// *************************************************************************** *
// *                                                                           *
// *                      Mentor Graphics Corporation                          *
// *                          All rights reserved                              *
// *                                                                           *
// *************************************************************************** *
// *                                                                           *
// * Description:         CANDB File                                           *
// * Generated at:        2020-04-14 13:10:23                                  *
// * System:              SDB20010                                             *
// * Variant:             EX11_AVP                                             *
// * Network:             ChassisCAN1                                          *
// *                                                                           *
// *************************************************************************** *
// *                                                                           *
// *             THIS CONFIGURATION MIGHT CONTAIN SOME ERRORS                  *
// *              IF THE INPUT MODEL WAS NOT PROPERLY FORMED!                  *
// *                    Do Not Use this File directly!                         *
// *                                                                           *
// *************************************************************************** *
VERSION "ChassisCAN1"

NS_ :

BS_:

BU_:  ASDM ECM ETC MVEM PAS PSCM1 SAS TCM VDDM

BO_ 293 TcmChas1Fr05: 8 TCM
 SG_ TrsmCluOpen1 : 24|1@0+ (1,0) [0|1] "" ECM
 SG_ TrsmCluOpen1_UB : 25|1@0+ (1,0) [0|1] "" ECM
 SG_ TrsmCluOpen2 : 26|1@0+ (1,0) [0|1] "" ECM
 SG_ TrsmCluOpen2_UB : 27|1@0+ (1,0) [0|1] "" ECM
 SG_ TrsmEcuTLvl : 29|2@0+ (1,0) [0|3] "" ECM
 SG_ TrsmEcuTLvl_UB : 7|1@0+ (1,0) [0|1] "" ECM
 SG_ TrsmGearSafe_UB : 6|1@0+ (1,0) [0|1] "" ECM
 SG_ TrsmGearSafeAct1 : 15|4@0+ (1,0) [0|15] "" ECM
 SG_ TrsmGearSafeAct2 : 11|4@0+ (1,0) [0|15] "" ECM
 SG_ TrsmGearSafeChks : 23|8@0+ (1.0,0.0) [0.0|255.0] "Unitless" ECM
 SG_ TrsmGearSafeCntr : 3|4@0+ (1.0,0.0) [0.0|15.0] "Unitless" ECM
 SG_ TrsmGearSafeSts1 : 4|1@0+ (1,0) [0|1] "" ECM
 SG_ TrsmGearSafeSts2 : 5|1@0+ (1,0) [0|1] "" ECM
 SG_ TrsmSailSts_UB : 47|1@0+ (1,0) [0|1] "" ECM
 SG_ TrsmSailStsTrsmEngSyncSpd : 55|16@0+ (1.0,0.0) [0.0|65534.0] "rpm" ECM
 SG_ TrsmSailStsTrsmSailAllwd : 46|1@0+ (1,0) [0|1] "" ECM
 SG_ TrsmSailStsTrsmShiftMapForIsg : 42|3@0+ (1,0) [0|7] "" ECM
 SG_ TrsmSailStsTrsmSts : 45|3@0+ (1,0) [0|7] "" ECM

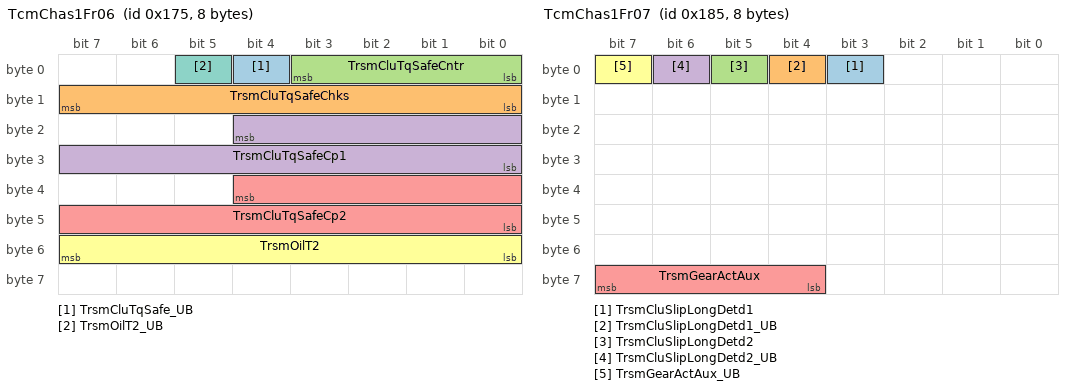
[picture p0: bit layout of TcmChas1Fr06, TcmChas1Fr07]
BO_ 373 TcmChas1Fr06: 8 TCM
 SG_ TrsmCluTqSafe_UB : 4|1@0+ (1,0) [0|1] "" ECM
 SG_ TrsmCluTqSafeChks : 15|8@0+ (1.0,0.0) [0.0|255.0] "Unitless" ECM
 SG_ TrsmCluTqSafeCntr : 3|4@0+ (1.0,0.0) [0.0|15.0] "Unitless" ECM
 SG_ TrsmCluTqSafeCp1 : 20|13@0+ (0.1,-5.0) [-5.0|814.1] "NewtonMeter" ECM
 SG_ TrsmCluTqSafeCp2 : 36|13@0+ (0.1,-5.0) [-5.0|814.1] "NewtonMeter" ECM
 SG_ TrsmOilT2 : 55|8@0+ (1.0,-60.0) [-60.0|195.0] "degC" ECM,VDDM
 SG_ TrsmOilT2_UB : 5|1@0+ (1,0) [0|1] "" ECM,VDDM

BO_ 389 TcmChas1Fr07: 8 TCM
 SG_ TrsmCluSlipLongDetd1 : 3|1@0+ (1,0) [0|1] "" ECM
 SG_ TrsmCluSlipLongDetd1_UB : 4|1@0+ (1,0) [0|1] "" ECM
 SG_ TrsmCluSlipLongDetd2 : 5|1@0+ (1,0) [0|1] "" ECM
 SG_ TrsmCluSlipLongDetd2_UB : 6|1@0+ (1,0) [0|1] "" ECM
 SG_ TrsmGearActAux : 63|4@0+ (1,0) [0|15] "" ECM
 SG_ TrsmGearActAux_UB : 7|1@0+ (1,0) [0|1] "" ECM

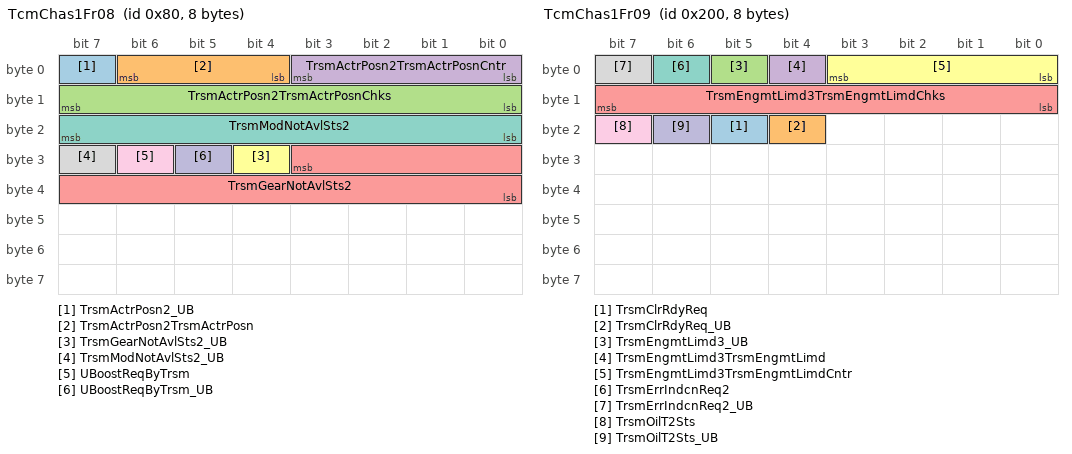
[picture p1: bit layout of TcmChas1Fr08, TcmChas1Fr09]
BO_ 128 TcmChas1Fr08: 8 TCM
 SG_ TrsmActrPosn2_UB : 7|1@0+ (1,0) [0|1] "" ECM
 SG_ TrsmActrPosn2TrsmActrPosn : 6|3@0+ (1,0) [0|7] "" ECM
 SG_ TrsmActrPosn2TrsmActrPosnChks : 15|8@0+ (1.0,0.0) [0.0|255.0] "Unitless" ECM
 SG_ TrsmActrPosn2TrsmActrPosnCntr : 3|4@0+ (1.0,0.0) [0.0|15.0] "Unitless" ECM
 SG_ TrsmGearNotAvlSts2 : 27|12@0+ (1.0,0.0) [0.0|4095.0] "Unitless" ECM
 SG_ TrsmGearNotAvlSts2_UB : 28|1@0+ (1,0) [0|1] "" ECM
 SG_ TrsmModNotAvlSts2 : 23|8@0+ (1.0,0.0) [0.0|255.0] "Unitless" ECM
 SG_ TrsmModNotAvlSts2_UB : 31|1@0+ (1,0) [0|1] "" ECM
 SG_ UBoostReqByTrsm : 30|1@0+ (1,0) [0|1] "" ECM
 SG_ UBoostReqByTrsm_UB : 29|1@0+ (1,0) [0|1] "" ECM

BO_ 512 TcmChas1Fr09: 8 TCM
 SG_ TrsmClrRdyReq : 21|1@0+ (1,0) [0|1] "" ECM
 SG_ TrsmClrRdyReq_UB : 20|1@0+ (1,0) [0|1] "" ECM
 SG_ TrsmEngmtLimd3_UB : 5|1@0+ (1,0) [0|1] "" ECM
 SG_ TrsmEngmtLimd3TrsmEngmtLimd : 4|1@0+ (1,0) [0|1] "" ECM
 SG_ TrsmEngmtLimd3TrsmEngmtLimdChks : 15|8@0+ (1.0,0.0) [0.0|255.0] "Unitless" ECM
 SG_ TrsmEngmtLimd3TrsmEngmtLimdCntr : 3|4@0+ (1.0,0.0) [0.0|15.0] "Unitless" ECM
 SG_ TrsmErrIndcnReq2 : 6|1@0+ (1,0) [0|1] "" ECM
 SG_ TrsmErrIndcnReq2_UB : 7|1@0+ (1,0) [0|1] "" ECM
 SG_ TrsmOilT2Sts : 23|1@0+ (1,0) [0|1] "" ECM
 SG_ TrsmOilT2Sts_UB : 22|1@0+ (1,0) [0|1] "" ECM

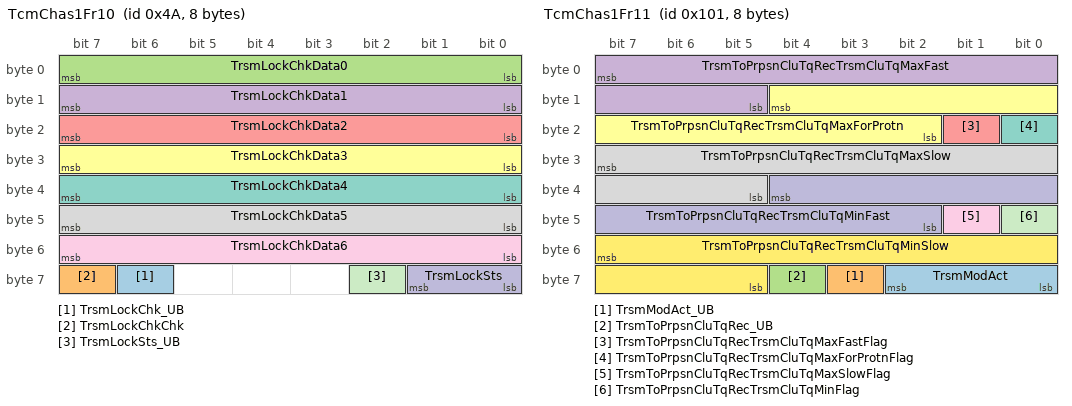
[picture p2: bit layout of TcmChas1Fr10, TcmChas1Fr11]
BO_ 74 TcmChas1Fr10: 8 TCM
 SG_ TrsmLockChk_UB : 62|1@0+ (1,0) [0|1] "" VDDM
 SG_ TrsmLockChkChk : 63|1@0+ (1,0) [0|1] "" VDDM
 SG_ TrsmLockChkData0 : 7|8@0+ (1.0,0.0) [0.0|255.0] "Unitless" VDDM
 SG_ TrsmLockChkData1 : 15|8@0+ (1.0,0.0) [0.0|255.0] "Unitless" VDDM
 SG_ TrsmLockChkData2 : 23|8@0+ (1.0,0.0) [0.0|255.0] "Unitless" VDDM
 SG_ TrsmLockChkData3 : 31|8@0+ (1.0,0.0) [0.0|255.0] "Unitless" VDDM
 SG_ TrsmLockChkData4 : 39|8@0+ (1.0,0.0) [0.0|255.0] "Unitless" VDDM
 SG_ TrsmLockChkData5 : 47|8@0+ (1.0,0.0) [0.0|255.0] "Unitless" VDDM
 SG_ TrsmLockChkData6 : 55|8@0+ (1.0,0.0) [0.0|255.0] "Unitless" VDDM
 SG_ TrsmLockSts : 57|2@0+ (1,0) [0|3] "" VDDM
 SG_ TrsmLockSts_UB : 58|1@0+ (1,0) [0|1] "" VDDM

BO_ 257 TcmChas1Fr11: 8 TCM
 SG_ TrsmModAct : 58|3@0+ (1,0) [0|7] "" ECM
 SG_ TrsmModAct_UB : 59|1@0+ (1,0) [0|1] "" ECM
 SG_ TrsmToPrpsnCluTqRec_UB : 60|1@0+ (1,0) [0|1] "" ECM
 SG_ TrsmToPrpsnCluTqRecTrsmCluTqMaxFast : 7|11@0+ (1.0,-1024.0) [-1024.0|1023.0] "NewtonMeter" ECM
 SG_ TrsmToPrpsnCluTqRecTrsmCluTqMaxFastFlag : 17|1@0+ (1,0) [0|1] "" ECM
 SG_ TrsmToPrpsnCluTqRecTrsmCluTqMaxForProtn : 12|11@0+ (1.0,-1024.0) [-1024.0|1023.0] "NewtonMeter" ECM
 SG_ TrsmToPrpsnCluTqRecTrsmCluTqMaxForProtnFlag : 16|1@0+ (1,0) [0|1] "" ECM
 SG_ TrsmToPrpsnCluTqRecTrsmCluTqMaxSlow : 31|11@0+ (1.0,-1024.0) [-1024.0|1023.0] "NewtonMeter" ECM
 SG_ TrsmToPrpsnCluTqRecTrsmCluTqMaxSlowFlag : 41|1@0+ (1,0) [0|1] "" ECM
 SG_ TrsmToPrpsnCluTqRecTrsmCluTqMinFast : 36|11@0+ (1.0,-1024.0) [-1024.0|1023.0] "NewtonMeter" ECM
 SG_ TrsmToPrpsnCluTqRecTrsmCluTqMinFlag : 40|1@0+ (1,0) [0|1] "" ECM
 SG_ TrsmToPrpsnCluTqRecTrsmCluTqMinSlow : 55|11@0+ (1.0,-1024.0) [-1024.0|1023.0] "NewtonMeter" ECM

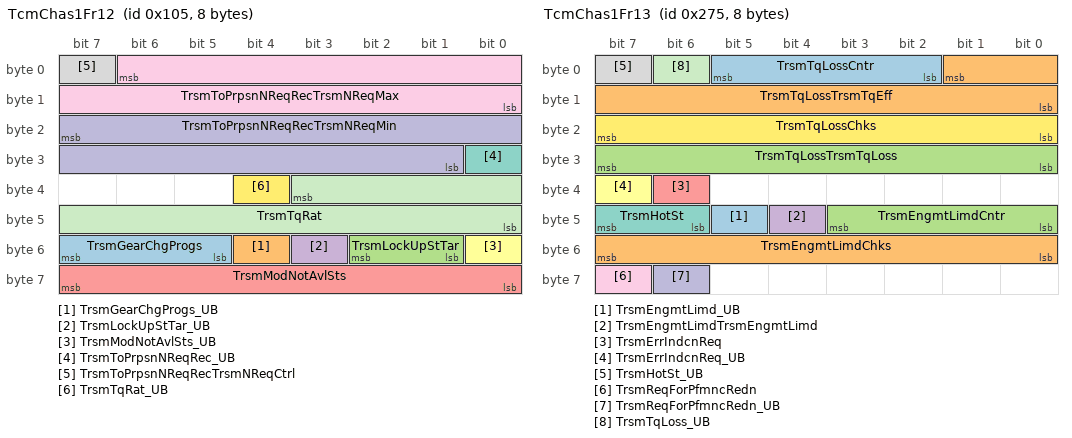
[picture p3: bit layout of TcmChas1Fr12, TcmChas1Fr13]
BO_ 261 TcmChas1Fr12: 8 TCM
 SG_ TrsmGearChgProgs : 55|3@0+ (1,0) [0|7] "" ECM
 SG_ TrsmGearChgProgs_UB : 52|1@0+ (1,0) [0|1] "" ECM
 SG_ TrsmLockUpStTar : 50|2@0+ (1,0) [0|3] "" ECM
 SG_ TrsmLockUpStTar_UB : 51|1@0+ (1,0) [0|1] "" ECM
 SG_ TrsmModNotAvlSts : 63|8@0+ (1.0,0.0) [0.0|255.0] "Unitless" ECM
 SG_ TrsmModNotAvlSts_UB : 48|1@0+ (1,0) [0|1] "" ECM
 SG_ TrsmToPrpsnNReqRec_UB : 24|1@0+ (1,0) [0|1] "" ECM
 SG_ TrsmToPrpsnNReqRecTrsmNReqCtrl : 7|1@0+ (1,0) [0|1] "" ECM
 SG_ TrsmToPrpsnNReqRecTrsmNReqMax : 6|15@0+ (0.5,0.0) [0.0|16383.5] "rpm" ECM
 SG_ TrsmToPrpsnNReqRecTrsmNReqMin : 23|15@0+ (0.5,0.0) [0.0|16383.5] "rpm" ECM
 SG_ TrsmTqRat : 35|12@0+ (0.01,0.0) [0.0|40.95] "Unitless" ECM,VDDM
 SG_ TrsmTqRat_UB : 36|1@0+ (1,0) [0|1] "" ECM,VDDM

BO_ 629 TcmChas1Fr13: 8 TCM
 SG_ TrsmEngmtLimd_UB : 45|1@0+ (1,0) [0|1] "" ECM
 SG_ TrsmEngmtLimdChks : 55|8@0+ (1.0,0.0) [0.0|255.0] "Unitless" ECM
 SG_ TrsmEngmtLimdCntr : 43|4@0+ (1.0,0.0) [0.0|15.0] "Unitless" ECM
 SG_ TrsmEngmtLimdTrsmEngmtLimd : 44|1@0+ (1,0) [0|1] "" ECM
 SG_ TrsmErrIndcnReq : 38|1@0+ (1,0) [0|1] "" ECM
 SG_ TrsmErrIndcnReq_UB : 39|1@0+ (1,0) [0|1] "" ECM
 SG_ TrsmHotSt : 47|2@0+ (1,0) [0|3] "" ECM
 SG_ TrsmHotSt_UB : 7|1@0+ (1,0) [0|1] "" ECM
 SG_ TrsmReqForPfmncRedn : 63|1@0+ (1,0) [0|1] "" ECM
 SG_ TrsmReqForPfmncRedn_UB : 62|1@0+ (1,0) [0|1] "" ECM
 SG_ TrsmTqLoss_UB : 6|1@0+ (1,0) [0|1] "" ECM,VDDM
 SG_ TrsmTqLossChks : 23|8@0+ (1.0,0.0) [0.0|255.0] "Unitless" ECM,VDDM
 SG_ TrsmTqLossCntr : 5|4@0+ (1.0,0.0) [0.0|15.0] "Unitless" ECM,VDDM
 SG_ TrsmTqLossTrsmTqEff : 1|10@0+ (0.1,0.0) [0.0|100.0] "%" ECM,VDDM
 SG_ TrsmTqLossTrsmTqLoss : 31|8@0+ (0.5,0.0) [0.0|127.0] "Unitless" ECM,VDDM

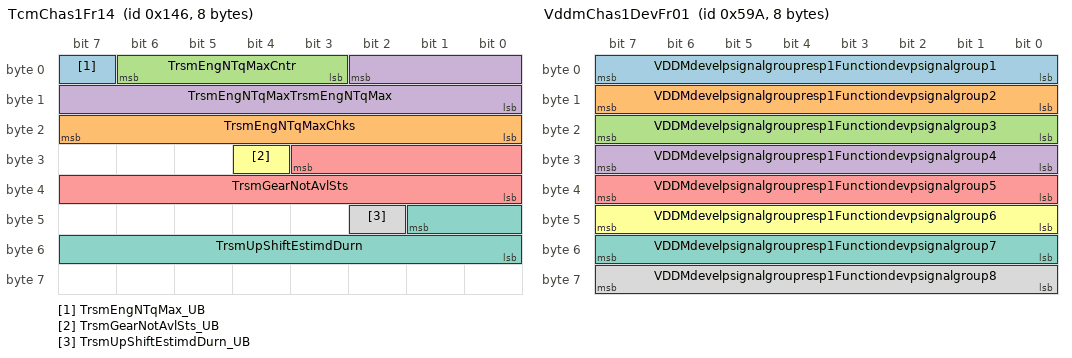
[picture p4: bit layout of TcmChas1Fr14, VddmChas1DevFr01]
BO_ 326 TcmChas1Fr14: 8 TCM
 SG_ TrsmEngNTqMax_UB : 7|1@0+ (1,0) [0|1] "" ECM
 SG_ TrsmEngNTqMaxChks : 23|8@0+ (1.0,0.0) [0.0|255.0] "Unitless" ECM
 SG_ TrsmEngNTqMaxCntr : 6|4@0+ (1.0,0.0) [0.0|15.0] "Unitless" ECM
 SG_ TrsmEngNTqMaxTrsmEngNTqMax : 2|11@0+ (1.0,-1024.0) [-1024.0|1023.0] "NewtonMeter" ECM
 SG_ TrsmGearNotAvlSts : 27|12@0+ (1.0,0.0) [0.0|4095.0] "Unitless" ECM
 SG_ TrsmGearNotAvlSts_UB : 28|1@0+ (1,0) [0|1] "" ECM
 SG_ TrsmUpShiftEstimdDurn : 41|10@0+ (10.0,0.0) [0.0|10230.0] "Milliseconds" ECM
 SG_ TrsmUpShiftEstimdDurn_UB : 42|1@0+ (1,0) [0|1] "" ECM

BO_ 263 TcmChas1Fr15: 8 TCM
 SG_ TrsmFltIndcn : 52|5@0+ (1,0) [0|31] "" ECM,VDDM
 SG_ TrsmFltIndcn_UB : 53|1@0+ (1,0) [0|1] "" ECM,VDDM

BO_ 763 TCMChas1Fr18: 8 TCM
 SG_ VFCVectorTCMAWBlockID : 1|2@0+ (1.0,0.0) [0.0|3.0] "Unitless" VDDM
 SG_ VFCVectorTCMAWVFCid0 : 2|1@0+ (1,0) [0|1] "" VDDM
 SG_ VFCVectorTCMAWVFCid1 : 3|1@0+ (1,0) [0|1] "" VDDM
 SG_ VFCVectorTCMAWVFCid10 : 12|1@0+ (1,0) [0|1] "" VDDM
 SG_ VFCVectorTCMAWVFCid11 : 13|1@0+ (1,0) [0|1] "" VDDM
 SG_ VFCVectorTCMAWVFCid12 : 14|1@0+ (1,0) [0|1] "" VDDM
 SG_ VFCVectorTCMAWVFCid13 : 15|1@0+ (1,0) [0|1] "" VDDM
 SG_ VFCVectorTCMAWVFCid14 : 16|1@0+ (1,0) [0|1] "" VDDM
 SG_ VFCVectorTCMAWVFCid15 : 17|1@0+ (1,0) [0|1] "" VDDM
 SG_ VFCVectorTCMAWVFCid16 : 18|1@0+ (1,0) [0|1] "" VDDM
 SG_ VFCVectorTCMAWVFCid17 : 19|1@0+ (1,0) [0|1] "" VDDM
 SG_ VFCVectorTCMAWVFCid18 : 20|1@0+ (1,0) [0|1] "" VDDM
 SG_ VFCVectorTCMAWVFCid19 : 21|1@0+ (1,0) [0|1] "" VDDM
 SG_ VFCVectorTCMAWVFCid2 : 4|1@0+ (1,0) [0|1] "" VDDM
 SG_ VFCVectorTCMAWVFCid20 : 22|1@0+ (1,0) [0|1] "" VDDM
 SG_ VFCVectorTCMAWVFCid21 : 23|1@0+ (1,0) [0|1] "" VDDM
 SG_ VFCVectorTCMAWVFCid22 : 24|1@0+ (1,0) [0|1] "" VDDM
 SG_ VFCVectorTCMAWVFCid23 : 25|1@0+ (1,0) [0|1] "" VDDM
 SG_ VFCVectorTCMAWVFCid24 : 26|1@0+ (1,0) [0|1] "" VDDM
 SG_ VFCVectorTCMAWVFCid25 : 27|1@0+ (1,0) [0|1] "" VDDM
 SG_ VFCVectorTCMAWVFCid26 : 28|1@0+ (1,0) [0|1] "" VDDM
 SG_ VFCVectorTCMAWVFCid27 : 29|1@0+ (1,0) [0|1] "" VDDM
 SG_ VFCVectorTCMAWVFCid28 : 30|1@0+ (1,0) [0|1] "" VDDM
 SG_ VFCVectorTCMAWVFCid29 : 31|1@0+ (1,0) [0|1] "" VDDM
 SG_ VFCVectorTCMAWVFCid3 : 5|1@0+ (1,0) [0|1] "" VDDM
 SG_ VFCVectorTCMAWVFCid30 : 32|1@0+ (1,0) [0|1] "" VDDM
 SG_ VFCVectorTCMAWVFCid31 : 33|1@0+ (1,0) [0|1] "" VDDM
 SG_ VFCVectorTCMAWVFCid32 : 34|1@0+ (1,0) [0|1] "" VDDM
 SG_ VFCVectorTCMAWVFCid33 : 35|1@0+ (1,0) [0|1] "" VDDM
 SG_ VFCVectorTCMAWVFCid34 : 36|1@0+ (1,0) [0|1] "" VDDM
 SG_ VFCVectorTCMAWVFCid35 : 37|1@0+ (1,0) [0|1] "" VDDM
 SG_ VFCVectorTCMAWVFCid36 : 38|1@0+ (1,0) [0|1] "" VDDM
 SG_ VFCVectorTCMAWVFCid37 : 39|1@0+ (1,0) [0|1] "" VDDM
 SG_ VFCVectorTCMAWVFCid38 : 40|1@0+ (1,0) [0|1] "" VDDM
 SG_ VFCVectorTCMAWVFCid39 : 41|1@0+ (1,0) [0|1] "" VDDM
 SG_ VFCVectorTCMAWVFCid4 : 6|1@0+ (1,0) [0|1] "" VDDM
 SG_ VFCVectorTCMAWVFCid40 : 42|1@0+ (1,0) [0|1] "" VDDM
 SG_ VFCVectorTCMAWVFCid41 : 43|1@0+ (1,0) [0|1] "" VDDM
 SG_ VFCVectorTCMAWVFCid42 : 44|1@0+ (1,0) [0|1] "" VDDM
 SG_ VFCVectorTCMAWVFCid43 : 45|1@0+ (1,0) [0|1] "" VDDM
 SG_ VFCVectorTCMAWVFCid44 : 46|1@0+ (1,0) [0|1] "" VDDM
 SG_ VFCVectorTCMAWVFCid45 : 47|1@0+ (1,0) [0|1] "" VDDM
 SG_ VFCVectorTCMAWVFCid46 : 48|1@0+ (1,0) [0|1] "" VDDM
 SG_ VFCVectorTCMAWVFCid47 : 49|1@0+ (1,0) [0|1] "" VDDM
 SG_ VFCVectorTCMAWVFCid48 : 50|1@0+ (1,0) [0|1] "" VDDM
 SG_ VFCVectorTCMAWVFCid49 : 51|1@0+ (1,0) [0|1] "" VDDM
 SG_ VFCVectorTCMAWVFCid5 : 7|1@0+ (1,0) [0|1] "" VDDM
 SG_ VFCVectorTCMAWVFCid50 : 52|1@0+ (1,0) [0|1] "" VDDM
 SG_ VFCVectorTCMAWVFCid51 : 53|1@0+ (1,0) [0|1] "" VDDM
 SG_ VFCVectorTCMAWVFCid52 : 54|1@0+ (1,0) [0|1] "" VDDM
 SG_ VFCVectorTCMAWVFCid53 : 55|1@0+ (1,0) [0|1] "" VDDM
 SG_ VFCVectorTCMAWVFCid54 : 56|1@0+ (1,0) [0|1] "" VDDM
 SG_ VFCVectorTCMAWVFCid55 : 57|1@0+ (1,0) [0|1] "" VDDM
 SG_ VFCVectorTCMAWVFCid56 : 58|1@0+ (1,0) [0|1] "" VDDM
 SG_ VFCVectorTCMAWVFCid57 : 59|1@0+ (1,0) [0|1] "" VDDM
 SG_ VFCVectorTCMAWVFCid58 : 60|1@0+ (1,0) [0|1] "" VDDM
 SG_ VFCVectorTCMAWVFCid59 : 61|1@0+ (1,0) [0|1] "" VDDM
 SG_ VFCVectorTCMAWVFCid6 : 8|1@0+ (1,0) [0|1] "" VDDM
 SG_ VFCVectorTCMAWVFCid60 : 62|1@0+ (1,0) [0|1] "" VDDM
 SG_ VFCVectorTCMAWVFCid61 : 63|1@0+ (1,0) [0|1] "" VDDM
 SG_ VFCVectorTCMAWVFCid7 : 9|1@0+ (1,0) [0|1] "" VDDM
 SG_ VFCVectorTCMAWVFCid8 : 10|1@0+ (1,0) [0|1] "" VDDM
 SG_ VFCVectorTCMAWVFCid9 : 11|1@0+ (1,0) [0|1] "" VDDM

BO_ 1328 TcmChas1NMFr: 8 TCM
 SG_ PNC16_TCM : 16|1@0+ (1,0) [0|0] "" SAS
 SG_ PNC17_TCM : 17|1@0+ (1,0) [0|0] "" SAS
 SG_ PNC18_TCM : 18|1@0+ (1,0) [0|0] "" SAS
 SG_ PNC19_TCM : 19|1@0+ (1,0) [0|0] "" SAS
 SG_ PNC20_TCM : 20|1@0+ (1,0) [0|0] "" SAS
 SG_ PNC21_TCM : 21|1@0+ (1,0) [0|0] "" SAS
 SG_ PNC22_TCM : 22|1@0+ (1,0) [0|0] "" SAS
 SG_ PNC23_TCM : 23|1@0+ (1,0) [0|0] "" SAS
 SG_ PNC24_TCM : 24|1@0+ (1,0) [0|0] "" SAS
 SG_ PNC25_TCM : 25|1@0+ (1,0) [0|0] "" SAS
 SG_ PNC26_TCM : 26|1@0+ (1,0) [0|0] "" SAS
 SG_ PNC27_TCM : 27|1@0+ (1,0) [0|0] "" SAS
 SG_ PNC28_TCM : 28|1@0+ (1,0) [0|0] "" SAS
 SG_ PNC29_TCM : 29|1@0+ (1,0) [0|0] "" SAS
 SG_ PNC30_TCM : 30|1@0+ (1,0) [0|0] "" SAS
 SG_ PNC31_TCM : 31|1@0+ (1,0) [0|0] "" SAS
 SG_ PNC32_TCM : 32|1@0+ (1,0) [0|0] "" SAS
 SG_ PNC33_TCM : 33|1@0+ (1,0) [0|0] "" SAS
 SG_ PNC34_TCM : 34|1@0+ (1,0) [0|0] "" SAS
 SG_ PNC35_TCM : 35|1@0+ (1,0) [0|0] "" SAS
 SG_ PNC36_TCM : 36|1@0+ (1,0) [0|0] "" SAS
 SG_ PNC37_TCM : 37|1@0+ (1,0) [0|0] "" SAS
 SG_ PNC38_TCM : 38|1@0+ (1,0) [0|0] "" SAS
 SG_ PNC39_TCM : 39|1@0+ (1,0) [0|0] "" SAS
 SG_ NM_PNI_TCM : 14|1@0+ (1,0) [0|0] "" SAS
 SG_ NM_AW_TCM : 12|1@0+ (1,0) [0|0] "" SAS
 SG_ NM_CS_TCM : 11|1@0+ (1,0) [0|0] "" SAS
 SG_ NM_RMR_TCM : 8|1@0+ (1,0) [0|0] "" SAS
 SG_ NM_NodeID_TCM : 7|8@0+ (1,0) [0|0] "" SAS

BO_ 1352 TCMChas1VFCVectorFr: 8 TCM
 SG_ VFCVectorTCMBlockID : 1|2@0+ (1.0,0.0) [0.0|3.0] "Unitless" ETC
 SG_ VFCVectorTCMVFCid0 : 2|1@0+ (1,0) [0|1] "" ETC
 SG_ VFCVectorTCMVFCid1 : 3|1@0+ (1,0) [0|1] "" ETC
 SG_ VFCVectorTCMVFCid10 : 12|1@0+ (1,0) [0|1] "" ETC
 SG_ VFCVectorTCMVFCid11 : 13|1@0+ (1,0) [0|1] "" ETC
 SG_ VFCVectorTCMVFCid12 : 14|1@0+ (1,0) [0|1] "" ETC
 SG_ VFCVectorTCMVFCid13 : 15|1@0+ (1,0) [0|1] "" ETC
 SG_ VFCVectorTCMVFCid14 : 16|1@0+ (1,0) [0|1] "" ETC
 SG_ VFCVectorTCMVFCid15 : 17|1@0+ (1,0) [0|1] "" ETC
 SG_ VFCVectorTCMVFCid16 : 18|1@0+ (1,0) [0|1] "" ETC
 SG_ VFCVectorTCMVFCid17 : 19|1@0+ (1,0) [0|1] "" ETC
 SG_ VFCVectorTCMVFCid18 : 20|1@0+ (1,0) [0|1] "" ETC
 SG_ VFCVectorTCMVFCid19 : 21|1@0+ (1,0) [0|1] "" ETC
 SG_ VFCVectorTCMVFCid2 : 4|1@0+ (1,0) [0|1] "" ETC
 SG_ VFCVectorTCMVFCid20 : 22|1@0+ (1,0) [0|1] "" ETC
 SG_ VFCVectorTCMVFCid21 : 23|1@0+ (1,0) [0|1] "" ETC
 SG_ VFCVectorTCMVFCid22 : 24|1@0+ (1,0) [0|1] "" ETC
 SG_ VFCVectorTCMVFCid23 : 25|1@0+ (1,0) [0|1] "" ETC
 SG_ VFCVectorTCMVFCid24 : 26|1@0+ (1,0) [0|1] "" ETC
 SG_ VFCVectorTCMVFCid25 : 27|1@0+ (1,0) [0|1] "" ETC
 SG_ VFCVectorTCMVFCid26 : 28|1@0+ (1,0) [0|1] "" ETC
 SG_ VFCVectorTCMVFCid27 : 29|1@0+ (1,0) [0|1] "" ETC
 SG_ VFCVectorTCMVFCid28 : 30|1@0+ (1,0) [0|1] "" ETC
 SG_ VFCVectorTCMVFCid29 : 31|1@0+ (1,0) [0|1] "" ETC
 SG_ VFCVectorTCMVFCid3 : 5|1@0+ (1,0) [0|1] "" ETC
 SG_ VFCVectorTCMVFCid30 : 32|1@0+ (1,0) [0|1] "" ETC
 SG_ VFCVectorTCMVFCid31 : 33|1@0+ (1,0) [0|1] "" ETC
 SG_ VFCVectorTCMVFCid32 : 34|1@0+ (1,0) [0|1] "" ETC
 SG_ VFCVectorTCMVFCid33 : 35|1@0+ (1,0) [0|1] "" ETC
 SG_ VFCVectorTCMVFCid34 : 36|1@0+ (1,0) [0|1] "" ETC
 SG_ VFCVectorTCMVFCid35 : 37|1@0+ (1,0) [0|1] "" ETC
 SG_ VFCVectorTCMVFCid36 : 38|1@0+ (1,0) [0|1] "" ETC
 SG_ VFCVectorTCMVFCid37 : 39|1@0+ (1,0) [0|1] "" ETC
 SG_ VFCVectorTCMVFCid38 : 40|1@0+ (1,0) [0|1] "" ETC
 SG_ VFCVectorTCMVFCid39 : 41|1@0+ (1,0) [0|1] "" ETC
 SG_ VFCVectorTCMVFCid4 : 6|1@0+ (1,0) [0|1] "" ETC
 SG_ VFCVectorTCMVFCid40 : 42|1@0+ (1,0) [0|1] "" ETC
 SG_ VFCVectorTCMVFCid41 : 43|1@0+ (1,0) [0|1] "" ETC
 SG_ VFCVectorTCMVFCid42 : 44|1@0+ (1,0) [0|1] "" ETC
 SG_ VFCVectorTCMVFCid43 : 45|1@0+ (1,0) [0|1] "" ETC
 SG_ VFCVectorTCMVFCid44 : 46|1@0+ (1,0) [0|1] "" ETC
 SG_ VFCVectorTCMVFCid45 : 47|1@0+ (1,0) [0|1] "" ETC
 SG_ VFCVectorTCMVFCid46 : 48|1@0+ (1,0) [0|1] "" ETC
 SG_ VFCVectorTCMVFCid47 : 49|1@0+ (1,0) [0|1] "" ETC
 SG_ VFCVectorTCMVFCid48 : 50|1@0+ (1,0) [0|1] "" ETC
 SG_ VFCVectorTCMVFCid49 : 51|1@0+ (1,0) [0|1] "" ETC
 SG_ VFCVectorTCMVFCid5 : 7|1@0+ (1,0) [0|1] "" ETC
 SG_ VFCVectorTCMVFCid50 : 52|1@0+ (1,0) [0|1] "" ETC
 SG_ VFCVectorTCMVFCid51 : 53|1@0+ (1,0) [0|1] "" ETC
 SG_ VFCVectorTCMVFCid52 : 54|1@0+ (1,0) [0|1] "" ETC
 SG_ VFCVectorTCMVFCid53 : 55|1@0+ (1,0) [0|1] "" ETC
 SG_ VFCVectorTCMVFCid54 : 56|1@0+ (1,0) [0|1] "" ETC
 SG_ VFCVectorTCMVFCid55 : 57|1@0+ (1,0) [0|1] "" ETC
 SG_ VFCVectorTCMVFCid56 : 58|1@0+ (1,0) [0|1] "" ETC
 SG_ VFCVectorTCMVFCid57 : 59|1@0+ (1,0) [0|1] "" ETC
 SG_ VFCVectorTCMVFCid58 : 60|1@0+ (1,0) [0|1] "" ETC
 SG_ VFCVectorTCMVFCid59 : 61|1@0+ (1,0) [0|1] "" ETC
 SG_ VFCVectorTCMVFCid6 : 8|1@0+ (1,0) [0|1] "" ETC
 SG_ VFCVectorTCMVFCid60 : 62|1@0+ (1,0) [0|1] "" ETC
 SG_ VFCVectorTCMVFCid61 : 63|1@0+ (1,0) [0|1] "" ETC
 SG_ VFCVectorTCMVFCid7 : 9|1@0+ (1,0) [0|1] "" ETC
 SG_ VFCVectorTCMVFCid8 : 10|1@0+ (1,0) [0|1] "" ETC
 SG_ VFCVectorTCMVFCid9 : 11|1@0+ (1,0) [0|1] "" ETC

BO_ 1408 TcmToEtcXcpFr01: 8 TCM

BO_ 1413 TcmToEtcXcpFr02: 8 TCM

BO_ 1422 VddmBcmtoETCXCPFr01: 8 VDDM

BO_ 1434 VddmChas1DevFr01: 8 VDDM
 SG_ VDDMdevelpsignalgroupresp1Functiondevpsignalgroup1 : 7|8@0+ (1.0,0.0) [0.0|255.0] "Unitless" ETC
 SG_ VDDMdevelpsignalgroupresp1Functiondevpsignalgroup2 : 15|8@0+ (1.0,0.0) [0.0|255.0] "Unitless" ETC
 SG_ VDDMdevelpsignalgroupresp1Functiondevpsignalgroup3 : 23|8@0+ (1.0,0.0) [0.0|255.0] "Unitless" ETC
 SG_ VDDMdevelpsignalgroupresp1Functiondevpsignalgroup4 : 31|8@0+ (1.0,0.0) [0.0|255.0] "Unitless" ETC
 SG_ VDDMdevelpsignalgroupresp1Functiondevpsignalgroup5 : 39|8@0+ (1.0,0.0) [0.0|255.0] "Unitless" ETC
 SG_ VDDMdevelpsignalgroupresp1Functiondevpsignalgroup6 : 47|8@0+ (1.0,0.0) [0.0|255.0] "Unitless" ETC
 SG_ VDDMdevelpsignalgroupresp1Functiondevpsignalgroup7 : 55|8@0+ (1.0,0.0) [0.0|255.0] "Unitless" ETC
 SG_ VDDMdevelpsignalgroupresp1Functiondevpsignalgroup8 : 63|8@0+ (1.0,0.0) [0.0|255.0] "Unitless" ETC

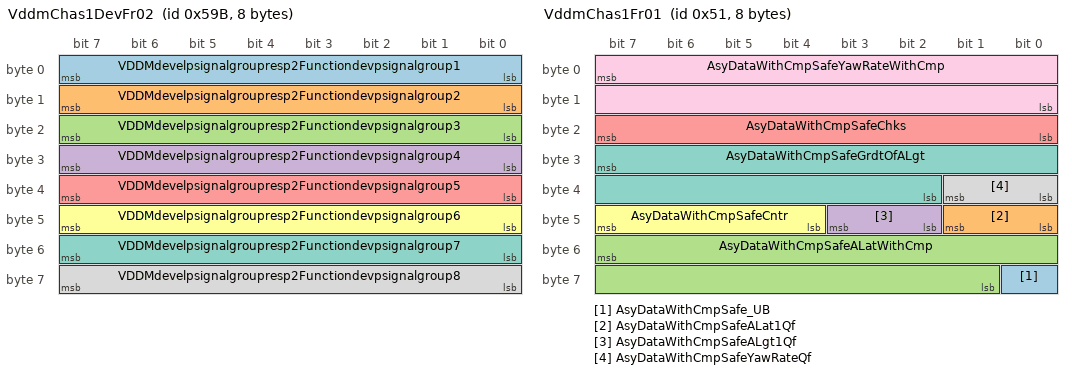
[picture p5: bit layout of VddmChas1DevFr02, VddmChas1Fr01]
BO_ 1435 VddmChas1DevFr02: 8 VDDM
 SG_ VDDMdevelpsignalgroupresp2Functiondevpsignalgroup1 : 7|8@0+ (1.0,0.0) [0.0|255.0] "Unitless" ETC
 SG_ VDDMdevelpsignalgroupresp2Functiondevpsignalgroup2 : 15|8@0+ (1.0,0.0) [0.0|255.0] "Unitless" ETC
 SG_ VDDMdevelpsignalgroupresp2Functiondevpsignalgroup3 : 23|8@0+ (1.0,0.0) [0.0|255.0] "Unitless" ETC
 SG_ VDDMdevelpsignalgroupresp2Functiondevpsignalgroup4 : 31|8@0+ (1.0,0.0) [0.0|255.0] "Unitless" ETC
 SG_ VDDMdevelpsignalgroupresp2Functiondevpsignalgroup5 : 39|8@0+ (1.0,0.0) [0.0|255.0] "Unitless" ETC
 SG_ VDDMdevelpsignalgroupresp2Functiondevpsignalgroup6 : 47|8@0+ (1.0,0.0) [0.0|255.0] "Unitless" ETC
 SG_ VDDMdevelpsignalgroupresp2Functiondevpsignalgroup7 : 55|8@0+ (1.0,0.0) [0.0|255.0] "Unitless" ETC
 SG_ VDDMdevelpsignalgroupresp2Functiondevpsignalgroup8 : 63|8@0+ (1.0,0.0) [0.0|255.0] "Unitless" ETC

BO_ 81 VddmChas1Fr01: 8 VDDM
 SG_ AsyDataWithCmpSafe_UB : 56|1@0+ (1,0) [0|1] "" PSCM1
 SG_ AsyDataWithCmpSafeALat1Qf : 41|2@0+ (1,0) [0|3] "" PSCM1
 SG_ AsyDataWithCmpSafeALatWithCmp : 55|15@0- (0.0085,0.0) [-138.99200000000002|139.00050000000002] "m/s^2" PSCM1
 SG_ AsyDataWithCmpSafeALgt1Qf : 43|2@0+ (1,0) [0|3] "" PSCM1
 SG_ AsyDataWithCmpSafeChks : 23|8@0+ (1.0,0.0) [0.0|255.0] "Unitless" PSCM1
 SG_ AsyDataWithCmpSafeCntr : 47|4@0+ (1.0,0.0) [0.0|15.0] "Unitless" PSCM1
 SG_ AsyDataWithCmpSafeGrdtOfALgt : 31|14@0- (0.00390625,0.0) [-30.0|30.0] "m/s^3" PSCM1
 SG_ AsyDataWithCmpSafeYawRateQf : 33|2@0+ (1,0) [0|3] "" PSCM1
 SG_ AsyDataWithCmpSafeYawRateWithCmp : 7|16@0- (0.000244140625,0.0) [-6.0|6.0] "rad/s" PSCM1

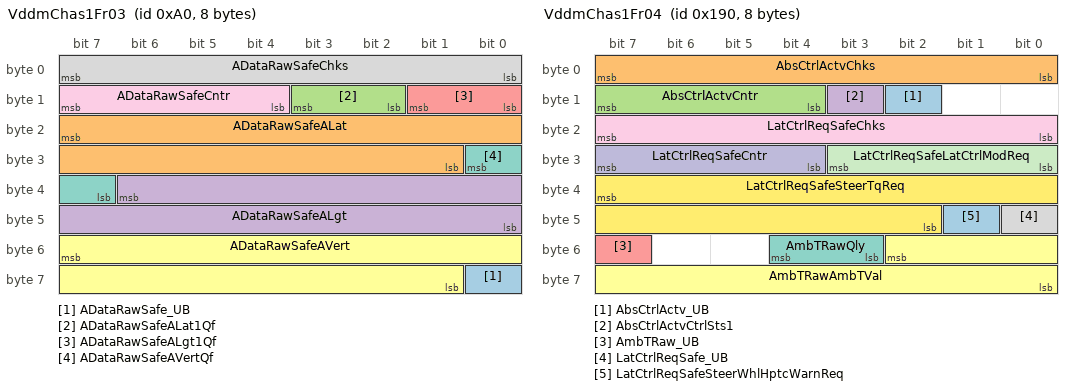
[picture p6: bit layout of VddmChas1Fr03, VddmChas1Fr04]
BO_ 160 VddmChas1Fr03: 8 VDDM
 SG_ ADataRawSafe_UB : 56|1@0+ (1,0) [0|1] "" PSCM1
 SG_ ADataRawSafeALat : 23|15@0- (0.0085,0.0) [-138.99200000000002|139.00050000000002] "m/s^2" PSCM1
 SG_ ADataRawSafeALat1Qf : 11|2@0+ (1,0) [0|3] "" PSCM1
 SG_ ADataRawSafeALgt : 38|15@0- (0.0085,0.0) [-138.99200000000002|139.00050000000002] "m/s^2" PSCM1
 SG_ ADataRawSafeALgt1Qf : 9|2@0+ (1,0) [0|3] "" PSCM1
 SG_ ADataRawSafeAVert : 55|15@0- (0.0085,0.0) [-138.99200000000002|139.00050000000002] "m/s^2" PSCM1
 SG_ ADataRawSafeAVertQf : 24|2@0+ (1,0) [0|3] "" PSCM1
 SG_ ADataRawSafeChks : 7|8@0+ (1.0,0.0) [0.0|255.0] "Unitless" PSCM1
 SG_ ADataRawSafeCntr : 15|4@0+ (1.0,0.0) [0.0|15.0] "Unitless" PSCM1

BO_ 400 VddmChas1Fr04: 8 VDDM
 SG_ AbsCtrlActv_UB : 10|1@0+ (1,0) [0|1] "" ECM,PSCM1
 SG_ AbsCtrlActvChks : 7|8@0+ (1.0,0.0) [0.0|255.0] "Unitless" ECM,PSCM1
 SG_ AbsCtrlActvCntr : 15|4@0+ (1.0,0.0) [0.0|15.0] "Unitless" ECM,PSCM1
 SG_ AbsCtrlActvCtrlSts1 : 11|1@0+ (1,0) [0|1] "" ECM,PSCM1
 SG_ AmbTRaw_UB : 55|1@0+ (1,0) [0|1] "" MVEM,PSCM1
 SG_ AmbTRawAmbTVal : 50|11@0+ (0.1,-70.0) [-70.0|134.70000000000002] "degC" MVEM,PSCM1
 SG_ AmbTRawQly : 52|2@0+ (1,0) [0|3] "" MVEM,PSCM1
 SG_ LatCtrlReqSafe_UB : 40|1@0+ (1,0) [0|1] "" PSCM1
 SG_ LatCtrlReqSafeChks : 23|8@0+ (1.0,0.0) [0.0|255.0] "Unitless" PSCM1
 SG_ LatCtrlReqSafeCntr : 31|4@0+ (1.0,0.0) [0.0|15.0] "Unitless" PSCM1
 SG_ LatCtrlReqSafeLatCtrlModReq : 27|4@0+ (1,0) [0|15] "" PSCM1
 SG_ LatCtrlReqSafeSteerTqReq : 39|14@0- (0.00390625,0.0) [-30.0|30.0] "NewtonMeter" PSCM1
 SG_ LatCtrlReqSafeSteerWhlHptcWarnReq : 41|1@0+ (1,0) [0|1] "" PSCM1

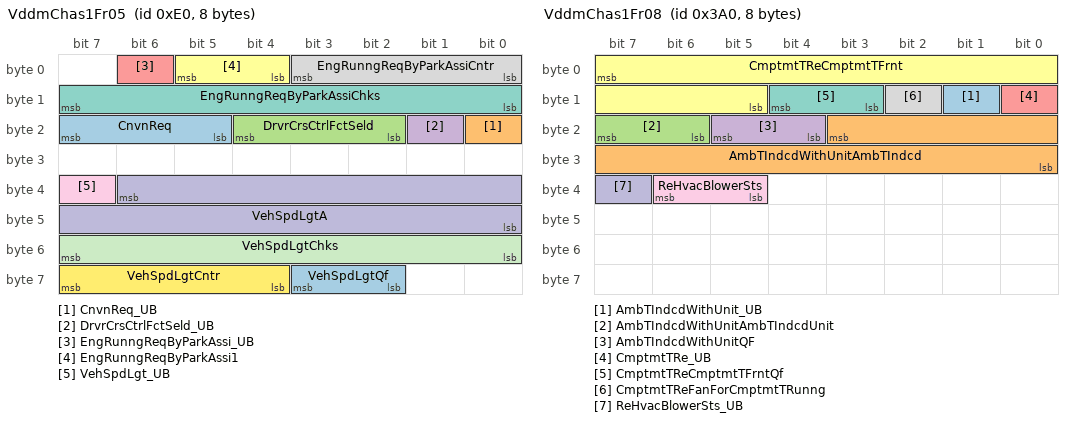
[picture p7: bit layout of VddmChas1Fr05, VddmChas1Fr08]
BO_ 224 VddmChas1Fr05: 8 VDDM
 SG_ CnvnReq : 23|3@0+ (1,0) [0|7] "" ECM
 SG_ CnvnReq_UB : 16|1@0+ (1,0) [0|1] "" ECM
 SG_ DrvrCrsCtrlFctSeld : 20|3@0+ (1,0) [0|7] "" ECM
 SG_ DrvrCrsCtrlFctSeld_UB : 17|1@0+ (1,0) [0|1] "" ECM
 SG_ EngRunngReqByParkAssi_UB : 6|1@0+ (1,0) [0|1] "" ECM
 SG_ EngRunngReqByParkAssi1 : 5|2@0+ (1,0) [0|3] "" ECM
 SG_ EngRunngReqByParkAssiChks : 15|8@0+ (1.0,0.0) [0.0|255.0] "Unitless" ECM
 SG_ EngRunngReqByParkAssiCntr : 3|4@0+ (1.0,0.0) [0.0|15.0] "Unitless" ECM
 SG_ VehSpdLgt_UB : 39|1@0+ (1,0) [0|1] "" MVEM,PSCM1,SAS
 SG_ VehSpdLgtA : 38|15@0+ (0.00391,0.0) [0.0|125.0027] "m/s" MVEM,PSCM1,SAS
 SG_ VehSpdLgtChks : 55|8@0+ (1.0,0.0) [0.0|255.0] "Unitless" MVEM,PSCM1,SAS
 SG_ VehSpdLgtCntr : 63|4@0+ (1.0,0.0) [0.0|15.0] "Unitless" MVEM,PSCM1,SAS
 SG_ VehSpdLgtQf : 59|2@0+ (1,0) [0|3] "" MVEM,PSCM1,SAS

BO_ 928 VddmChas1Fr08: 8 VDDM
 SG_ AmbTIndcdWithUnit_UB : 9|1@0+ (1,0) [0|1] "" SAS
 SG_ AmbTIndcdWithUnitAmbTIndcd : 19|12@0+ (0.1,-100.0) [-100.0|309.5] "Unitless" SAS
 SG_ AmbTIndcdWithUnitAmbTIndcdUnit : 23|2@0+ (1,0) [0|3] "" SAS
 SG_ AmbTIndcdWithUnitQF : 21|2@0+ (1,0) [0|3] "" SAS
 SG_ CmptmtTRe_UB : 8|1@0+ (1,0) [0|1] "" Vector_XXX
 SG_ CmptmtTReCmptmtTFrnt : 7|11@0+ (0.1,-60.0) [-60.0|125.0] "degC" Vector_XXX
 SG_ CmptmtTReCmptmtTFrntQf : 12|2@0+ (1,0) [0|3] "" Vector_XXX
 SG_ CmptmtTReFanForCmptmtTRunng : 10|1@0+ (1,0) [0|1] "" Vector_XXX
 SG_ ReHvacBlowerSts : 38|2@0+ (1,0) [0|3] "" Vector_XXX
 SG_ ReHvacBlowerSts_UB : 39|1@0+ (1,0) [0|1] "" Vector_XXX

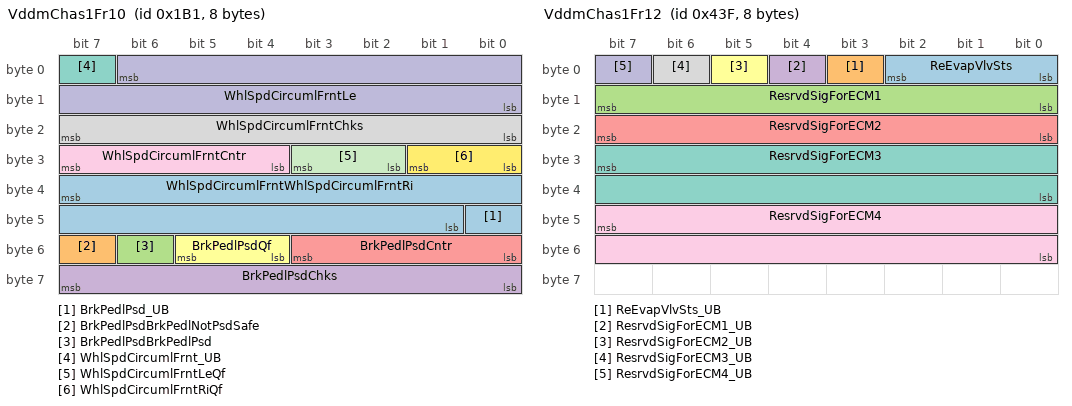
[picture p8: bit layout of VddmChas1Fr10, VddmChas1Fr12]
BO_ 433 VddmChas1Fr10: 8 VDDM
 SG_ BrkPedlPsd_UB : 40|1@0+ (1,0) [0|1] "" PSCM1
 SG_ BrkPedlPsdBrkPedlNotPsdSafe : 55|1@0+ (1,0) [0|1] "" PSCM1
 SG_ BrkPedlPsdBrkPedlPsd : 54|1@0+ (1,0) [0|1] "" PSCM1
 SG_ BrkPedlPsdChks : 63|8@0+ (1.0,0.0) [0.0|255.0] "Unitless" PSCM1
 SG_ BrkPedlPsdCntr : 51|4@0+ (1.0,0.0) [0.0|15.0] "Unitless" PSCM1
 SG_ BrkPedlPsdQf : 53|2@0+ (1,0) [0|3] "" PSCM1
 SG_ WhlSpdCircumlFrnt_UB : 7|1@0+ (1,0) [0|1] "" ECM,PSCM1
 SG_ WhlSpdCircumlFrntChks : 23|8@0+ (1.0,0.0) [0.0|255.0] "Unitless" ECM,PSCM1
 SG_ WhlSpdCircumlFrntCntr : 31|4@0+ (1.0,0.0) [0.0|15.0] "Unitless" ECM,PSCM1
 SG_ WhlSpdCircumlFrntLe : 6|15@0+ (0.00391,0.0) [0.0|125.0027] "m/s" ECM,PSCM1
 SG_ WhlSpdCircumlFrntLeQf : 27|2@0+ (1,0) [0|3] "" ECM,PSCM1
 SG_ WhlSpdCircumlFrntRiQf : 25|2@0+ (1,0) [0|3] "" ECM,PSCM1
 SG_ WhlSpdCircumlFrntWhlSpdCircumlFrntRi : 39|15@0+ (0.00391,0.0) [0.0|125.0027] "m/s" ECM,PSCM1

BO_ 1087 VddmChas1Fr12: 8 VDDM
 SG_ ReEvapVlvSts : 2|3@0+ (1,0) [0|7] "" ECM
 SG_ ReEvapVlvSts_UB : 3|1@0+ (1,0) [0|1] "" ECM
 SG_ ResrvdSigForECM1 : 15|8@0+ (1.0,0.0) [0.0|255.0] "Unitless" ECM
 SG_ ResrvdSigForECM1_UB : 4|1@0+ (1,0) [0|1] "" ECM
 SG_ ResrvdSigForECM2 : 23|8@0+ (1.0,0.0) [0.0|255.0] "Unitless" ECM
 SG_ ResrvdSigForECM2_UB : 5|1@0+ (1,0) [0|1] "" ECM
 SG_ ResrvdSigForECM3 : 31|16@0+ (1.0,0.0) [0.0|65535.0] "Unitless" ECM
 SG_ ResrvdSigForECM3_UB : 6|1@0+ (1,0) [0|1] "" ECM
 SG_ ResrvdSigForECM4 : 47|16@0+ (1.0,0.0) [0.0|65535.0] "Unitless" ECM
 SG_ ResrvdSigForECM4_UB : 7|1@0+ (1,0) [0|1] "" ECM

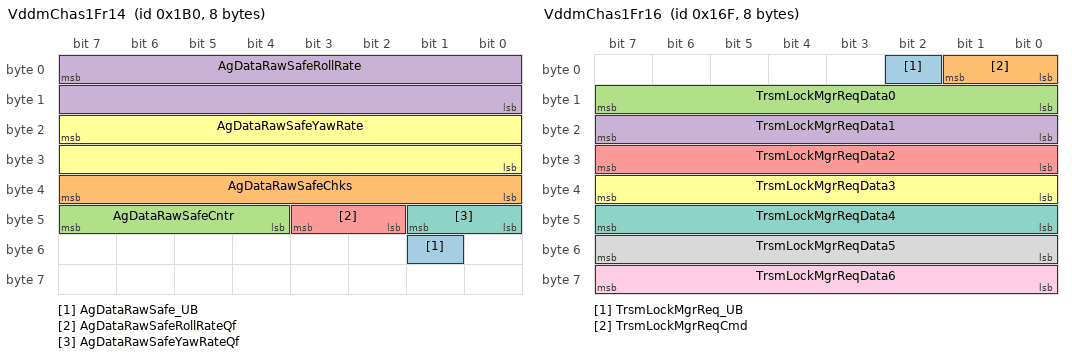
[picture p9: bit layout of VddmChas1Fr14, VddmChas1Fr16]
BO_ 432 VddmChas1Fr14: 8 VDDM
 SG_ AgDataRawSafe_UB : 49|1@0+ (1,0) [0|1] "" PSCM1
 SG_ AgDataRawSafeChks : 39|8@0+ (1.0,0.0) [0.0|255.0] "Unitless" PSCM1
 SG_ AgDataRawSafeCntr : 47|4@0+ (1.0,0.0) [0.0|15.0] "Unitless" PSCM1
 SG_ AgDataRawSafeRollRate : 7|16@0- (0.000244140625,0.0) [-6.0|6.0] "rad/s" PSCM1
 SG_ AgDataRawSafeRollRateQf : 43|2@0+ (1,0) [0|3] "" PSCM1
 SG_ AgDataRawSafeYawRate : 23|16@0- (0.000244140625,0.0) [-6.0|6.0] "rad/s" PSCM1
 SG_ AgDataRawSafeYawRateQf : 41|2@0+ (1,0) [0|3] "" PSCM1

BO_ 367 VddmChas1Fr16: 8 VDDM
 SG_ TrsmLockMgrReq_UB : 2|1@0+ (1,0) [0|1] "" TCM
 SG_ TrsmLockMgrReqCmd : 1|2@0+ (1,0) [0|3] "" TCM
 SG_ TrsmLockMgrReqData0 : 15|8@0+ (1.0,0.0) [0.0|255.0] "Unitless" TCM
 SG_ TrsmLockMgrReqData1 : 23|8@0+ (1.0,0.0) [0.0|255.0] "Unitless" TCM
 SG_ TrsmLockMgrReqData2 : 31|8@0+ (1.0,0.0) [0.0|255.0] "Unitless" TCM
 SG_ TrsmLockMgrReqData3 : 39|8@0+ (1.0,0.0) [0.0|255.0] "Unitless" TCM
 SG_ TrsmLockMgrReqData4 : 47|8@0+ (1.0,0.0) [0.0|255.0] "Unitless" TCM
 SG_ TrsmLockMgrReqData5 : 55|8@0+ (1.0,0.0) [0.0|255.0] "Unitless" TCM
 SG_ TrsmLockMgrReqData6 : 63|8@0+ (1.0,0.0) [0.0|255.0] "Unitless" TCM

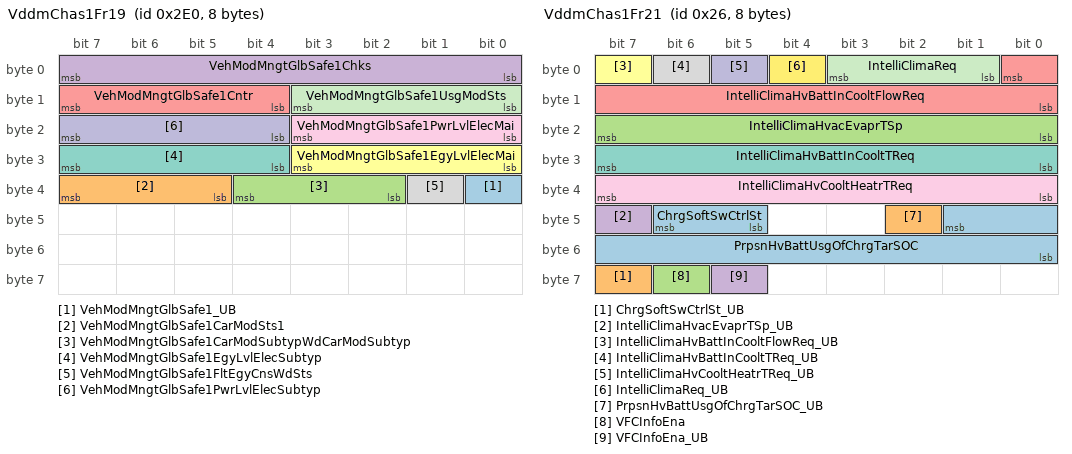
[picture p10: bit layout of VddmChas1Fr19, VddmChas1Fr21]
BO_ 736 VddmChas1Fr19: 8 VDDM
 SG_ VehModMngtGlbSafe1_UB : 32|1@0+ (1,0) [0|1] "" MVEM,PSCM1,SAS
 SG_ VehModMngtGlbSafe1CarModSts1 : 39|3@0+ (1,0) [0|7] "" MVEM,PSCM1,SAS
 SG_ VehModMngtGlbSafe1CarModSubtypWdCarModSubtyp : 36|3@0+ (1.0,0.0) [0.0|7.0] "Unitless" MVEM,PSCM1,SAS
 SG_ VehModMngtGlbSafe1Chks : 7|8@0+ (1.0,0.0) [0.0|255.0] "Unitless" MVEM,PSCM1,SAS
 SG_ VehModMngtGlbSafe1Cntr : 15|4@0+ (1.0,0.0) [0.0|15.0] "Unitless" MVEM,PSCM1,SAS
 SG_ VehModMngtGlbSafe1EgyLvlElecMai : 27|4@0+ (1.0,0.0) [0.0|15.0] "Unitless" MVEM,PSCM1,SAS
 SG_ VehModMngtGlbSafe1EgyLvlElecSubtyp : 31|4@0+ (1.0,0.0) [0.0|15.0] "Unitless" MVEM,PSCM1,SAS
 SG_ VehModMngtGlbSafe1FltEgyCnsWdSts : 33|1@0+ (1,0) [0|1] "" MVEM,PSCM1,SAS
 SG_ VehModMngtGlbSafe1PwrLvlElecMai : 19|4@0+ (1.0,0.0) [0.0|15.0] "Unitless" MVEM,PSCM1,SAS
 SG_ VehModMngtGlbSafe1PwrLvlElecSubtyp : 23|4@0+ (1.0,0.0) [0.0|15.0] "Unitless" MVEM,PSCM1,SAS
 SG_ VehModMngtGlbSafe1UsgModSts : 11|4@0+ (1,0) [0|15] "" MVEM,PSCM1,SAS

BO_ 38 VddmChas1Fr21: 8 VDDM
 SG_ ChrgSoftSwCtrlSt : 46|2@0+ (1,0) [0|3] "" ECM
 SG_ ChrgSoftSwCtrlSt_UB : 63|1@0+ (1,0) [0|1] "" ECM
 SG_ IntelliClimaHvacEvaprTSp : 23|8@0+ (0.1,-5.0) [-5.0|20.0] "Unitless" ECM
 SG_ IntelliClimaHvacEvaprTSp_UB : 47|1@0+ (1,0) [0|1] "" ECM
 SG_ IntelliClimaHvBattInCooltFlowReq : 0|9@0+ (0.1,0.0) [0.0|51.1] "L / min" ECM
 SG_ IntelliClimaHvBattInCooltFlowReq_UB : 7|1@0+ (1,0) [0|1] "" ECM
 SG_ IntelliClimaHvBattInCooltTReq : 31|8@0+ (1.0,-50.0) [-50.0|200.0] "degC" ECM
 SG_ IntelliClimaHvBattInCooltTReq_UB : 6|1@0+ (1,0) [0|1] "" ECM
 SG_ IntelliClimaHvCooltHeatrTReq : 39|8@0+ (1.0,-40.0) [-40.0|215.0] "degC" ECM
 SG_ IntelliClimaHvCooltHeatrTReq_UB : 5|1@0+ (1,0) [0|1] "" ECM
 SG_ IntelliClimaReq : 3|3@0+ (1,0) [0|7] "" ECM
 SG_ IntelliClimaReq_UB : 4|1@0+ (1,0) [0|1] "" ECM
 SG_ PrpsnHvBattUsgOfChrgTarSOC : 41|10@0+ (0.1,0.0) [0.0|100.0] "%" ECM
 SG_ PrpsnHvBattUsgOfChrgTarSOC_UB : 42|1@0+ (1,0) [0|1] "" ECM
 SG_ VFCInfoEna : 62|1@0+ (1,0) [0|1] "" ECM,TCM
 SG_ VFCInfoEna_UB : 61|1@0+ (1,0) [0|1] "" ECM,TCM

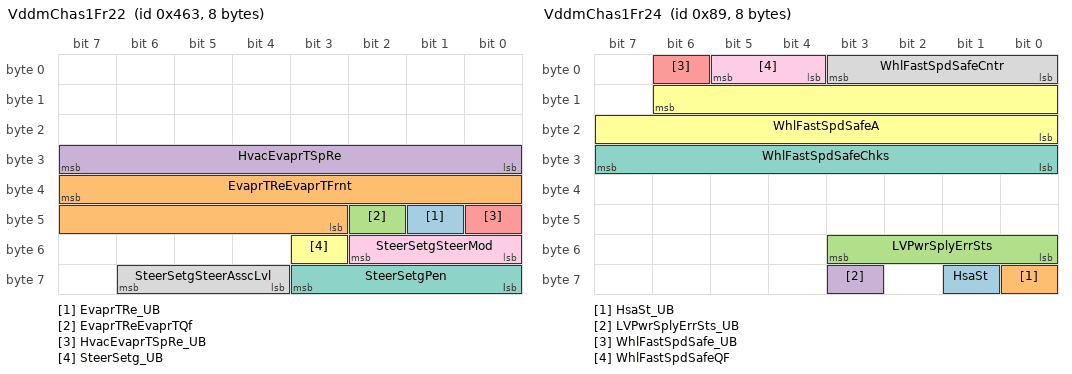
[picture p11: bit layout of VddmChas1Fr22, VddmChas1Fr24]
BO_ 1123 VddmChas1Fr22: 8 VDDM
 SG_ EvaprTRe_UB : 41|1@0+ (1,0) [0|1] "" Vector_XXX
 SG_ EvaprTReEvaprTFrnt : 39|13@0- (0.1,0.0) [-256.0|255.9] "degC" Vector_XXX
 SG_ EvaprTReEvaprTQf : 42|1@0+ (1,0) [0|1] "" Vector_XXX
 SG_ HvacEvaprTSpRe : 31|8@0+ (0.1,-5.0) [-5.0|20.0] "Unitless" Vector_XXX
 SG_ HvacEvaprTSpRe_UB : 40|1@0+ (1,0) [0|1] "" Vector_XXX
 SG_ SteerSetg_UB : 51|1@0+ (1,0) [0|1] "" PSCM1
 SG_ SteerSetgPen : 59|4@0+ (1,0) [0|15] "" PSCM1
 SG_ SteerSetgSteerAsscLvl : 62|3@0+ (1,0) [0|7] "" PSCM1
 SG_ SteerSetgSteerMod : 50|3@0+ (1,0) [0|7] "" PSCM1

BO_ 784 VddmChas1Fr23: 8 VDDM
 SG_ CmptmtTFrnt_UB : 23|1@0+ (1,0) [0|1] "" SAS
 SG_ CmptmtTFrntCmptmtTFrnt : 21|11@0+ (0.1,-60.0) [-60.0|125.0] "degC" SAS
 SG_ CmptmtTFrntFanForCmptmtTRunng : 24|1@0+ (1,0) [0|1] "" SAS
 SG_ CmptmtTFrntQf : 26|2@0+ (1,0) [0|3] "" SAS

BO_ 137 VddmChas1Fr24: 8 VDDM
 SG_ HsaSt : 57|1@0+ (1,0) [0|1] "" TCM
 SG_ HsaSt_UB : 56|1@0+ (1,0) [0|1] "" TCM
 SG_ LVPwrSplyErrSts : 51|4@0+ (1,0) [0|15] "" ECM
 SG_ LVPwrSplyErrSts_UB : 59|1@0+ (1,0) [0|1] "" ECM
 SG_ WhlFastSpdSafe_UB : 6|1@0+ (1,0) [0|1] "" PAS,PSCM1
 SG_ WhlFastSpdSafeA : 14|15@0+ (0.00391,0.0) [0.0|125.0027] "m/s" PAS,PSCM1
 SG_ WhlFastSpdSafeChks : 31|8@0+ (1.0,0.0) [0.0|255.0] "Unitless" PAS,PSCM1
 SG_ WhlFastSpdSafeCntr : 3|4@0+ (1.0,0.0) [0.0|15.0] "Unitless" PAS,PSCM1
 SG_ WhlFastSpdSafeQF : 5|2@0+ (1,0) [0|3] "" PAS,PSCM1

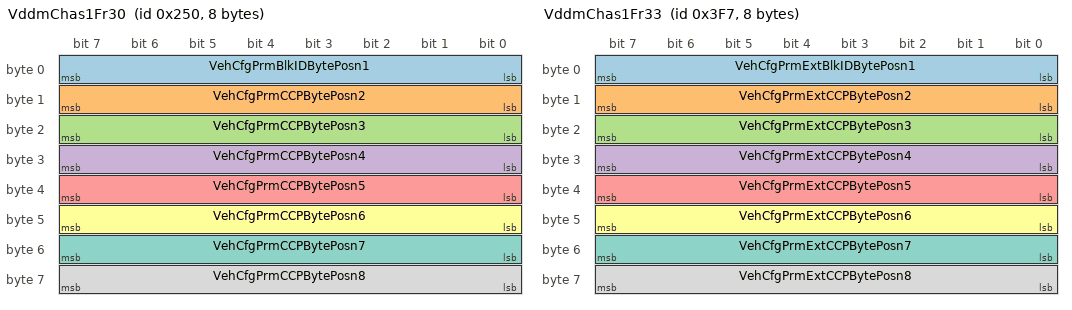
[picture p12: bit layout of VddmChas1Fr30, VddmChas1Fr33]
BO_ 592 VddmChas1Fr30: 8 VDDM
 SG_ VehCfgPrmBlkIDBytePosn1 : 7|8@0+ (1.0,0.0) [0.0|255.0] "Unitless" PSCM1,SAS
 SG_ VehCfgPrmCCPBytePosn2 : 15|8@0+ (1.0,0.0) [0.0|255.0] "Unitless" PSCM1,SAS
 SG_ VehCfgPrmCCPBytePosn3 : 23|8@0+ (1.0,0.0) [0.0|255.0] "Unitless" PSCM1,SAS
 SG_ VehCfgPrmCCPBytePosn4 : 31|8@0+ (1.0,0.0) [0.0|255.0] "Unitless" PSCM1,SAS
 SG_ VehCfgPrmCCPBytePosn5 : 39|8@0+ (1.0,0.0) [0.0|255.0] "Unitless" PSCM1,SAS
 SG_ VehCfgPrmCCPBytePosn6 : 47|8@0+ (1.0,0.0) [0.0|255.0] "Unitless" PSCM1,SAS
 SG_ VehCfgPrmCCPBytePosn7 : 55|8@0+ (1.0,0.0) [0.0|255.0] "Unitless" PSCM1,SAS
 SG_ VehCfgPrmCCPBytePosn8 : 63|8@0+ (1.0,0.0) [0.0|255.0] "Unitless" PSCM1,SAS

BO_ 1015 VddmChas1Fr33: 8 VDDM
 SG_ VehCfgPrmExtBlkIDBytePosn1 : 7|8@0+ (1.0,0.0) [0.0|255.0] "Unitless" ECM,PSCM1
 SG_ VehCfgPrmExtCCPBytePosn2 : 15|8@0+ (1.0,0.0) [0.0|255.0] "Unitless" ECM,PSCM1
 SG_ VehCfgPrmExtCCPBytePosn3 : 23|8@0+ (1.0,0.0) [0.0|255.0] "Unitless" ECM,PSCM1
 SG_ VehCfgPrmExtCCPBytePosn4 : 31|8@0+ (1.0,0.0) [0.0|255.0] "Unitless" ECM,PSCM1
 SG_ VehCfgPrmExtCCPBytePosn5 : 39|8@0+ (1.0,0.0) [0.0|255.0] "Unitless" ECM,PSCM1
 SG_ VehCfgPrmExtCCPBytePosn6 : 47|8@0+ (1.0,0.0) [0.0|255.0] "Unitless" ECM,PSCM1
 SG_ VehCfgPrmExtCCPBytePosn7 : 55|8@0+ (1.0,0.0) [0.0|255.0] "Unitless" ECM,PSCM1
 SG_ VehCfgPrmExtCCPBytePosn8 : 63|8@0+ (1.0,0.0) [0.0|255.0] "Unitless" ECM,PSCM1

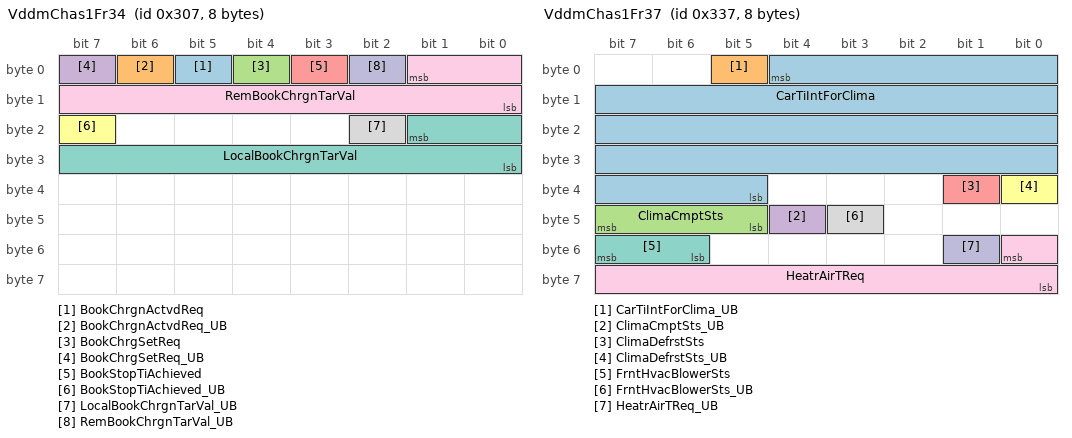
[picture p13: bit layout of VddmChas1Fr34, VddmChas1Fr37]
BO_ 775 VddmChas1Fr34: 8 VDDM
 SG_ BookChrgnActvdReq : 5|1@0+ (1,0) [0|1] "" ECM
 SG_ BookChrgnActvdReq_UB : 6|1@0+ (1,0) [0|1] "" ECM
 SG_ BookChrgSetReq : 4|1@0+ (1,0) [0|1] "" ECM
 SG_ BookChrgSetReq_UB : 7|1@0+ (1,0) [0|1] "" ECM
 SG_ BookStopTiAchieved : 3|1@0+ (1,0) [0|1] "" ECM
 SG_ BookStopTiAchieved_UB : 23|1@0+ (1,0) [0|1] "" ECM
 SG_ LocalBookChrgnTarVal : 17|10@0+ (0.1,0.0) [0.0|100.0] "%" ECM
 SG_ LocalBookChrgnTarVal_UB : 18|1@0+ (1,0) [0|1] "" ECM
 SG_ RemBookChrgnTarVal : 1|10@0+ (0.1,0.0) [0.0|100.0] "%" ECM
 SG_ RemBookChrgnTarVal_UB : 2|1@0+ (1,0) [0|1] "" ECM

BO_ 823 VddmChas1Fr37: 8 VDDM
 SG_ CarTiIntForClima : 4|32@0+ (0.1,0.0) [0.0|429496729.5] "s" ECM
 SG_ CarTiIntForClima_UB : 5|1@0+ (1,0) [0|1] "" ECM
 SG_ ClimaCmptSts : 47|3@0+ (1,0) [0|7] "" ECM
 SG_ ClimaCmptSts_UB : 44|1@0+ (1,0) [0|1] "" ECM
 SG_ ClimaDefrstSts : 33|1@0+ (1,0) [0|1] "" ECM
 SG_ ClimaDefrstSts_UB : 32|1@0+ (1,0) [0|1] "" ECM
 SG_ FrntHvacBlowerSts : 55|2@0+ (1,0) [0|3] "" Vector_XXX
 SG_ FrntHvacBlowerSts_UB : 43|1@0+ (1,0) [0|1] "" Vector_XXX
 SG_ HeatrAirTReq : 48|9@0+ (0.5,-60.0) [-60.0|195.5] "Unitless" ECM
 SG_ HeatrAirTReq_UB : 49|1@0+ (1,0) [0|1] "" ECM

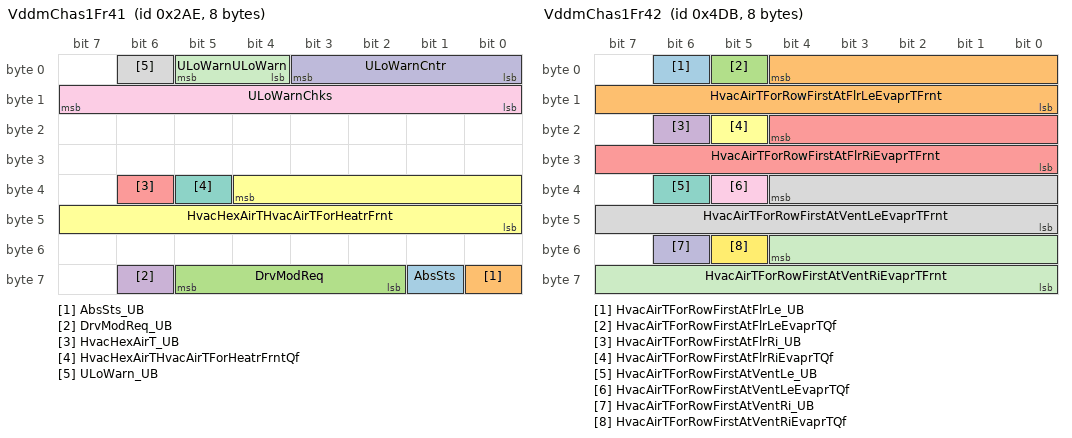
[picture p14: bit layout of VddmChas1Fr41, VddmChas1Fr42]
BO_ 686 VddmChas1Fr41: 8 VDDM
 SG_ AbsSts : 57|1@0+ (1,0) [0|1] "" Vector_XXX
 SG_ AbsSts_UB : 56|1@0+ (1,0) [0|1] "" Vector_XXX
 SG_ DrvModReq : 61|4@0+ (1,0) [0|15] "" PSCM1
 SG_ DrvModReq_UB : 62|1@0+ (1,0) [0|1] "" PSCM1
 SG_ HvacHexAirT_UB : 38|1@0+ (1,0) [0|1] "" ECM
 SG_ HvacHexAirTHvacAirTForHeatrFrnt : 36|13@0- (0.1,0.0) [-256.0|255.9] "degC" ECM
 SG_ HvacHexAirTHvacAirTForHeatrFrntQf : 37|1@0+ (1,0) [0|1] "" ECM
 SG_ ULoWarn_UB : 6|1@0+ (1,0) [0|1] "" PSCM1
 SG_ ULoWarnChks : 15|8@0+ (1.0,0.0) [0.0|255.0] "Unitless" PSCM1
 SG_ ULoWarnCntr : 3|4@0+ (1.0,0.0) [0.0|15.0] "Unitless" PSCM1
 SG_ ULoWarnULoWarn : 5|2@0+ (1,0) [0|3] "" PSCM1

BO_ 1243 VddmChas1Fr42: 8 VDDM
 SG_ HvacAirTForRowFirstAtFlrLe_UB : 6|1@0+ (1,0) [0|1] "" Vector_XXX
 SG_ HvacAirTForRowFirstAtFlrLeEvaprTFrnt : 4|13@0- (0.1,0.0) [-256.0|255.9] "degC" Vector_XXX
 SG_ HvacAirTForRowFirstAtFlrLeEvaprTQf : 5|1@0+ (1,0) [0|1] "" Vector_XXX
 SG_ HvacAirTForRowFirstAtFlrRi_UB : 22|1@0+ (1,0) [0|1] "" Vector_XXX
 SG_ HvacAirTForRowFirstAtFlrRiEvaprTFrnt : 20|13@0- (0.1,0.0) [-256.0|255.9] "degC" Vector_XXX
 SG_ HvacAirTForRowFirstAtFlrRiEvaprTQf : 21|1@0+ (1,0) [0|1] "" Vector_XXX
 SG_ HvacAirTForRowFirstAtVentLe_UB : 38|1@0+ (1,0) [0|1] "" Vector_XXX
 SG_ HvacAirTForRowFirstAtVentLeEvaprTFrnt : 36|13@0- (0.1,0.0) [-256.0|255.9] "degC" Vector_XXX
 SG_ HvacAirTForRowFirstAtVentLeEvaprTQf : 37|1@0+ (1,0) [0|1] "" Vector_XXX
 SG_ HvacAirTForRowFirstAtVentRi_UB : 54|1@0+ (1,0) [0|1] "" Vector_XXX
 SG_ HvacAirTForRowFirstAtVentRiEvaprTFrnt : 52|13@0- (0.1,0.0) [-256.0|255.9] "degC" Vector_XXX
 SG_ HvacAirTForRowFirstAtVentRiEvaprTQf : 53|1@0+ (1,0) [0|1] "" Vector_XXX

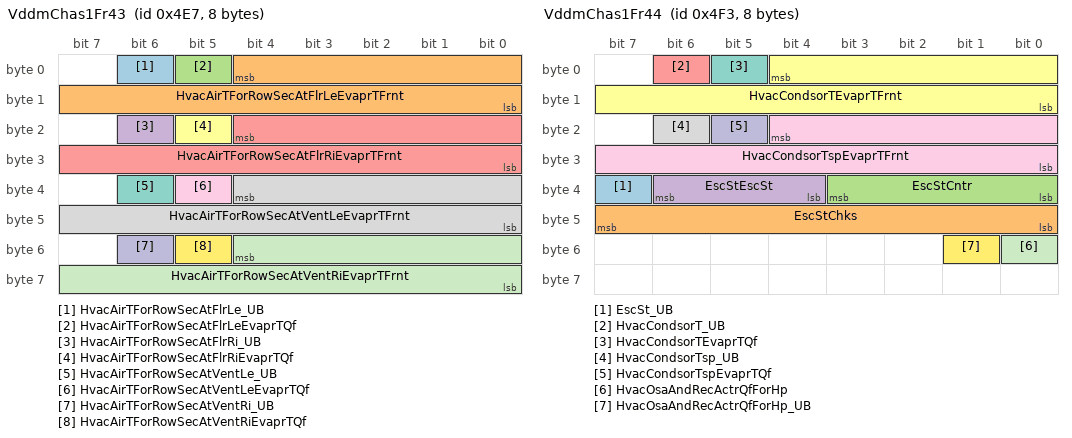
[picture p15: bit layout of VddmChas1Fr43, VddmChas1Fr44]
BO_ 1255 VddmChas1Fr43: 8 VDDM
 SG_ HvacAirTForRowSecAtFlrLe_UB : 6|1@0+ (1,0) [0|1] "" Vector_XXX
 SG_ HvacAirTForRowSecAtFlrLeEvaprTFrnt : 4|13@0- (0.1,0.0) [-256.0|255.9] "degC" Vector_XXX
 SG_ HvacAirTForRowSecAtFlrLeEvaprTQf : 5|1@0+ (1,0) [0|1] "" Vector_XXX
 SG_ HvacAirTForRowSecAtFlrRi_UB : 22|1@0+ (1,0) [0|1] "" Vector_XXX
 SG_ HvacAirTForRowSecAtFlrRiEvaprTFrnt : 20|13@0- (0.1,0.0) [-256.0|255.9] "degC" Vector_XXX
 SG_ HvacAirTForRowSecAtFlrRiEvaprTQf : 21|1@0+ (1,0) [0|1] "" Vector_XXX
 SG_ HvacAirTForRowSecAtVentLe_UB : 38|1@0+ (1,0) [0|1] "" Vector_XXX
 SG_ HvacAirTForRowSecAtVentLeEvaprTFrnt : 36|13@0- (0.1,0.0) [-256.0|255.9] "degC" Vector_XXX
 SG_ HvacAirTForRowSecAtVentLeEvaprTQf : 37|1@0+ (1,0) [0|1] "" Vector_XXX
 SG_ HvacAirTForRowSecAtVentRi_UB : 54|1@0+ (1,0) [0|1] "" Vector_XXX
 SG_ HvacAirTForRowSecAtVentRiEvaprTFrnt : 52|13@0- (0.1,0.0) [-256.0|255.9] "degC" Vector_XXX
 SG_ HvacAirTForRowSecAtVentRiEvaprTQf : 53|1@0+ (1,0) [0|1] "" Vector_XXX

BO_ 1267 VddmChas1Fr44: 8 VDDM
 SG_ EscSt_UB : 39|1@0+ (1,0) [0|1] "" PSCM1
 SG_ EscStChks : 47|8@0+ (1.0,0.0) [0.0|255.0] "Unitless" PSCM1
 SG_ EscStCntr : 35|4@0+ (1.0,0.0) [0.0|15.0] "Unitless" PSCM1
 SG_ EscStEscSt : 38|3@0+ (1,0) [0|7] "" PSCM1
 SG_ HvacCondsorT_UB : 6|1@0+ (1,0) [0|1] "" Vector_XXX
 SG_ HvacCondsorTEvaprTFrnt : 4|13@0- (0.1,0.0) [-256.0|255.9] "degC" Vector_XXX
 SG_ HvacCondsorTEvaprTQf : 5|1@0+ (1,0) [0|1] "" Vector_XXX
 SG_ HvacCondsorTsp_UB : 22|1@0+ (1,0) [0|1] "" Vector_XXX
 SG_ HvacCondsorTspEvaprTFrnt : 20|13@0- (0.1,0.0) [-256.0|255.9] "degC" Vector_XXX
 SG_ HvacCondsorTspEvaprTQf : 21|1@0+ (1,0) [0|1] "" Vector_XXX
 SG_ HvacOsaAndRecActrQfForHp : 48|1@0+ (1,0) [0|1] "" Vector_XXX
 SG_ HvacOsaAndRecActrQfForHp_UB : 49|1@0+ (1,0) [0|1] "" Vector_XXX

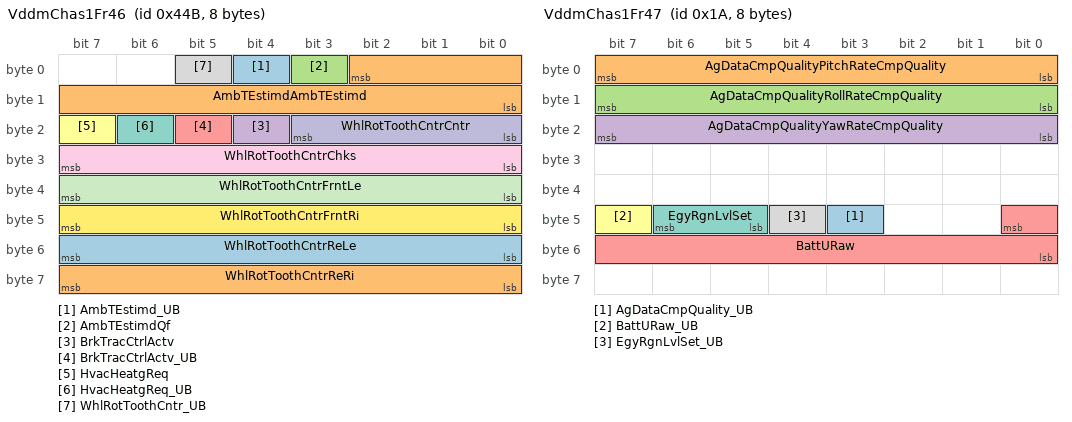
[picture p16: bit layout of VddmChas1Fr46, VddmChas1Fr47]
BO_ 1099 VddmChas1Fr46: 8 VDDM
 SG_ AmbTEstimd_UB : 4|1@0+ (1,0) [0|1] "" Vector_XXX
 SG_ AmbTEstimdAmbTEstimd : 2|11@0+ (0.1,-70.0) [-70.0|134.70000000000002] "degC" Vector_XXX
 SG_ AmbTEstimdQf : 3|1@0+ (1,0) [0|1] "" Vector_XXX
 SG_ BrkTracCtrlActv : 20|1@0+ (1,0) [0|1] "" PSCM1
 SG_ BrkTracCtrlActv_UB : 21|1@0+ (1,0) [0|1] "" PSCM1
 SG_ HvacHeatgReq : 23|1@0+ (1,0) [0|1] "" ECM
 SG_ HvacHeatgReq_UB : 22|1@0+ (1,0) [0|1] "" ECM
 SG_ WhlRotToothCntr_UB : 5|1@0+ (1,0) [0|1] "" PSCM1
 SG_ WhlRotToothCntrChks : 31|8@0+ (1.0,0.0) [0.0|255.0] "Unitless" PSCM1
 SG_ WhlRotToothCntrCntr : 19|4@0+ (1.0,0.0) [0.0|15.0] "Unitless" PSCM1
 SG_ WhlRotToothCntrFrntLe : 39|8@0+ (1.0,0.0) [0.0|255.0] "Unitless" PSCM1
 SG_ WhlRotToothCntrFrntRi : 47|8@0+ (1.0,0.0) [0.0|255.0] "Unitless" PSCM1
 SG_ WhlRotToothCntrReLe : 55|8@0+ (1.0,0.0) [0.0|255.0] "Unitless" PSCM1
 SG_ WhlRotToothCntrReRi : 63|8@0+ (1.0,0.0) [0.0|255.0] "Unitless" PSCM1

BO_ 26 VddmChas1Fr47: 8 VDDM
 SG_ AgDataCmpQuality_UB : 43|1@0+ (1,0) [0|1] "" PSCM1
 SG_ AgDataCmpQualityPitchRateCmpQuality : 7|8@0+ (1.0,0.0) [0.0|255.0] "Unitless" PSCM1
 SG_ AgDataCmpQualityRollRateCmpQuality : 15|8@0+ (1.0,0.0) [0.0|255.0] "Unitless" PSCM1
 SG_ AgDataCmpQualityYawRateCmpQuality : 23|8@0+ (1.0,0.0) [0.0|255.0] "Unitless" PSCM1
 SG_ BattURaw : 40|9@0+ (0.025,5.0) [5.0|17.775] "Volt" ECM
 SG_ BattURaw_UB : 47|1@0+ (1,0) [0|1] "" ECM
 SG_ EgyRgnLvlSet : 46|2@0+ (1,0) [0|3] "" ECM
 SG_ EgyRgnLvlSet_UB : 44|1@0+ (1,0) [0|1] "" ECM

BO_ 1159 VddmChas1Fr48: 8 VDDM
 SG_ VehMtnSt_UB : 7|1@0+ (1,0) [0|1] "" PSCM1
 SG_ VehMtnStChks : 15|8@0+ (1.0,0.0) [0.0|255.0] "Unitless" PSCM1
 SG_ VehMtnStCntr : 6|4@0+ (1.0,0.0) [0.0|15.0] "Unitless" PSCM1
 SG_ VehMtnStVehMtnSt : 2|3@0+ (1,0) [0|7] "" PSCM1

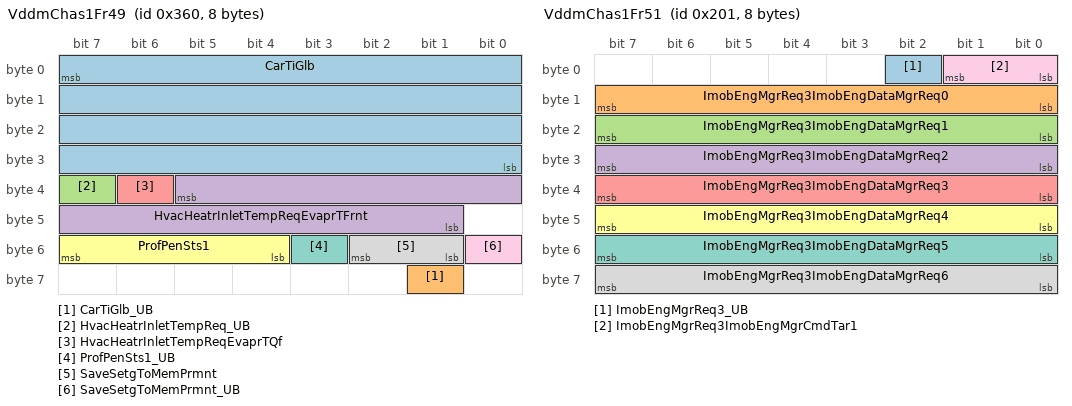
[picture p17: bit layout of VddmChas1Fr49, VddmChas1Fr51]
BO_ 864 VddmChas1Fr49: 8 VDDM
 SG_ CarTiGlb : 7|32@0+ (0.1,0.0) [0.0|429496729.5] "s" MVEM,PSCM1,SAS
 SG_ CarTiGlb_UB : 57|1@0+ (1,0) [0|1] "" MVEM,PSCM1,SAS
 SG_ HvacHeatrInletTempReq_UB : 39|1@0+ (1,0) [0|1] "" ECM
 SG_ HvacHeatrInletTempReqEvaprTFrnt : 37|13@0- (0.1,0.0) [-256.0|255.9] "degC" ECM
 SG_ HvacHeatrInletTempReqEvaprTQf : 38|1@0+ (1,0) [0|1] "" ECM
 SG_ ProfPenSts1 : 55|4@0+ (1,0) [0|15] "" PSCM1
 SG_ ProfPenSts1_UB : 51|1@0+ (1,0) [0|1] "" PSCM1
 SG_ SaveSetgToMemPrmnt : 50|2@0+ (1,0) [0|3] "" PSCM1
 SG_ SaveSetgToMemPrmnt_UB : 48|1@0+ (1,0) [0|1] "" PSCM1

BO_ 896 VddmChas1Fr50: 8 VDDM
 SG_ VehBattU_UB : 54|1@0+ (1,0) [0|1] "" MVEM,PSCM1,SAS
 SG_ VehBattUSysU : 63|8@0+ (0.1,0.0) [0.0|25.0] "Volt" MVEM,PSCM1,SAS
 SG_ VehBattUSysUQf : 49|2@0+ (1,0) [0|3] "" MVEM,PSCM1,SAS

BO_ 513 VddmChas1Fr51: 8 VDDM
 SG_ ImobEngMgrReq3_UB : 2|1@0+ (1,0) [0|1] "" MVEM
 SG_ ImobEngMgrReq3ImobEngDataMgrReq0 : 15|8@0+ (1.0,0.0) [0.0|255.0] "Unitless" MVEM
 SG_ ImobEngMgrReq3ImobEngDataMgrReq1 : 23|8@0+ (1.0,0.0) [0.0|255.0] "Unitless" MVEM
 SG_ ImobEngMgrReq3ImobEngDataMgrReq2 : 31|8@0+ (1.0,0.0) [0.0|255.0] "Unitless" MVEM
 SG_ ImobEngMgrReq3ImobEngDataMgrReq3 : 39|8@0+ (1.0,0.0) [0.0|255.0] "Unitless" MVEM
 SG_ ImobEngMgrReq3ImobEngDataMgrReq4 : 47|8@0+ (1.0,0.0) [0.0|255.0] "Unitless" MVEM
 SG_ ImobEngMgrReq3ImobEngDataMgrReq5 : 55|8@0+ (1.0,0.0) [0.0|255.0] "Unitless" MVEM
 SG_ ImobEngMgrReq3ImobEngDataMgrReq6 : 63|8@0+ (1.0,0.0) [0.0|255.0] "Unitless" MVEM
 SG_ ImobEngMgrReq3ImobEngMgrCmdTar1 : 1|2@0+ (1,0) [0|3] "" MVEM

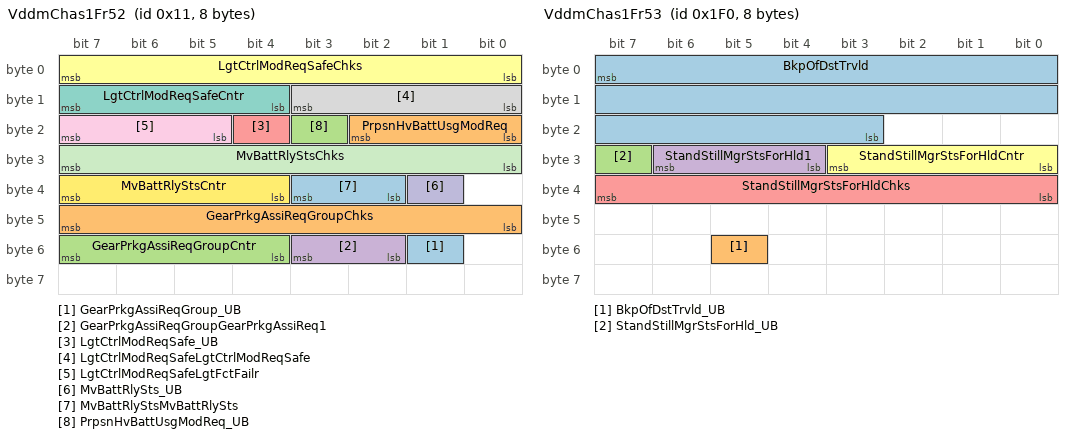
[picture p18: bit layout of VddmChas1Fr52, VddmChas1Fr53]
BO_ 17 VddmChas1Fr52: 8 VDDM
 SG_ GearPrkgAssiReqGroup_UB : 49|1@0+ (1,0) [0|1] "" ECM
 SG_ GearPrkgAssiReqGroupChks : 47|8@0+ (1.0,0.0) [0.0|255.0] "Unitless" ECM
 SG_ GearPrkgAssiReqGroupCntr : 55|4@0+ (1.0,0.0) [0.0|15.0] "Unitless" ECM
 SG_ GearPrkgAssiReqGroupGearPrkgAssiReq1 : 51|2@0+ (1,0) [0|3] "" ECM
 SG_ LgtCtrlModReqSafe_UB : 20|1@0+ (1,0) [0|1] "" ECM
 SG_ LgtCtrlModReqSafeChks : 7|8@0+ (1.0,0.0) [0.0|255.0] "Unitless" ECM
 SG_ LgtCtrlModReqSafeCntr : 15|4@0+ (1.0,0.0) [0.0|15.0] "Unitless" ECM
 SG_ LgtCtrlModReqSafeLgtCtrlModReqSafe : 11|4@0+ (1,0) [0|15] "" ECM
 SG_ LgtCtrlModReqSafeLgtFctFailr : 23|3@0+ (1,0) [0|7] "" ECM
 SG_ MvBattRlySts_UB : 33|1@0+ (1,0) [0|1] "" MVEM
 SG_ MvBattRlyStsChks : 31|8@0+ (1.0,0.0) [0.0|255.0] "Unitless" MVEM
 SG_ MvBattRlyStsCntr : 39|4@0+ (1.0,0.0) [0.0|15.0] "Unitless" MVEM
 SG_ MvBattRlyStsMvBattRlySts : 35|2@0+ (1,0) [0|3] "" MVEM
 SG_ PrpsnHvBattUsgModReq : 18|3@0+ (1,0) [0|7] "" ECM
 SG_ PrpsnHvBattUsgModReq_UB : 19|1@0+ (1,0) [0|1] "" ECM

BO_ 496 VddmChas1Fr53: 8 VDDM
 SG_ BkpOfDstTrvld : 7|21@0+ (1.0,0.0) [0.0|2000000.0] "km" MVEM,PSCM1,SAS
 SG_ BkpOfDstTrvld_UB : 53|1@0+ (1,0) [0|1] "" MVEM,PSCM1,SAS
 SG_ StandStillMgrStsForHld_UB : 31|1@0+ (1,0) [0|1] "" ECM
 SG_ StandStillMgrStsForHld1 : 30|3@0+ (1,0) [0|7] "" ECM
 SG_ StandStillMgrStsForHldChks : 39|8@0+ (1.0,0.0) [0.0|255.0] "Unitless" ECM
 SG_ StandStillMgrStsForHldCntr : 27|4@0+ (1.0,0.0) [0.0|15.0] "Unitless" ECM

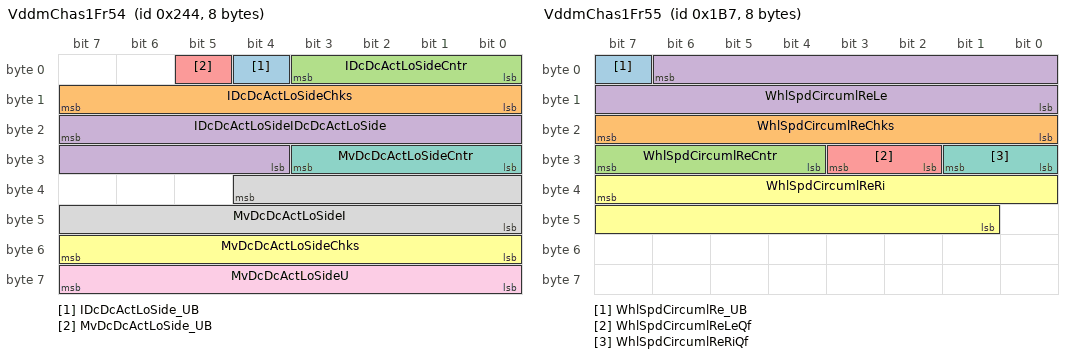
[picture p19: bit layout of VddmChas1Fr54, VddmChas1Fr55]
BO_ 580 VddmChas1Fr54: 8 VDDM
 SG_ IDcDcActLoSide_UB : 4|1@0+ (1,0) [0|1] "" PSCM1
 SG_ IDcDcActLoSideChks : 15|8@0+ (1.0,0.0) [0.0|255.0] "Unitless" PSCM1
 SG_ IDcDcActLoSideCntr : 3|4@0+ (1.0,0.0) [0.0|15.0] "Unitless" PSCM1
 SG_ IDcDcActLoSideIDcDcActLoSide : 23|12@0+ (0.1,0.0) [0.0|409.5] "A" PSCM1
 SG_ MvDcDcActLoSide_UB : 5|1@0+ (1,0) [0|1] "" PSCM1
 SG_ MvDcDcActLoSideChks : 55|8@0+ (1.0,0.0) [0.0|255.0] "Unitless" PSCM1
 SG_ MvDcDcActLoSideCntr : 27|4@0+ (1.0,0.0) [0.0|15.0] "Unitless" PSCM1
 SG_ MvDcDcActLoSideI : 36|13@0+ (0.1,-409.6) [-409.6|409.5] "A" PSCM1
 SG_ MvDcDcActLoSideU : 63|8@0+ (0.1,0.0) [0.0|25.400000000000002] "Volt" PSCM1

BO_ 439 VddmChas1Fr55: 8 VDDM
 SG_ WhlSpdCircumlRe_UB : 7|1@0+ (1,0) [0|1] "" ECM,PSCM1
 SG_ WhlSpdCircumlReChks : 23|8@0+ (1.0,0.0) [0.0|255.0] "Unitless" ECM,PSCM1
 SG_ WhlSpdCircumlReCntr : 31|4@0+ (1.0,0.0) [0.0|15.0] "Unitless" ECM,PSCM1
 SG_ WhlSpdCircumlReLe : 6|15@0+ (0.00391,0.0) [0.0|125.0027] "m/s" ECM,PSCM1
 SG_ WhlSpdCircumlReLeQf : 27|2@0+ (1,0) [0|3] "" ECM,PSCM1
 SG_ WhlSpdCircumlReRi : 39|15@0+ (0.00391,0.0) [0.0|125.0027] "m/s" ECM,PSCM1
 SG_ WhlSpdCircumlReRiQf : 25|2@0+ (1,0) [0|3] "" ECM,PSCM1

BO_ 52 VddmChas1Fr56: 8 VDDM
 SG_ CrashStsSafe_UB : 5|1@0+ (1,0) [0|1] "" MVEM
 SG_ CrashStsSafeChks : 15|8@0+ (1.0,0.0) [0.0|255.0] "Unitless" MVEM
 SG_ CrashStsSafeCntr : 3|4@0+ (1.0,0.0) [0.0|15.0] "Unitless" MVEM
 SG_ CrashStsSafeSts : 4|1@0+ (1,0) [0|1] "" MVEM

BO_ 1313 VddmChas1NMFr: 8 VDDM
 SG_ PNC16_VDDM : 16|1@0+ (1,0) [0|0] "" TCM
 SG_ PNC17_VDDM : 17|1@0+ (1,0) [0|0] "" TCM
 SG_ PNC18_VDDM : 18|1@0+ (1,0) [0|0] "" TCM
 SG_ PNC19_VDDM : 19|1@0+ (1,0) [0|0] "" TCM
 SG_ PNC20_VDDM : 20|1@0+ (1,0) [0|0] "" TCM
 SG_ PNC21_VDDM : 21|1@0+ (1,0) [0|0] "" TCM
 SG_ PNC22_VDDM : 22|1@0+ (1,0) [0|0] "" TCM
 SG_ PNC23_VDDM : 23|1@0+ (1,0) [0|0] "" TCM
 SG_ PNC24_VDDM : 24|1@0+ (1,0) [0|0] "" TCM
 SG_ PNC25_VDDM : 25|1@0+ (1,0) [0|0] "" TCM
 SG_ PNC26_VDDM : 26|1@0+ (1,0) [0|0] "" TCM
 SG_ PNC27_VDDM : 27|1@0+ (1,0) [0|0] "" TCM
 SG_ PNC28_VDDM : 28|1@0+ (1,0) [0|0] "" TCM
 SG_ PNC29_VDDM : 29|1@0+ (1,0) [0|0] "" TCM
 SG_ PNC30_VDDM : 30|1@0+ (1,0) [0|0] "" TCM
 SG_ PNC31_VDDM : 31|1@0+ (1,0) [0|0] "" TCM
 SG_ PNC32_VDDM : 32|1@0+ (1,0) [0|0] "" TCM
 SG_ PNC33_VDDM : 33|1@0+ (1,0) [0|0] "" TCM
 SG_ PNC34_VDDM : 34|1@0+ (1,0) [0|0] "" TCM
 SG_ PNC35_VDDM : 35|1@0+ (1,0) [0|0] "" TCM
 SG_ PNC36_VDDM : 36|1@0+ (1,0) [0|0] "" TCM
 SG_ PNC37_VDDM : 37|1@0+ (1,0) [0|0] "" TCM
 SG_ PNC38_VDDM : 38|1@0+ (1,0) [0|0] "" TCM
 SG_ PNC39_VDDM : 39|1@0+ (1,0) [0|0] "" TCM
 SG_ NM_PNI_VDDM : 14|1@0+ (1,0) [0|0] "" TCM
 SG_ NM_AW_VDDM : 12|1@0+ (1,0) [0|0] "" TCM
 SG_ NM_CS_VDDM : 11|1@0+ (1,0) [0|0] "" TCM
 SG_ NM_RMR_VDDM : 8|1@0+ (1,0) [0|0] "" TCM
 SG_ NM_NodeID_VDDM : 7|8@0+ (1,0) [0|0] "" TCM

BO_ 2047 VddmToAllFuncChas1DiagReqFrame: 8 VDDM
 SG_ VddmToAllFuncChas1DiagReqNpdu : 7|64@0+ (1,0) [0|0] "" PSCM1, SAS

BO_ 1908 VddmToPscm100FITbChas1DiagReqFrame: 8 VDDM
 SG_ VddmToPscm100FITbChas1DiagReqNpdu : 7|64@0+ (1,0) [0|0] "" Vector_XXX

BO_ 1904 VddmToPscmChas1DiagReqFrame: 8 VDDM
 SG_ VddmToPscmChas1DiagReqNpdu : 7|64@0+ (1,0) [0|0] "" PSCM1

BO_ 1905 VddmToRasmChas1DiagReqFrame: 8 VDDM
 SG_ VddmToRasmChas1DiagReqNpdu : 7|64@0+ (1,0) [0|0] "" Vector_XXX

BO_ 1909 VddmToRbcmChas1DiagReqFrame: 8 VDDM
 SG_ VddmToRbcmChas1DiagReqNpdu : 7|64@0+ (1,0) [0|0] "" Vector_XXX

BO_ 1906 VddmToSasChas1DiagReqFrame: 8 VDDM
 SG_ VddmToSasChas1DiagReqNpdu : 7|64@0+ (1,0) [0|0] "" SAS

CM_ SG_ 293 TrsmCluOpen1 "Confirmation flag clutch is fully open 1";
CM_ SG_ 293 TrsmCluOpen2 "Confirmation flag clutch is fully open 2";
CM_ SG_ 293 TrsmEcuTLvl "Control unit temperature level.";
CM_ SG_ 293 TrsmGearSafeAct1 "Actual gear safe Actual gear safe 1";
CM_ SG_ 293 TrsmGearSafeAct2 "Actual gear safe Actual gear safe 2";
CM_ SG_ 293 TrsmGearSafeChks "4 bit counter used in checksum calculation. N=E (modulo 16)";
CM_ SG_ 293 TrsmGearSafeCntr "8 bit checksum";
CM_ SG_ 293 TrsmGearSafeSts1 "Actual gear safe Actual gear safe ok 1";
CM_ SG_ 293 TrsmGearSafeSts2 "Actual gear safe Actual gear safe ok 2";
CM_ SG_ 293 TrsmSailStsTrsmEngSyncSpd "Transmission engine synchronization speed";
CM_ SG_ 293 TrsmSailStsTrsmSailAllwd "Transmission sail allowance";
CM_ SG_ 293 TrsmSailStsTrsmShiftMapForIsg "Transmission shift-map for ISG";
CM_ SG_ 293 TrsmSailStsTrsmSts "Transmission status.";
CM_ SG_ 373 TrsmCluTqSafeChks "E2E checksum";
CM_ SG_ 373 TrsmCluTqSafeCntr "Data counter";
CM_ SG_ 373 TrsmCluTqSafeCp1 "Actual torque capacity safe Actual torque capacity safe 1";
CM_ SG_ 373 TrsmCluTqSafeCp2 "Actual torque capacity safe Actual torque capacity safe 2";
CM_ SG_ 373 TrsmOilT2 "Transmission oil temperature";
CM_ SG_ 389 TrsmCluSlipLongDetd1 "Unwanted long slip detected 1";
CM_ SG_ 389 TrsmCluSlipLongDetd2 "Unwanted long slip detected 2";
CM_ SG_ 389 TrsmGearActAux "Transmission Gear Actual. Actual gear engaged sent by transmission supplier. ";
CM_ SG_ 128 TrsmActrPosn2TrsmActrPosn "Describes the transmission position (P, R, N, D). Can also take intermediate positions (PR, RN, ND). If error are detected on position sensors undefined is set. Transmission measured gear lever position";
CM_ SG_ 128 TrsmActrPosn2TrsmActrPosnChks "E2E checksum";
CM_ SG_ 128 TrsmActrPosn2TrsmActrPosnCntr "Data counter";
CM_ SG_ 128 TrsmGearNotAvlSts2 "TCM use signal Trsm Gear Not Available Status to inform ECM which gears is unavailable for gear shifting.Signal is used during failsafe operation Availability mode.Default 0-no gears unavailable.Bit 0-First gear EB not available.Bit 1-First gear not available.Bit X-Xth gear not available";
CM_ SG_ 128 TrsmModNotAvlSts2 "TCM uses signal Transmissions Mode Not Available Status to inform ECM which modes are unavailable (Neutral, Reverse, Drive, LockUp stuck-Off or LockUp stuck-On). Default value - 0 (no modes unavailable). Bit 0 - 7";
CM_ SG_ 128 UBoostReqByTrsm "Voltage boost request from transmission. 0 - no request, 1 - voltage boost request.";
CM_ SG_ 512 TrsmClrRdyReq "TrsmClrRdyReq";
CM_ SG_ 512 TrsmEngmtLimd3TrsmEngmtLimd "Reports if the gearbox is in a state with limited ability to transfer torque., e.g. engine standing still with open lockup.";
CM_ SG_ 512 TrsmEngmtLimd3TrsmEngmtLimdChks "Reports if the gearbox is in a state with limited ability to transfer torque., e.g. engine standing still with open lockup.";
CM_ SG_ 512 TrsmEngmtLimd3TrsmEngmtLimdCntr "Reports if the gearbox is in a state with limited ability to transfer torque., e.g. engine standing still with open lockup.";
CM_ SG_ 512 TrsmErrIndcnReq2 "TCM uses signal Transmission Error Indication Request to send a MIL-request to ECM. ECM will then act upon this request and iluminate the MIL. For VEP software, TCM transmits signal after two consecutive failed driving cycles (for a MIL-relevant code).  Default value - 0 (Off)";
CM_ SG_ 512 TrsmOilT2Sts "Transmission oil temperature status";
CM_ SG_ 74 TrsmLockChkChk " Challenge available flag";
CM_ SG_ 74 TrsmLockChkData0 " Challenge data";
CM_ SG_ 74 TrsmLockChkData1 " Challenge data";
CM_ SG_ 74 TrsmLockChkData2 " Challenge data";
CM_ SG_ 74 TrsmLockChkData3 " Challenge data";
CM_ SG_ 74 TrsmLockChkData4 " Challenge data";
CM_ SG_ 74 TrsmLockChkData5 " Challenge data";
CM_ SG_ 74 TrsmLockChkData6 " Challenge data";
CM_ SG_ 74 TrsmLockSts " TCM CEM message immo status. Can be, undefined, immobilised, motive mobilised or non motive mobilised.";
CM_ SG_ 257 TrsmModAct "Transmission mode actual. Current transmission mode signal sent from transmission supplier. Used for Stop Start, IC. 0-Warm Up.1-NIC not allowed. 2-NIC allowed. 3 TBD. 4-Neutral-1st gear mechanically engaged. 5-Neutral-Economy-Full neutral. 6/7-Transition from Engaged to Neutral or vice versa";
CM_ SG_ 257 TrsmToPrpsnCluTqRecTrsmCluTqMaxFast "Maximum crankshaft torque limitation from transmission (fast)";
CM_ SG_ 257 TrsmToPrpsnCluTqRecTrsmCluTqMaxFastFlag "Max Fast Torque Request Status.0=NotTqMaxFastRuqest,1=TqMaxFastRequest";
CM_ SG_ 257 TrsmToPrpsnCluTqRecTrsmCluTqMaxForProtn "Maximum crankshaft torque limitation from transmission (transmission protection)";
CM_ SG_ 257 TrsmToPrpsnCluTqRecTrsmCluTqMaxForProtnFlag "Max For gear box Protection Torque Request Status. 0=NotTqMaxForProtnRuqest,1=TqMaxForProtnRequest";
CM_ SG_ 257 TrsmToPrpsnCluTqRecTrsmCluTqMaxSlow "Maximum crankshaft torque limitation from transmission (slow)";
CM_ SG_ 257 TrsmToPrpsnCluTqRecTrsmCluTqMaxSlowFlag "Max Slow Torque Request Status. 0=NotTqMaxSlowRuqest,1=TqMaxSlowRequest";
CM_ SG_ 257 TrsmToPrpsnCluTqRecTrsmCluTqMinFast "Minimum crankshaft torque limitation from transmission (fast)";
CM_ SG_ 257 TrsmToPrpsnCluTqRecTrsmCluTqMinFlag "Min Torque Request Status. 0=NotTqMinRuqest,1=TqMinRequest";
CM_ SG_ 257 TrsmToPrpsnCluTqRecTrsmCluTqMinSlow "Minimum crankshaft torque limitation from transmission (slow)";
CM_ SG_ 261 TrsmGearChgProgs "Transmission gear change in progress. Transmission supplier sent signal containing informatoin regarding which phase the gear shift is in. 0 - not changing gear, 1 - start phase, 2 - tourqe phase, 3 - inertia phase, 4 - end phase.";
CM_ SG_ 261 TrsmLockUpStTar "Transmission Lock Up Target. Target state for gearbox sent by transmission supplier.  0 - open 1 - slip, 2 - microslip,  3 - fixed.";
CM_ SG_ 261 TrsmModNotAvlSts "TCM uses signal Transmissions Mode Not Available Status to inform ECM which modes are unavailable (Neutral, Reverse, Drive, LockUp stuck-Off or LockUp stuck-On). Default value - 0 (no modes unavailable). Bit 0-7";
CM_ SG_ 261 TrsmToPrpsnNReqRecTrsmNReqCtrl "Transmission To Propulsion eNgine speed Request Record. Unit: Rpm";
CM_ SG_ 261 TrsmToPrpsnNReqRecTrsmNReqMax "Transmission To Propulsion eNgine speed Request Record. Unit: Rpm";
CM_ SG_ 261 TrsmToPrpsnNReqRecTrsmNReqMin "Transmission To Propulsion eNgine speed Request Record. Unit: Rpm";
CM_ SG_ 261 TrsmTqRat "Transmission Torque Ratio. Actual ratio between the input and the output torque of the transmission and torque converter This includes torque converter effects, clutch slip effects, and all gearing effects including final drive.";
CM_ SG_ 629 TrsmEngmtLimdChks "Reports if the gearbox is in a state with limited ability to transfer torque., e.g. engine standing still with open lockup.";
CM_ SG_ 629 TrsmEngmtLimdCntr "Reports if the gearbox is in a state with limited ability to transfer torque., e.g. engine standing still with open lockup.";
CM_ SG_ 629 TrsmEngmtLimdTrsmEngmtLimd "Reports if the gearbox is in a state with limited ability to transfer torque., e.g. engine standing still with open lockup.";
CM_ SG_ 629 TrsmErrIndcnReq "TCM uses signal Transmission Error Indication Request to send a MIL-request to ECM. ECM will then act upon this request and iluminate the MIL. For VEP software, TCM transmits signal after two consecutive failed driving cycles (for a MIL-relevant code). Default value - 0 (Off)";
CM_ SG_ 629 TrsmHotSt "Transmission hot state. Indicate transmission is in hot state. 0 - Not in hot state, 1 - Hot state level 1, 2 - Hot state level 2.";
CM_ SG_ 629 TrsmReqForPfmncRedn "TCM uses signal Transmission Request For Performance Reduction to send requests to ECM to activate the functionality Intended System Degradation (ISD). ISD will stage by stage reduce the maximum allowed torque for the engine over a number of driving cycles. Default signal - 0 (false).";
CM_ SG_ 629 TrsmTqLossChks "Actual torque losses in the transmission";
CM_ SG_ 629 TrsmTqLossCntr "Actual torque losses in the transmission";
CM_ SG_ 629 TrsmTqLossTrsmTqEff "Actual torque losses in the transmission";
CM_ SG_ 629 TrsmTqLossTrsmTqLoss "Actual torque losses in the transmission";
CM_ SG_ 326 TrsmEngNTqMaxChks "TCM uses signal Transmission Engine N Torque Maximum Safe to inform ECM of the maximum allowed torque to reach the desired engine RPM. Signal is secured with a checksum calculation. Checksum";
CM_ SG_ 326 TrsmEngNTqMaxCntr "TCM uses signal Transmission Engine N Torque Maximum Safe to inform ECM of the maximum allowed torque to reach the desired engine RPM. Signal is secured with a checksum calculation. Counter";
CM_ SG_ 326 TrsmEngNTqMaxTrsmEngNTqMax "TCM uses signal Transmission Engine N Torque Maximum Safe to inform ECM of the maximum allowed torque to reach the desired engine RPM. Signal is secured with a checksum calculation. Maximum allowed torque to reach EngN req";
CM_ SG_ 326 TrsmGearNotAvlSts "TCM use signal Trsm Gear Not Available Status to inform ECM which gears is unavailable for gear shifting.Signal is used during failsafe operation Availability mode.Default 0-no gears unavailable.Bit 0-First gear EB not available.Bit 1-First gear not available.Bit X-Xth gear not available";
CM_ SG_ 326 TrsmUpShiftEstimdDurn "Time from shift request until beginning of ratio phase in transmission.";
CM_ SG_ 263 TrsmFltIndcn "TCM uses signal Transmission Fault Indication to request text message ilumination to driver. Signal is transmitted to both ECM and DIM.Signal consits of 32 slots. One slot is one unique text message. Default value is 0 (No request)";
CM_ SG_ 763 VFCVectorTCMAWBlockID "BlockID";
CM_ SG_ 763 VFCVectorTCMAWVFCid0 "VFCBitPosn0";
CM_ SG_ 763 VFCVectorTCMAWVFCid1 "VFCBitPosn1";
CM_ SG_ 763 VFCVectorTCMAWVFCid10 "VFCBitPosn10";
CM_ SG_ 763 VFCVectorTCMAWVFCid11 "VFCBitPosn11";
CM_ SG_ 763 VFCVectorTCMAWVFCid12 "VFCBitPosn12";
CM_ SG_ 763 VFCVectorTCMAWVFCid13 "VFCBitPosn13";
CM_ SG_ 763 VFCVectorTCMAWVFCid14 "VFCBitPosn14";
CM_ SG_ 763 VFCVectorTCMAWVFCid15 "VFCBitPosn15";
CM_ SG_ 763 VFCVectorTCMAWVFCid16 "VFCBitPosn16";
CM_ SG_ 763 VFCVectorTCMAWVFCid17 "VFCBitPosn17";
CM_ SG_ 763 VFCVectorTCMAWVFCid18 "VFCBitPosn18";
CM_ SG_ 763 VFCVectorTCMAWVFCid19 "VFCBitPosn19";
CM_ SG_ 763 VFCVectorTCMAWVFCid2 "VFCBitPosn2";
CM_ SG_ 763 VFCVectorTCMAWVFCid20 "VFCBitPosn20";
CM_ SG_ 763 VFCVectorTCMAWVFCid21 "VFCBitPosn21";
CM_ SG_ 763 VFCVectorTCMAWVFCid22 "VFCBitPosn22";
CM_ SG_ 763 VFCVectorTCMAWVFCid23 "VFCBitPosn23";
CM_ SG_ 763 VFCVectorTCMAWVFCid24 "VFCBitPosn24";
CM_ SG_ 763 VFCVectorTCMAWVFCid25 "VFCBitPosn25";
CM_ SG_ 763 VFCVectorTCMAWVFCid26 "VFCBitPosn26";
CM_ SG_ 763 VFCVectorTCMAWVFCid27 "VFCBitPosn27";
CM_ SG_ 763 VFCVectorTCMAWVFCid28 "VFCBitPosn28";
CM_ SG_ 763 VFCVectorTCMAWVFCid29 "VFCBitPosn29";
CM_ SG_ 763 VFCVectorTCMAWVFCid3 "VFCBitPosn3";
CM_ SG_ 763 VFCVectorTCMAWVFCid30 "VFCBitPosn30";
CM_ SG_ 763 VFCVectorTCMAWVFCid31 "VFCBitPosn31";
CM_ SG_ 763 VFCVectorTCMAWVFCid32 "VFCBitPosn32";
CM_ SG_ 763 VFCVectorTCMAWVFCid33 "VFCBitPosn33";
CM_ SG_ 763 VFCVectorTCMAWVFCid34 "VFCBitPosn34";
CM_ SG_ 763 VFCVectorTCMAWVFCid35 "VFCBitPosn35";
CM_ SG_ 763 VFCVectorTCMAWVFCid36 "VFCBitPosn36";
CM_ SG_ 763 VFCVectorTCMAWVFCid37 "VFCBitPosn37";
CM_ SG_ 763 VFCVectorTCMAWVFCid38 "VFCBitPosn38";
CM_ SG_ 763 VFCVectorTCMAWVFCid39 "VFCBitPosn39";
CM_ SG_ 763 VFCVectorTCMAWVFCid4 "VFCBitPosn4";
CM_ SG_ 763 VFCVectorTCMAWVFCid40 "VFCBitPosn40";
CM_ SG_ 763 VFCVectorTCMAWVFCid41 "VFCBitPosn41";
CM_ SG_ 763 VFCVectorTCMAWVFCid42 "VFCBitPosn42";
CM_ SG_ 763 VFCVectorTCMAWVFCid43 "VFCBitPosn43";
CM_ SG_ 763 VFCVectorTCMAWVFCid44 "VFCBitPosn44";
CM_ SG_ 763 VFCVectorTCMAWVFCid45 "VFCBitPosn45";
CM_ SG_ 763 VFCVectorTCMAWVFCid46 "VFCBitPosn46";
CM_ SG_ 763 VFCVectorTCMAWVFCid47 "VFCBitPosn47";
CM_ SG_ 763 VFCVectorTCMAWVFCid48 "VFCBitPosn48";
CM_ SG_ 763 VFCVectorTCMAWVFCid49 "VFCBitPosn49";
CM_ SG_ 763 VFCVectorTCMAWVFCid5 "VFCBitPosn5";
CM_ SG_ 763 VFCVectorTCMAWVFCid50 "VFCBitPosn50";
CM_ SG_ 763 VFCVectorTCMAWVFCid51 "VFCBitPosn51";
CM_ SG_ 763 VFCVectorTCMAWVFCid52 "VFCBitPosn52";
CM_ SG_ 763 VFCVectorTCMAWVFCid53 "VFCBitPosn53";
CM_ SG_ 763 VFCVectorTCMAWVFCid54 "VFCBitPosn54";
CM_ SG_ 763 VFCVectorTCMAWVFCid55 "VFCBitPosn55";
CM_ SG_ 763 VFCVectorTCMAWVFCid56 "VFCBitPosn56";
CM_ SG_ 763 VFCVectorTCMAWVFCid57 "VFCBitPosn57";
CM_ SG_ 763 VFCVectorTCMAWVFCid58 "VFCBitPosn58";
CM_ SG_ 763 VFCVectorTCMAWVFCid59 "VFCBitPosn59";
CM_ SG_ 763 VFCVectorTCMAWVFCid6 "VFCBitPosn6";
CM_ SG_ 763 VFCVectorTCMAWVFCid60 "VFCBitPosn60";
CM_ SG_ 763 VFCVectorTCMAWVFCid61 "VFCBitPosn61";
CM_ SG_ 763 VFCVectorTCMAWVFCid7 "VFCBitPosn7";
CM_ SG_ 763 VFCVectorTCMAWVFCid8 "VFCBitPosn8";
CM_ SG_ 763 VFCVectorTCMAWVFCid9 "VFCBitPosn9";
CM_ SG_ 1352 VFCVectorTCMBlockID "Block Identifier";
CM_ SG_ 1352 VFCVectorTCMVFCid0 "VFC0";
CM_ SG_ 1352 VFCVectorTCMVFCid1 "VFC1";
CM_ SG_ 1352 VFCVectorTCMVFCid10 "VFC10";
CM_ SG_ 1352 VFCVectorTCMVFCid11 "VFC11";
CM_ SG_ 1352 VFCVectorTCMVFCid12 "VFC12";
CM_ SG_ 1352 VFCVectorTCMVFCid13 "VFC13";
CM_ SG_ 1352 VFCVectorTCMVFCid14 "VFC14";
CM_ SG_ 1352 VFCVectorTCMVFCid15 "VFC15";
CM_ SG_ 1352 VFCVectorTCMVFCid16 "VFC16";
CM_ SG_ 1352 VFCVectorTCMVFCid17 "VFC17";
CM_ SG_ 1352 VFCVectorTCMVFCid18 "VFC18";
CM_ SG_ 1352 VFCVectorTCMVFCid19 "VFC19";
CM_ SG_ 1352 VFCVectorTCMVFCid2 "VFC2";
CM_ SG_ 1352 VFCVectorTCMVFCid20 "VFC20";
CM_ SG_ 1352 VFCVectorTCMVFCid21 "VFC21";
CM_ SG_ 1352 VFCVectorTCMVFCid22 "VFC22";
CM_ SG_ 1352 VFCVectorTCMVFCid23 "VFC23";
CM_ SG_ 1352 VFCVectorTCMVFCid24 "VFC24";
CM_ SG_ 1352 VFCVectorTCMVFCid25 "VFC25";
CM_ SG_ 1352 VFCVectorTCMVFCid26 "VFC26";
CM_ SG_ 1352 VFCVectorTCMVFCid27 "VFC27";
CM_ SG_ 1352 VFCVectorTCMVFCid28 "VFC28";
CM_ SG_ 1352 VFCVectorTCMVFCid29 "VFC29";
CM_ SG_ 1352 VFCVectorTCMVFCid3 "VFC3";
CM_ SG_ 1352 VFCVectorTCMVFCid30 "VFC30";
CM_ SG_ 1352 VFCVectorTCMVFCid31 "VFC31";
CM_ SG_ 1352 VFCVectorTCMVFCid32 "VFC32";
CM_ SG_ 1352 VFCVectorTCMVFCid33 "VFC33";
CM_ SG_ 1352 VFCVectorTCMVFCid34 "VFC34";
CM_ SG_ 1352 VFCVectorTCMVFCid35 "VFC35";
CM_ SG_ 1352 VFCVectorTCMVFCid36 "VFC36";
CM_ SG_ 1352 VFCVectorTCMVFCid37 "VFC37";
CM_ SG_ 1352 VFCVectorTCMVFCid38 "VFC38";
CM_ SG_ 1352 VFCVectorTCMVFCid39 "VFC39";
CM_ SG_ 1352 VFCVectorTCMVFCid4 "VFC4";
CM_ SG_ 1352 VFCVectorTCMVFCid40 "VFC40";
CM_ SG_ 1352 VFCVectorTCMVFCid41 "VFC41";
CM_ SG_ 1352 VFCVectorTCMVFCid42 "VFC42";
CM_ SG_ 1352 VFCVectorTCMVFCid43 "VFC43";
CM_ SG_ 1352 VFCVectorTCMVFCid44 "VFC44";
CM_ SG_ 1352 VFCVectorTCMVFCid45 "VFC45";
CM_ SG_ 1352 VFCVectorTCMVFCid46 "VFC46";
CM_ SG_ 1352 VFCVectorTCMVFCid47 "VFC47";
CM_ SG_ 1352 VFCVectorTCMVFCid48 "VFC48";
CM_ SG_ 1352 VFCVectorTCMVFCid49 "VFC49";
CM_ SG_ 1352 VFCVectorTCMVFCid5 "VFC5";
CM_ SG_ 1352 VFCVectorTCMVFCid50 "VFC50";
CM_ SG_ 1352 VFCVectorTCMVFCid51 "VFC51";
CM_ SG_ 1352 VFCVectorTCMVFCid52 "VFC52";
CM_ SG_ 1352 VFCVectorTCMVFCid53 "VFC53";
CM_ SG_ 1352 VFCVectorTCMVFCid54 "VFC54";
CM_ SG_ 1352 VFCVectorTCMVFCid55 "VFC55";
CM_ SG_ 1352 VFCVectorTCMVFCid56 "VFC56";
CM_ SG_ 1352 VFCVectorTCMVFCid57 "VFC57";
CM_ SG_ 1352 VFCVectorTCMVFCid58 "VFC58";
CM_ SG_ 1352 VFCVectorTCMVFCid59 "VFC59";
CM_ SG_ 1352 VFCVectorTCMVFCid6 "VFC6";
CM_ SG_ 1352 VFCVectorTCMVFCid60 "VFC60";
CM_ SG_ 1352 VFCVectorTCMVFCid61 "VFC61";
CM_ SG_ 1352 VFCVectorTCMVFCid7 "VFC7";
CM_ SG_ 1352 VFCVectorTCMVFCid8 "VFC8";
CM_ SG_ 1352 VFCVectorTCMVFCid9 "VFC9";
CM_ SG_ 1434 VDDMdevelpsignalgroupresp1Functiondevpsignalgroup1 "develop signal group response";
CM_ SG_ 1434 VDDMdevelpsignalgroupresp1Functiondevpsignalgroup2 "develop signal group response";
CM_ SG_ 1434 VDDMdevelpsignalgroupresp1Functiondevpsignalgroup3 "develop signal group response";
CM_ SG_ 1434 VDDMdevelpsignalgroupresp1Functiondevpsignalgroup4 "develop signal group response";
CM_ SG_ 1434 VDDMdevelpsignalgroupresp1Functiondevpsignalgroup5 "develop signal group response";
CM_ SG_ 1434 VDDMdevelpsignalgroupresp1Functiondevpsignalgroup6 "develop signal group response";
CM_ SG_ 1434 VDDMdevelpsignalgroupresp1Functiondevpsignalgroup7 "develop signal group response";
CM_ SG_ 1434 VDDMdevelpsignalgroupresp1Functiondevpsignalgroup8 "develop signal group response";
CM_ SG_ 1435 VDDMdevelpsignalgroupresp2Functiondevpsignalgroup1 "develop signal group response";
CM_ SG_ 1435 VDDMdevelpsignalgroupresp2Functiondevpsignalgroup2 "develop signal group response";
CM_ SG_ 1435 VDDMdevelpsignalgroupresp2Functiondevpsignalgroup3 "develop signal group response";
CM_ SG_ 1435 VDDMdevelpsignalgroupresp2Functiondevpsignalgroup4 "develop signal group response";
CM_ SG_ 1435 VDDMdevelpsignalgroupresp2Functiondevpsignalgroup5 "develop signal group response";
CM_ SG_ 1435 VDDMdevelpsignalgroupresp2Functiondevpsignalgroup6 "develop signal group response";
CM_ SG_ 1435 VDDMdevelpsignalgroupresp2Functiondevpsignalgroup7 "develop signal group response";
CM_ SG_ 1435 VDDMdevelpsignalgroupresp2Functiondevpsignalgroup8 "develop signal group response";
CM_ SG_ 81 AsyDataWithCmpSafeALat1Qf "IMU processed special data. Quality factor for Lateral acceleration signal";
CM_ SG_ 81 AsyDataWithCmpSafeALatWithCmp "IMU processed special data.  Compensated Lateral acceleration";
CM_ SG_ 81 AsyDataWithCmpSafeALgt1Qf "IMU processed special data. Quality factor for Longitudinal acceleration";
CM_ SG_ 81 AsyDataWithCmpSafeChks "IMU processed special data. Check sum";
CM_ SG_ 81 AsyDataWithCmpSafeCntr "IMU processed special data. Counter";
CM_ SG_ 81 AsyDataWithCmpSafeGrdtOfALgt "IMU processed special data. Derivative of Longitudinal acceleration";
CM_ SG_ 81 AsyDataWithCmpSafeYawRateQf "IMU processed special data. Quality Factor for Yaw Rate";
CM_ SG_ 81 AsyDataWithCmpSafeYawRateWithCmp "IMU processed special data. Compensated Yaw rate";
CM_ SG_ 160 ADataRawSafeALat "IMU acceleration data Lateral acceleration";
CM_ SG_ 160 ADataRawSafeALat1Qf "IMU acceleration data Quality factor for Lateral acceleration signal";
CM_ SG_ 160 ADataRawSafeALgt "IMU acceleration data Longitudinal acceleration";
CM_ SG_ 160 ADataRawSafeALgt1Qf "IMU acceleration data Quality factor for Longitudinal acceleration";
CM_ SG_ 160 ADataRawSafeAVert "IMU acceleration data Vertical acceleration";
CM_ SG_ 160 ADataRawSafeAVertQf "IMU acceleration data Quality factor for Vertical acceleration";
CM_ SG_ 160 ADataRawSafeChks "IMU acceleration data Check sum";
CM_ SG_ 160 ADataRawSafeCntr "IMU acceleration data Counter";
CM_ SG_ 400 AbsCtrlActvChks "checksum";
CM_ SG_ 400 AbsCtrlActvCntr "counter";
CM_ SG_ 400 AbsCtrlActvCtrlSts1 "Anti Blocking Systems (ABS) control is active (at least one wheel)
0 = No wheel is in Anti Blocking Systems (ABS) control
1 = At least one wheel is in Anti Blocking Systems (ABS) control";
CM_ SG_ 400 AmbTRawAmbTVal "Unfiltered ambient temp raw data in deg C. Ambient temp value";
CM_ SG_ 400 AmbTRawQly "Unfiltered ambient temp raw data in deg C. Quality Factor of the ambient temp";
CM_ SG_ 400 LatCtrlReqSafeChks "Requests for lateral control by steering actuator. Checksum";
CM_ SG_ 400 LatCtrlReqSafeCntr "Requests for lateral control by steering actuator. Counter";
CM_ SG_ 400 LatCtrlReqSafeLatCtrlModReq "Request";
CM_ SG_ 400 LatCtrlReqSafeSteerTqReq "Requests for lateral control by steering actuator. Steering wheel torque request.";
CM_ SG_ 400 LatCtrlReqSafeSteerWhlHptcWarnReq "Enable steering wheel haptic warning";
CM_ SG_ 224 CnvnReq "Intelligent charge request";
CM_ SG_ 224 DrvrCrsCtrlFctSeld "select ACC function or CC function.";
CM_ SG_ 224 EngRunngReqByParkAssi1 "Request to keep engine running during a Semi automatic parking manoeuvre.";
CM_ SG_ 224 EngRunngReqByParkAssiChks "counter,For E2E Protection";
CM_ SG_ 224 EngRunngReqByParkAssiCntr "CRC,to check the signal,For E2E Protection";
CM_ SG_ 224 VehSpdLgtA "Vehicle speed longitudinal based on wheel speed sensors and longitudinal acceleration.";
CM_ SG_ 224 VehSpdLgtChks "Checksum";
CM_ SG_ 224 VehSpdLgtCntr "Counter";
CM_ SG_ 224 VehSpdLgtQf "Quality factor for vehicle speed as measured by wheel speed sensors and longitudinal acceleration.";
CM_ SG_ 928 AmbTIndcdWithUnitAmbTIndcd "Indicated ambient temperature";
CM_ SG_ 928 AmbTIndcdWithUnitAmbTIndcdUnit "Unit of the indicated temperature";
CM_ SG_ 928 AmbTIndcdWithUnitQF "QF";
CM_ SG_ 928 CmptmtTReCmptmtTFrnt "Rear incar temperature.";
CM_ SG_ 928 CmptmtTReCmptmtTFrntQf "Rear incar temperature quality flag";
CM_ SG_ 928 CmptmtTReFanForCmptmtTRunng "Fan for component temperature requirement.";
CM_ SG_ 928 ReHvacBlowerSts "Rear HVAC blower status.";
CM_ SG_ 433 BrkPedlPsdBrkPedlNotPsdSafe "Set to 1 if brake pedal is not pressed, otherwise 0";
CM_ SG_ 433 BrkPedlPsdBrkPedlPsd "Set to 1 if brake pedal is pressed, otherwise 0";
CM_ SG_ 433 BrkPedlPsdChks "Checksum";
CM_ SG_ 433 BrkPedlPsdCntr "Counter";
CM_ SG_ 433 BrkPedlPsdQf "Quality factor";
CM_ SG_ 433 WhlSpdCircumlFrntChks "Individual wheel speed from front wheel speed sensors. Checksum";
CM_ SG_ 433 WhlSpdCircumlFrntCntr "Individual wheel speed from front wheel speed sensors. Counter";
CM_ SG_ 433 WhlSpdCircumlFrntLe "Individual wheel speed from front wheel speed sensors. Wheel speed from front left wheel speed sensor using nominal value of wheel radius.";
CM_ SG_ 433 WhlSpdCircumlFrntLeQf "Individual wheel speed from front wheel speed sensors. Qf for wheel speed sensor";
CM_ SG_ 433 WhlSpdCircumlFrntRiQf "Individual wheel speed from front wheel speed sensors. Qf for wheel speed sensor";
CM_ SG_ 433 WhlSpdCircumlFrntWhlSpdCircumlFrntRi "Individual wheel speed from front wheel speed sensors. Wheel speed from front right wheel speed sensor using nominal value of wheel radius";
CM_ SG_ 1087 ReEvapVlvSts "Status of rear evaporator valve.";
CM_ SG_ 1087 ResrvdSigForECM1 "Reserved signal 1 for ECM.";
CM_ SG_ 1087 ResrvdSigForECM2 "Reserved signal 2 for ECM.";
CM_ SG_ 1087 ResrvdSigForECM3 "Reserved signal 3 for ECM.";
CM_ SG_ 1087 ResrvdSigForECM4 "Reserved signal 4 for ECM.";
CM_ SG_ 432 AgDataRawSafeChks "IMU angular rate data. Check summa";
CM_ SG_ 432 AgDataRawSafeCntr "IMU angular rate data. Counter";
CM_ SG_ 432 AgDataRawSafeRollRate "IMU angular rate data. Roll Rate";
CM_ SG_ 432 AgDataRawSafeRollRateQf "IMU angular rate data. Quality factor for Roll Rate";
CM_ SG_ 432 AgDataRawSafeYawRate "IMU angular rate data. Yaw Rate";
CM_ SG_ 432 AgDataRawSafeYawRateQf "IMU angular rate data. Quality Factor for Yaw Rate";
CM_ SG_ 367 TrsmLockMgrReqCmd " Command to unlock or lock the transmission lock";
CM_ SG_ 367 TrsmLockMgrReqData0 " Response data";
CM_ SG_ 367 TrsmLockMgrReqData1 " Response data";
CM_ SG_ 367 TrsmLockMgrReqData2 " Response data";
CM_ SG_ 367 TrsmLockMgrReqData3 " Response data";
CM_ SG_ 367 TrsmLockMgrReqData4 " Response data";
CM_ SG_ 367 TrsmLockMgrReqData5 " Response data";
CM_ SG_ 367 TrsmLockMgrReqData6 " Response data";
CM_ SG_ 736 VehModMngtGlbSafe1CarModSts1 "CarMode Status";
CM_ SG_ 736 VehModMngtGlbSafe1CarModSubtypWdCarModSubtyp "CarMode substate status";
CM_ SG_ 736 VehModMngtGlbSafe1Chks "Checksum";
CM_ SG_ 736 VehModMngtGlbSafe1Cntr "Counter";
CM_ SG_ 736 VehModMngtGlbSafe1EgyLvlElecMai "Main energy level in the vehicle.";
CM_ SG_ 736 VehModMngtGlbSafe1EgyLvlElecSubtyp "Substate of the energy level in the vehicle.";
CM_ SG_ 736 VehModMngtGlbSafe1FltEgyCnsWdSts "High quiescent current detected by CEM via BMS.";
CM_ SG_ 736 VehModMngtGlbSafe1PwrLvlElecMai "Main Power level in the vehicle.";
CM_ SG_ 736 VehModMngtGlbSafe1PwrLvlElecSubtyp "Substate of the power level in the vehicle.";
CM_ SG_ 736 VehModMngtGlbSafe1UsgModSts "UsageMode Status";
CM_ SG_ 38 ChrgSoftSwCtrlSt "sofware control state";
CM_ SG_ 38 IntelliClimaHvacEvaprTSp "Intelligent climate target evaporator temperature";
CM_ SG_ 38 IntelliClimaHvBattInCooltFlowReq "Intelligent climate HV battery target inlet coolant flow";
CM_ SG_ 38 IntelliClimaHvBattInCooltTReq "Intelligent climate HV battery target inlet coolant temperature";
CM_ SG_ 38 IntelliClimaHvCooltHeatrTReq "Intelligent climate HV coolant heater temperature request";
CM_ SG_ 38 IntelliClimaReq "Intelligent climate request";
CM_ SG_ 38 PrpsnHvBattUsgOfChrgTarSOC "the target SOC of Battery usage mode charge to the propulsion";
CM_ SG_ 38 VFCInfoEna "VFCVectorFrame enable and disable setting";
CM_ SG_ 1123 EvaprTReEvaprTFrnt "Actual air temperature after rear evaporator.";
CM_ SG_ 1123 EvaprTReEvaprTQf "Actual air temperature quality flag after rear evaporator.";
CM_ SG_ 1123 HvacEvaprTSpRe "Set value for air temperature after evaporator in rear HVAC";
CM_ SG_ 1123 SteerSetgPen "IdPen";
CM_ SG_ 1123 SteerSetgSteerAsscLvl "Steer Assistance Level";
CM_ SG_ 1123 SteerSetgSteerMod "Steer Mode";
CM_ SG_ 784 CmptmtTFrntCmptmtTFrnt "Measured temperature in compartment. ";
CM_ SG_ 784 CmptmtTFrntFanForCmptmtTRunng "Fan for component temperature requirement.";
CM_ SG_ 784 CmptmtTFrntQf "Component temperature sensor signal quality.";
CM_ SG_ 137 HsaSt "HSA function status";
CM_ SG_ 137 LVPwrSplyErrSts "Low voltage power supply error status";
CM_ SG_ 137 WhlFastSpdSafeA "Vehicle speed longitudinal based on wheel speed sensors and longitudinal acceleration.";
CM_ SG_ 137 WhlFastSpdSafeChks "checksum";
CM_ SG_ 137 WhlFastSpdSafeCntr "counter";
CM_ SG_ 137 WhlFastSpdSafeQF "Quality factor for vehicle speed as measured by wheel speed sensors and longitudinal acceleration.";
CM_ SG_ 592 VehCfgPrmBlkIDBytePosn1 "signal block counter.";
CM_ SG_ 592 VehCfgPrmCCPBytePosn2 " (BlockID-1)*7 + 1. ";
CM_ SG_ 592 VehCfgPrmCCPBytePosn3 " (BlockID-1)*7 + 2. ";
CM_ SG_ 592 VehCfgPrmCCPBytePosn4 " (BlockID-1)*7 + 3. ";
CM_ SG_ 592 VehCfgPrmCCPBytePosn5 " (BlockID-1)*7 + 4. ";
CM_ SG_ 592 VehCfgPrmCCPBytePosn6 " (BlockID-1)*7 + 5. ";
CM_ SG_ 592 VehCfgPrmCCPBytePosn7 " (BlockID-1)*7 + 6. ";
CM_ SG_ 592 VehCfgPrmCCPBytePosn8 " (BlockID-1)*7 + 7. ";
CM_ SG_ 1015 VehCfgPrmExtBlkIDBytePosn1 "CarConfigExtended BlockID";
CM_ SG_ 1015 VehCfgPrmExtCCPBytePosn2 "CarConfigExtended BytePos2";
CM_ SG_ 1015 VehCfgPrmExtCCPBytePosn3 "CarConfigExtended BytePos3";
CM_ SG_ 1015 VehCfgPrmExtCCPBytePosn4 "CarConfigExtended BytePos4";
CM_ SG_ 1015 VehCfgPrmExtCCPBytePosn5 "CarConfigExtended BytePos5";
CM_ SG_ 1015 VehCfgPrmExtCCPBytePosn6 "CarConfigExtended BytePos6";
CM_ SG_ 1015 VehCfgPrmExtCCPBytePosn7 "CarConfigExtended BytePos7";
CM_ SG_ 1015 VehCfgPrmExtCCPBytePosn8 "CarConfigExtended BytePos8";
CM_ SG_ 775 BookChrgnActvdReq "Book Charging ACtivted Request";
CM_ SG_ 775 BookChrgSetReq "Book charging Setting Request";
CM_ SG_ 775 BookStopTiAchieved "Stop charging time Achieved";
CM_ SG_ 775 LocalBookChrgnTarVal "Battery SOC Value";
CM_ SG_ 775 RemBookChrgnTarVal "Remote Book Charging Target Value";
CM_ SG_ 823 CarTiIntForClima "CCM internal mirror of CarTiGlb. Keeps counting when the bus signal is not available.";
CM_ SG_ 823 ClimaCmptSts "Compartment climate status.";
CM_ SG_ 823 ClimaDefrstSts "Defrost status.";
CM_ SG_ 823 FrntHvacBlowerSts "Front blower status.";
CM_ SG_ 823 HeatrAirTReq "Heater air temperature request.";
CM_ SG_ 686 AbsSts "Indicates if the ABS function is temporarily or permantly disabled due to a failure.";
CM_ SG_ 686 DrvModReq "drive mode";
CM_ SG_ 686 HvacHexAirTHvacAirTForHeatrFrnt "Temperature";
CM_ SG_ 686 HvacHexAirTHvacAirTForHeatrFrntQf "Interpretation: 
SnsrDataNotOk - The accuracy of the data is undefinable
SnrsDataOk - The data is calculated with the specified accuracy";
CM_ SG_ 686 ULoWarnChks "Checksum";
CM_ SG_ 686 ULoWarnCntr "Counter";
CM_ SG_ 686 ULoWarnULoWarn "Low voltage warning at LVEEM system";
CM_ SG_ 1243 HvacAirTForRowFirstAtFlrLeEvaprTFrnt "First row left floor air temperature.";
CM_ SG_ 1243 HvacAirTForRowFirstAtFlrLeEvaprTQf "First row left floor air temperature quality flag.";
CM_ SG_ 1243 HvacAirTForRowFirstAtFlrRiEvaprTFrnt "First row right floor air temperature.";
CM_ SG_ 1243 HvacAirTForRowFirstAtFlrRiEvaprTQf "First row right floor air temperature quality flag";
CM_ SG_ 1243 HvacAirTForRowFirstAtVentLeEvaprTFrnt "First row left ventilation air temperature.";
CM_ SG_ 1243 HvacAirTForRowFirstAtVentLeEvaprTQf "First row left ventilation air temperature quality flag.";
CM_ SG_ 1243 HvacAirTForRowFirstAtVentRiEvaprTFrnt "First row right ventilation air temperature.";
CM_ SG_ 1243 HvacAirTForRowFirstAtVentRiEvaprTQf "First row right ventilation air temperature quality flag";
CM_ SG_ 1255 HvacAirTForRowSecAtFlrLeEvaprTFrnt "Second row left floor air temperature.";
CM_ SG_ 1255 HvacAirTForRowSecAtFlrLeEvaprTQf "Second row left floor air temperature quality flag.";
CM_ SG_ 1255 HvacAirTForRowSecAtFlrRiEvaprTFrnt "Second row right floor air temperature.";
CM_ SG_ 1255 HvacAirTForRowSecAtFlrRiEvaprTQf "Second row right floor air temperature quality flag.";
CM_ SG_ 1255 HvacAirTForRowSecAtVentLeEvaprTFrnt "Second row left ventilation air temperature.";
CM_ SG_ 1255 HvacAirTForRowSecAtVentLeEvaprTQf "Second row left ventilation air temperature quality flag.";
CM_ SG_ 1255 HvacAirTForRowSecAtVentRiEvaprTFrnt "Second row right ventilation air temperature.";
CM_ SG_ 1255 HvacAirTForRowSecAtVentRiEvaprTQf "Second row right ventilation air temperature quality flag.";
CM_ SG_ 1267 EscStChks "Information on activation/ deactivation of Electronic Stability Control (ESC) Checksum for Esc state";
CM_ SG_ 1267 EscStCntr "Information on activation/ deactivation of Electronic Stability Control (ESC) Counter for Esc state";
CM_ SG_ 1267 EscStEscSt "Information on activation/ deactivation of Electronic Stability Control (ESC) Esc state information for Esc ON, Esc OFF or Esc Sport";
CM_ SG_ 1267 HvacCondsorTEvaprTFrnt "heat pump inner condensor actual temperature.";
CM_ SG_ 1267 HvacCondsorTEvaprTQf "heat pump inner condensor actual temperature quality flag.";
CM_ SG_ 1267 HvacCondsorTspEvaprTFrnt "heat pump inner condensor target temperture.";
CM_ SG_ 1267 HvacCondsorTspEvaprTQf "heat pump inner condensor target temperture signal quality.";
CM_ SG_ 1267 HvacOsaAndRecActrQfForHp "Recirculation ratio for HVAC from CCM to Heatpump.";
CM_ SG_ 1099 AmbTEstimdAmbTEstimd "Estimated/filtered/modelled amibient temperature based on information from ambient temp sensor and all other available temperature sensors and vehicle information.  Estimated ambient temperature";
CM_ SG_ 1099 AmbTEstimdQf "Estimated/filtered/modelled amibient temperature based on information from ambient temp sensor and all other available temperature sensors and vehicle information.  Quality factor for estimated signal";
CM_ SG_ 1099 BrkTracCtrlActv "Indicates InCtrl if brake traction control (TC) is active on at least one wheel.";
CM_ SG_ 1099 HvacHeatgReq "Hvac heating request";
CM_ SG_ 1099 WhlRotToothCntrChks "check sum";
CM_ SG_ 1099 WhlRotToothCntrCntr "counter";
CM_ SG_ 1099 WhlRotToothCntrFrntLe "Wheel rotation ticks for each individual wheel. Wheel rotation impuls counter front left. For one complete wheel revolution the counter will increase by 96 (with 48 magnetic pole-pairs).";
CM_ SG_ 1099 WhlRotToothCntrFrntRi "Wheel rotation ticks for each individual wheel. Wheel rotation impuls counter front right. For one complete wheel revolution the counter will increase by 96 (with 48 magnetic pole-pairs).";
CM_ SG_ 1099 WhlRotToothCntrReLe "Wheel rotation ticks for each individual wheel. Wheel rotation impuls counter rear left. For one complete wheel revolution the counter will increase by 96 (with 48 magnetic pole-pairs).";
CM_ SG_ 1099 WhlRotToothCntrReRi "Wheel rotation ticks for each individual wheel. Wheel rotation impuls counter rear right. For one complete wheel revolution the counter will increase by 96 (with 48 magnetic pole-pairs).";
CM_ SG_ 26 AgDataCmpQualityPitchRateCmpQuality "Quality of offset compensation for pitchrate";
CM_ SG_ 26 AgDataCmpQualityRollRateCmpQuality "Quality of offset compensation for rollrate";
CM_ SG_ 26 AgDataCmpQualityYawRateCmpQuality "Quality of offset compensation for yawrate";
CM_ SG_ 26 BattURaw "Battery Voltage From BMS";
CM_ SG_ 26 EgyRgnLvlSet "This signal represents the setting of the energy regeneration level.
0x0: level1
0x1: level2
0x2: level3
0x3: level4";
CM_ SG_ 1159 VehMtnStChks "Vehicle motion state information based on wheel speed sensors. Provides information about vehicle stand still and vehicle rolling direction. Checksum for vehicle motion state";
CM_ SG_ 1159 VehMtnStCntr "Vehicle motion state information based on wheel speed sensors. Provides information about vehicle stand still and vehicle rolling direction. Counter for vehicle motion state";
CM_ SG_ 1159 VehMtnStVehMtnSt "Vehicle motion state information based on wheel speed sensors. Provides information about vehicle stand still and vehicle rolling direction. Vehicle motion state";
CM_ SG_ 864 CarTiGlb "Presents a tiime value that shall be used by all ECUs to time-stamp diagnsotic trouble codes (DTC) according to the requirements for Global DTC snapshot data.";
CM_ SG_ 864 HvacHeatrInletTempReqEvaprTFrnt "Front evaporator temperature.";
CM_ SG_ 864 HvacHeatrInletTempReqEvaprTQf "Front evaporator signal quality.";
CM_ SG_ 864 ProfPenSts1 "Signal communicates which profile that is active in the car
(Personal settings).";
CM_ SG_ 864 SaveSetgToMemPrmnt "Signal for personal settings saving concept
0: Profile locked, no saving to be performed
1: On the event (toggle 0 to 1) settings shall be saved (manually saving)
2: Automatic saving";
CM_ SG_ 896 VehBattUSysU "Vehicle System Voltage At 12V side";
CM_ SG_ 896 VehBattUSysUQf "Present vehicle voltage measured by CEM with QF";
CM_ SG_ 513 ImobEngMgrReq3ImobEngDataMgrReq0 "Command from CEM to IGM with desired immo status and 7 bytes of response Byte 0";
CM_ SG_ 513 ImobEngMgrReq3ImobEngDataMgrReq1 "Command from CEM to IGM with desired immo status and 7 bytes of response Byte 1";
CM_ SG_ 513 ImobEngMgrReq3ImobEngDataMgrReq2 "Command from CEM to IGM with desired immo status and 7 bytes of response Byte 2";
CM_ SG_ 513 ImobEngMgrReq3ImobEngDataMgrReq3 "Command from CEM to IGM with desired immo status and 7 bytes of response Byte 3";
CM_ SG_ 513 ImobEngMgrReq3ImobEngDataMgrReq4 "Command from CEM to IGM with desired immo status and 7 bytes of response Byte 4";
CM_ SG_ 513 ImobEngMgrReq3ImobEngDataMgrReq5 "Command from CEM to IGM with desired immo status and 7 bytes of response Byte 5";
CM_ SG_ 513 ImobEngMgrReq3ImobEngDataMgrReq6 "Command from CEM to IGM with desired immo status and 7 bytes of response Byte 6";
CM_ SG_ 513 ImobEngMgrReq3ImobEngMgrCmdTar1 "Command from CEM to IGM with desired immo status and 7 bytes of response Command from CEM";
CM_ SG_ 17 GearPrkgAssiReqGroupChks "checksum";
CM_ SG_ 17 GearPrkgAssiReqGroupCntr "counter";
CM_ SG_ 17 GearPrkgAssiReqGroupGearPrkgAssiReq1 "The target gear request";
CM_ SG_ 17 LgtCtrlModReqSafeChks "checksum";
CM_ SG_ 17 LgtCtrlModReqSafeCntr "counter";
CM_ SG_ 17 LgtCtrlModReqSafeLgtCtrlModReqSafe "Ctrl mode";
CM_ SG_ 17 LgtCtrlModReqSafeLgtFctFailr "Failure mode";
CM_ SG_ 17 MvBattRlyStsChks "CheckSum";
CM_ SG_ 17 MvBattRlyStsCntr "Counter";
CM_ SG_ 17 MvBattRlyStsMvBattRlySts "Actual relay position";
CM_ SG_ 17 PrpsnHvBattUsgModReq "hight voltage power mode request";
CM_ SG_ 496 BkpOfDstTrvld "total traveled distance.";
CM_ SG_ 496 StandStillMgrStsForHld1 "Brake systen hold status";
CM_ SG_ 496 StandStillMgrStsForHldChks "chks";
CM_ SG_ 496 StandStillMgrStsForHldCntr "cntr";
CM_ SG_ 580 IDcDcActLoSideChks "Actul current output checksum";
CM_ SG_ 580 IDcDcActLoSideCntr "Actul current output counter";
CM_ SG_ 580 IDcDcActLoSideIDcDcActLoSide "Actul current output";
CM_ SG_ 580 MvDcDcActLoSideChks "This signal is ASIL-B classified End to End Checksum.";
CM_ SG_ 580 MvDcDcActLoSideCntr "This signal is ASIL-B classified End to End Counter";
CM_ SG_ 580 MvDcDcActLoSideI "Actual current measured at the low voltage side.";
CM_ SG_ 580 MvDcDcActLoSideU "Actual voltage measured at the low voltage side.";
CM_ SG_ 439 WhlSpdCircumlReChks "Individual wheel speed from rear wheel speed sensors. Checksum";
CM_ SG_ 439 WhlSpdCircumlReCntr "Individual wheel speed from rear wheel speed sensors. Counter";
CM_ SG_ 439 WhlSpdCircumlReLe "Individual wheel speed from rear wheel speed sensors. Wheel speed from rear left wheel speed sensor using nominal value of wheel radius.";
CM_ SG_ 439 WhlSpdCircumlReLeQf "Individual wheel speed from rear wheel speed sensors. Qf for wheel speed sensor";
CM_ SG_ 439 WhlSpdCircumlReRi "Individual wheel speed from rear wheel speed sensors. Wheel speed from rear right wheel speed sensor using nominal value of wheel radius.";
CM_ SG_ 439 WhlSpdCircumlReRiQf "Individual wheel speed from rear wheel speed sensors. Qf for wheel speed sensor";
CM_ SG_ 52 CrashStsSafeChks "Checksum for E2E";
CM_ SG_ 52 CrashStsSafeCntr "Counter for E2E";
CM_ SG_ 52 CrashStsSafeSts "Information if a crash has been detected by SRS.";
BA_DEF_ BO_ "GenMsgSendType" ENUM "cyclic", "spontaneous", "not-used", "not-used", "not-used", "cyclicAndSpontaneous", "not-used", "cyclicIfActive", "NoMsgSendType"; // [us]
BA_DEF_ BO_ "GenMsgCycleTime" INT 0 65536; // [ms]
BA_DEF_ BO_ "GenMsgStartDelayTime" INT 0 65536; // [ms]
BA_DEF_ BO_ "GenMsgDelayTime" INT 0 65536; // [ms]
BA_DEF_ SG_ "GenSigSendType" ENUM "Cyclic","OnWrite","OnWriteWithRepetition","OnChange","OnChangeWithRepetition","IfActive","IfActiveWithRepetition","NoSigSendType";
BA_DEF_ SG_ "GenSigStartValue" HEX 0 80000000;
BA_DEF_ BO_ "GenMsgILSupport" ENUM "No","Yes";
BA_DEF_ BO_ "NmAsrMessage" ENUM "No","Yes";
BA_DEF_ SG_ "GenSigFuncType" ENUM "NoFunction","n/a","n/a","n/a","n/a","n/a","n/a","n/a","n/a","n/a","n/a","n/a","n/a","n/a","n/a","CHK","CNTR","n/a","n/a","n/a","CNTR_AR_01","CRC_AR_01_BOTH","CRC_AR_01_ALT","CRC_AR_01_LOW","CRC_AR_01_NIBBLE","CNTR_AR_04","CRC_AR_04A","CNTR_AR_05","CRC_AR_05";
BA_DEF_ SG_ "GenSigDataID" STRING;

BA_DEF_DEF_ "GenSigStartValue" 0;
BA_DEF_DEF_ "GenSigSendType" "NoSigSendType";
BA_DEF_DEF_ "GenMsgCycleTime" 0;
BA_DEF_DEF_ "GenMsgDelayTime" 0;
BA_DEF_DEF_ "GenMsgStartDelayTime" 0;
BA_DEF_DEF_ "GenMsgSendType" "NoMsgSendType";
BA_DEF_DEF_ "GenMsgILSupport" "Yes";
BA_DEF_DEF_ "NmAsrMessage" "No";
BA_DEF_DEF_ "GenSigFuncType" "NoFunction";
BA_DEF_DEF_ "GenSigDataID" "";
// Frame: TcmChas1Fr05
BA_ "GenMsgSendType" BO_ 293 0;
BA_ "GenMsgCycleTime" BO_ 293 70.000;
BA_ "GenSigSendType" SG_ 293 TrsmCluOpen1 0;
BA_ "GenSigSendType" SG_ 293 TrsmCluOpen2 0;
BA_ "GenSigSendType" SG_ 293 TrsmEcuTLvl 0;
BA_ "GenSigSendType" SG_ 293 TrsmGearSafeAct1 0;
BA_ "GenSigSendType" SG_ 293 TrsmGearSafeAct2 0;
BA_ "GenSigSendType" SG_ 293 TrsmGearSafeChks 0;
BA_ "GenSigFuncType" SG_ 293 TrsmGearSafeChks 15;
BA_ "GenSigDataID" SG_ 293 TrsmGearSafeChks "0xAC";
BA_ "GenSigSendType" SG_ 293 TrsmGearSafeCntr 0;
BA_ "GenSigFuncType" SG_ 293 TrsmGearSafeCntr 16;
BA_ "GenSigSendType" SG_ 293 TrsmGearSafeSts1 0;
BA_ "GenSigSendType" SG_ 293 TrsmGearSafeSts2 0;
BA_ "GenSigSendType" SG_ 293 TrsmSailStsTrsmEngSyncSpd 0;
BA_ "GenSigSendType" SG_ 293 TrsmSailStsTrsmSailAllwd 0;
BA_ "GenSigSendType" SG_ 293 TrsmSailStsTrsmShiftMapForIsg 0;
BA_ "GenSigSendType" SG_ 293 TrsmSailStsTrsmSts 0;
// Frame: TcmChas1Fr06
BA_ "GenMsgSendType" BO_ 373 0;
BA_ "GenMsgCycleTime" BO_ 373 150.000;
BA_ "GenSigSendType" SG_ 373 TrsmCluTqSafeChks 0;
BA_ "GenSigFuncType" SG_ 373 TrsmCluTqSafeChks 15;
BA_ "GenSigDataID" SG_ 373 TrsmCluTqSafeChks "0xAB";
BA_ "GenSigSendType" SG_ 373 TrsmCluTqSafeCntr 0;
BA_ "GenSigFuncType" SG_ 373 TrsmCluTqSafeCntr 16;
BA_ "GenSigSendType" SG_ 373 TrsmCluTqSafeCp1 0;
BA_ "GenSigSendType" SG_ 373 TrsmCluTqSafeCp2 0;
BA_ "GenSigStartValue" SG_ 373 TrsmOilT2 60;
BA_ "GenSigSendType" SG_ 373 TrsmOilT2 0;
// Frame: TcmChas1Fr07
BA_ "GenMsgSendType" BO_ 389 0;
BA_ "GenMsgCycleTime" BO_ 389 150.000;
BA_ "GenSigSendType" SG_ 389 TrsmCluSlipLongDetd1 0;
BA_ "GenSigSendType" SG_ 389 TrsmCluSlipLongDetd2 0;
BA_ "GenSigSendType" SG_ 389 TrsmGearActAux 0;
// Frame: TcmChas1Fr08
BA_ "GenMsgSendType" BO_ 128 0;
BA_ "GenMsgCycleTime" BO_ 128 30.000;
BA_ "GenSigStartValue" SG_ 128 TrsmActrPosn2TrsmActrPosn 7;
BA_ "GenSigSendType" SG_ 128 TrsmActrPosn2TrsmActrPosn 0;
BA_ "GenSigSendType" SG_ 128 TrsmActrPosn2TrsmActrPosnChks 0;
BA_ "GenSigFuncType" SG_ 128 TrsmActrPosn2TrsmActrPosnChks 15;
BA_ "GenSigDataID" SG_ 128 TrsmActrPosn2TrsmActrPosnChks "0xD2";
BA_ "GenSigSendType" SG_ 128 TrsmActrPosn2TrsmActrPosnCntr 0;
BA_ "GenSigFuncType" SG_ 128 TrsmActrPosn2TrsmActrPosnCntr 16;
BA_ "GenSigSendType" SG_ 128 TrsmGearNotAvlSts2 0;
BA_ "GenSigSendType" SG_ 128 TrsmModNotAvlSts2 0;
BA_ "GenSigSendType" SG_ 128 UBoostReqByTrsm 0;
// Frame: TcmChas1Fr09
BA_ "GenMsgSendType" BO_ 512 0;
BA_ "GenMsgCycleTime" BO_ 512 200.000;
BA_ "GenSigSendType" SG_ 512 TrsmClrRdyReq 0;
BA_ "GenSigSendType" SG_ 512 TrsmEngmtLimd3TrsmEngmtLimd 0;
BA_ "GenSigSendType" SG_ 512 TrsmEngmtLimd3TrsmEngmtLimdChks 0;
BA_ "GenSigFuncType" SG_ 512 TrsmEngmtLimd3TrsmEngmtLimdChks 15;
BA_ "GenSigDataID" SG_ 512 TrsmEngmtLimd3TrsmEngmtLimdChks "0xD5";
BA_ "GenSigSendType" SG_ 512 TrsmEngmtLimd3TrsmEngmtLimdCntr 0;
BA_ "GenSigFuncType" SG_ 512 TrsmEngmtLimd3TrsmEngmtLimdCntr 16;
BA_ "GenSigSendType" SG_ 512 TrsmErrIndcnReq2 0;
BA_ "GenSigSendType" SG_ 512 TrsmOilT2Sts 0;
// Frame: TcmChas1Fr10
BA_ "GenMsgSendType" BO_ 74 0;
BA_ "GenMsgCycleTime" BO_ 74 50.000;
BA_ "GenSigSendType" SG_ 74 TrsmLockChkChk 0;
BA_ "GenSigSendType" SG_ 74 TrsmLockChkData0 0;
BA_ "GenSigSendType" SG_ 74 TrsmLockChkData1 0;
BA_ "GenSigSendType" SG_ 74 TrsmLockChkData2 0;
BA_ "GenSigSendType" SG_ 74 TrsmLockChkData3 0;
BA_ "GenSigSendType" SG_ 74 TrsmLockChkData4 0;
BA_ "GenSigSendType" SG_ 74 TrsmLockChkData5 0;
BA_ "GenSigSendType" SG_ 74 TrsmLockChkData6 0;
BA_ "GenSigSendType" SG_ 74 TrsmLockSts 0;
// Frame: TcmChas1Fr11
BA_ "GenMsgSendType" BO_ 257 0;
BA_ "GenMsgCycleTime" BO_ 257 15.000;
BA_ "GenSigSendType" SG_ 257 TrsmModAct 0;
BA_ "GenSigStartValue" SG_ 257 TrsmToPrpsnCluTqRecTrsmCluTqMaxFast 2047;
BA_ "GenSigSendType" SG_ 257 TrsmToPrpsnCluTqRecTrsmCluTqMaxFast 0;
BA_ "GenSigSendType" SG_ 257 TrsmToPrpsnCluTqRecTrsmCluTqMaxFastFlag 0;
BA_ "GenSigStartValue" SG_ 257 TrsmToPrpsnCluTqRecTrsmCluTqMaxForProtn 2047;
BA_ "GenSigSendType" SG_ 257 TrsmToPrpsnCluTqRecTrsmCluTqMaxForProtn 0;
BA_ "GenSigSendType" SG_ 257 TrsmToPrpsnCluTqRecTrsmCluTqMaxForProtnFlag 0;
BA_ "GenSigStartValue" SG_ 257 TrsmToPrpsnCluTqRecTrsmCluTqMaxSlow 2047;
BA_ "GenSigSendType" SG_ 257 TrsmToPrpsnCluTqRecTrsmCluTqMaxSlow 0;
BA_ "GenSigSendType" SG_ 257 TrsmToPrpsnCluTqRecTrsmCluTqMaxSlowFlag 0;
BA_ "GenSigSendType" SG_ 257 TrsmToPrpsnCluTqRecTrsmCluTqMinFast 0;
BA_ "GenSigSendType" SG_ 257 TrsmToPrpsnCluTqRecTrsmCluTqMinFlag 0;
BA_ "GenSigSendType" SG_ 257 TrsmToPrpsnCluTqRecTrsmCluTqMinSlow 0;
// Frame: TcmChas1Fr12
BA_ "GenMsgSendType" BO_ 261 0;
BA_ "GenMsgCycleTime" BO_ 261 15.000;
BA_ "GenSigSendType" SG_ 261 TrsmGearChgProgs 0;
BA_ "GenSigSendType" SG_ 261 TrsmLockUpStTar 0;
BA_ "GenSigSendType" SG_ 261 TrsmModNotAvlSts 0;
BA_ "GenSigSendType" SG_ 261 TrsmToPrpsnNReqRecTrsmNReqCtrl 0;
BA_ "GenSigStartValue" SG_ 261 TrsmToPrpsnNReqRecTrsmNReqMax 12767;
BA_ "GenSigSendType" SG_ 261 TrsmToPrpsnNReqRecTrsmNReqMax 0;
BA_ "GenSigSendType" SG_ 261 TrsmToPrpsnNReqRecTrsmNReqMin 0;
BA_ "GenSigSendType" SG_ 261 TrsmTqRat 0;
// Frame: TcmChas1Fr13
BA_ "GenMsgSendType" BO_ 629 0;
BA_ "GenMsgCycleTime" BO_ 629 100.000;
BA_ "GenSigSendType" SG_ 629 TrsmEngmtLimdChks 0;
BA_ "GenSigFuncType" SG_ 629 TrsmEngmtLimdChks 15;
BA_ "GenSigDataID" SG_ 629 TrsmEngmtLimdChks "0x6A";
BA_ "GenSigSendType" SG_ 629 TrsmEngmtLimdCntr 0;
BA_ "GenSigFuncType" SG_ 629 TrsmEngmtLimdCntr 16;
BA_ "GenSigSendType" SG_ 629 TrsmEngmtLimdTrsmEngmtLimd 0;
BA_ "GenSigSendType" SG_ 629 TrsmErrIndcnReq 0;
BA_ "GenSigSendType" SG_ 629 TrsmHotSt 0;
BA_ "GenSigSendType" SG_ 629 TrsmReqForPfmncRedn 0;
BA_ "GenSigSendType" SG_ 629 TrsmTqLossChks 0;
BA_ "GenSigFuncType" SG_ 629 TrsmTqLossChks 15;
BA_ "GenSigDataID" SG_ 629 TrsmTqLossChks "0x6B";
BA_ "GenSigSendType" SG_ 629 TrsmTqLossCntr 0;
BA_ "GenSigFuncType" SG_ 629 TrsmTqLossCntr 16;
BA_ "GenSigSendType" SG_ 629 TrsmTqLossTrsmTqEff 0;
BA_ "GenSigSendType" SG_ 629 TrsmTqLossTrsmTqLoss 0;
// Frame: TcmChas1Fr14
BA_ "GenMsgSendType" BO_ 326 0;
BA_ "GenMsgCycleTime" BO_ 326 20.000;
BA_ "GenSigSendType" SG_ 326 TrsmEngNTqMaxChks 0;
BA_ "GenSigFuncType" SG_ 326 TrsmEngNTqMaxChks 15;
BA_ "GenSigDataID" SG_ 326 TrsmEngNTqMaxChks "0x42";
BA_ "GenSigSendType" SG_ 326 TrsmEngNTqMaxCntr 0;
BA_ "GenSigFuncType" SG_ 326 TrsmEngNTqMaxCntr 16;
BA_ "GenSigStartValue" SG_ 326 TrsmEngNTqMaxTrsmEngNTqMax 1024;
BA_ "GenSigSendType" SG_ 326 TrsmEngNTqMaxTrsmEngNTqMax 0;
BA_ "GenSigSendType" SG_ 326 TrsmGearNotAvlSts 0;
BA_ "GenSigSendType" SG_ 326 TrsmUpShiftEstimdDurn 0;
// Frame: TcmChas1Fr15
BA_ "GenMsgSendType" BO_ 263 0;
BA_ "GenMsgCycleTime" BO_ 263 15.000;
BA_ "GenSigSendType" SG_ 263 TrsmFltIndcn 0;
// Frame: TCMChas1Fr18
BA_ "GenMsgSendType" BO_ 763 0;
BA_ "GenMsgCycleTime" BO_ 763 145.000;
BA_ "GenSigSendType" SG_ 763 VFCVectorTCMAWBlockID 0;
BA_ "GenSigSendType" SG_ 763 VFCVectorTCMAWVFCid0 0;
BA_ "GenSigSendType" SG_ 763 VFCVectorTCMAWVFCid1 0;
BA_ "GenSigSendType" SG_ 763 VFCVectorTCMAWVFCid10 0;
BA_ "GenSigSendType" SG_ 763 VFCVectorTCMAWVFCid11 0;
BA_ "GenSigSendType" SG_ 763 VFCVectorTCMAWVFCid12 0;
BA_ "GenSigSendType" SG_ 763 VFCVectorTCMAWVFCid13 0;
BA_ "GenSigSendType" SG_ 763 VFCVectorTCMAWVFCid14 0;
BA_ "GenSigSendType" SG_ 763 VFCVectorTCMAWVFCid15 0;
BA_ "GenSigSendType" SG_ 763 VFCVectorTCMAWVFCid16 0;
BA_ "GenSigSendType" SG_ 763 VFCVectorTCMAWVFCid17 0;
BA_ "GenSigSendType" SG_ 763 VFCVectorTCMAWVFCid18 0;
BA_ "GenSigSendType" SG_ 763 VFCVectorTCMAWVFCid19 0;
BA_ "GenSigSendType" SG_ 763 VFCVectorTCMAWVFCid2 0;
BA_ "GenSigSendType" SG_ 763 VFCVectorTCMAWVFCid20 0;
BA_ "GenSigSendType" SG_ 763 VFCVectorTCMAWVFCid21 0;
BA_ "GenSigSendType" SG_ 763 VFCVectorTCMAWVFCid22 0;
BA_ "GenSigSendType" SG_ 763 VFCVectorTCMAWVFCid23 0;
BA_ "GenSigSendType" SG_ 763 VFCVectorTCMAWVFCid24 0;
BA_ "GenSigSendType" SG_ 763 VFCVectorTCMAWVFCid25 0;
BA_ "GenSigSendType" SG_ 763 VFCVectorTCMAWVFCid26 0;
BA_ "GenSigSendType" SG_ 763 VFCVectorTCMAWVFCid27 0;
BA_ "GenSigSendType" SG_ 763 VFCVectorTCMAWVFCid28 0;
BA_ "GenSigSendType" SG_ 763 VFCVectorTCMAWVFCid29 0;
BA_ "GenSigSendType" SG_ 763 VFCVectorTCMAWVFCid3 0;
BA_ "GenSigSendType" SG_ 763 VFCVectorTCMAWVFCid30 0;
BA_ "GenSigSendType" SG_ 763 VFCVectorTCMAWVFCid31 0;
BA_ "GenSigSendType" SG_ 763 VFCVectorTCMAWVFCid32 0;
BA_ "GenSigSendType" SG_ 763 VFCVectorTCMAWVFCid33 0;
BA_ "GenSigSendType" SG_ 763 VFCVectorTCMAWVFCid34 0;
BA_ "GenSigSendType" SG_ 763 VFCVectorTCMAWVFCid35 0;
BA_ "GenSigSendType" SG_ 763 VFCVectorTCMAWVFCid36 0;
BA_ "GenSigSendType" SG_ 763 VFCVectorTCMAWVFCid37 0;
BA_ "GenSigSendType" SG_ 763 VFCVectorTCMAWVFCid38 0;
BA_ "GenSigSendType" SG_ 763 VFCVectorTCMAWVFCid39 0;
BA_ "GenSigSendType" SG_ 763 VFCVectorTCMAWVFCid4 0;
BA_ "GenSigSendType" SG_ 763 VFCVectorTCMAWVFCid40 0;
BA_ "GenSigSendType" SG_ 763 VFCVectorTCMAWVFCid41 0;
BA_ "GenSigSendType" SG_ 763 VFCVectorTCMAWVFCid42 0;
BA_ "GenSigSendType" SG_ 763 VFCVectorTCMAWVFCid43 0;
BA_ "GenSigSendType" SG_ 763 VFCVectorTCMAWVFCid44 0;
BA_ "GenSigSendType" SG_ 763 VFCVectorTCMAWVFCid45 0;
BA_ "GenSigSendType" SG_ 763 VFCVectorTCMAWVFCid46 0;
BA_ "GenSigSendType" SG_ 763 VFCVectorTCMAWVFCid47 0;
BA_ "GenSigSendType" SG_ 763 VFCVectorTCMAWVFCid48 0;
BA_ "GenSigSendType" SG_ 763 VFCVectorTCMAWVFCid49 0;
BA_ "GenSigSendType" SG_ 763 VFCVectorTCMAWVFCid5 0;
BA_ "GenSigSendType" SG_ 763 VFCVectorTCMAWVFCid50 0;
BA_ "GenSigSendType" SG_ 763 VFCVectorTCMAWVFCid51 0;
BA_ "GenSigSendType" SG_ 763 VFCVectorTCMAWVFCid52 0;
BA_ "GenSigSendType" SG_ 763 VFCVectorTCMAWVFCid53 0;
BA_ "GenSigSendType" SG_ 763 VFCVectorTCMAWVFCid54 0;
BA_ "GenSigSendType" SG_ 763 VFCVectorTCMAWVFCid55 0;
BA_ "GenSigSendType" SG_ 763 VFCVectorTCMAWVFCid56 0;
BA_ "GenSigSendType" SG_ 763 VFCVectorTCMAWVFCid57 0;
BA_ "GenSigSendType" SG_ 763 VFCVectorTCMAWVFCid58 0;
BA_ "GenSigSendType" SG_ 763 VFCVectorTCMAWVFCid59 0;
BA_ "GenSigSendType" SG_ 763 VFCVectorTCMAWVFCid6 0;
BA_ "GenSigSendType" SG_ 763 VFCVectorTCMAWVFCid60 0;
BA_ "GenSigSendType" SG_ 763 VFCVectorTCMAWVFCid61 0;
BA_ "GenSigSendType" SG_ 763 VFCVectorTCMAWVFCid7 0;
BA_ "GenSigSendType" SG_ 763 VFCVectorTCMAWVFCid8 0;
BA_ "GenSigSendType" SG_ 763 VFCVectorTCMAWVFCid9 0;
// Frame: TcmChas1NMFr
BA_ "GenMsgSendType" BO_ 1328 1;
BA_ "GenMsgDelayTime" BO_ 1328 20.000;
BA_ "GenMsgILSupport" BO_ 1328 0;
BA_ "NmAsrMessage" BO_ 1328 1;
// Frame: TCMChas1VFCVectorFr
BA_ "GenMsgSendType" BO_ 1352 1;
BA_ "GenMsgDelayTime" BO_ 1352 495.000;
BA_ "GenSigSendType" SG_ 1352 VFCVectorTCMBlockID 1;
BA_ "GenSigSendType" SG_ 1352 VFCVectorTCMVFCid0 1;
BA_ "GenSigSendType" SG_ 1352 VFCVectorTCMVFCid1 1;
BA_ "GenSigSendType" SG_ 1352 VFCVectorTCMVFCid10 1;
BA_ "GenSigSendType" SG_ 1352 VFCVectorTCMVFCid11 1;
BA_ "GenSigSendType" SG_ 1352 VFCVectorTCMVFCid12 1;
BA_ "GenSigSendType" SG_ 1352 VFCVectorTCMVFCid13 1;
BA_ "GenSigSendType" SG_ 1352 VFCVectorTCMVFCid14 1;
BA_ "GenSigSendType" SG_ 1352 VFCVectorTCMVFCid15 1;
BA_ "GenSigSendType" SG_ 1352 VFCVectorTCMVFCid16 1;
BA_ "GenSigSendType" SG_ 1352 VFCVectorTCMVFCid17 1;
BA_ "GenSigSendType" SG_ 1352 VFCVectorTCMVFCid18 1;
BA_ "GenSigSendType" SG_ 1352 VFCVectorTCMVFCid19 1;
BA_ "GenSigSendType" SG_ 1352 VFCVectorTCMVFCid2 1;
BA_ "GenSigSendType" SG_ 1352 VFCVectorTCMVFCid20 1;
BA_ "GenSigSendType" SG_ 1352 VFCVectorTCMVFCid21 1;
BA_ "GenSigSendType" SG_ 1352 VFCVectorTCMVFCid22 1;
BA_ "GenSigSendType" SG_ 1352 VFCVectorTCMVFCid23 1;
BA_ "GenSigSendType" SG_ 1352 VFCVectorTCMVFCid24 1;
BA_ "GenSigSendType" SG_ 1352 VFCVectorTCMVFCid25 1;
BA_ "GenSigSendType" SG_ 1352 VFCVectorTCMVFCid26 1;
BA_ "GenSigSendType" SG_ 1352 VFCVectorTCMVFCid27 1;
BA_ "GenSigSendType" SG_ 1352 VFCVectorTCMVFCid28 1;
BA_ "GenSigSendType" SG_ 1352 VFCVectorTCMVFCid29 1;
BA_ "GenSigSendType" SG_ 1352 VFCVectorTCMVFCid3 1;
BA_ "GenSigSendType" SG_ 1352 VFCVectorTCMVFCid30 1;
BA_ "GenSigSendType" SG_ 1352 VFCVectorTCMVFCid31 1;
BA_ "GenSigSendType" SG_ 1352 VFCVectorTCMVFCid32 1;
BA_ "GenSigSendType" SG_ 1352 VFCVectorTCMVFCid33 1;
BA_ "GenSigSendType" SG_ 1352 VFCVectorTCMVFCid34 1;
BA_ "GenSigSendType" SG_ 1352 VFCVectorTCMVFCid35 1;
BA_ "GenSigSendType" SG_ 1352 VFCVectorTCMVFCid36 1;
BA_ "GenSigSendType" SG_ 1352 VFCVectorTCMVFCid37 1;
BA_ "GenSigSendType" SG_ 1352 VFCVectorTCMVFCid38 1;
BA_ "GenSigSendType" SG_ 1352 VFCVectorTCMVFCid39 1;
BA_ "GenSigSendType" SG_ 1352 VFCVectorTCMVFCid4 1;
BA_ "GenSigSendType" SG_ 1352 VFCVectorTCMVFCid40 1;
BA_ "GenSigSendType" SG_ 1352 VFCVectorTCMVFCid41 1;
BA_ "GenSigSendType" SG_ 1352 VFCVectorTCMVFCid42 1;
BA_ "GenSigSendType" SG_ 1352 VFCVectorTCMVFCid43 1;
BA_ "GenSigSendType" SG_ 1352 VFCVectorTCMVFCid44 1;
BA_ "GenSigSendType" SG_ 1352 VFCVectorTCMVFCid45 1;
BA_ "GenSigSendType" SG_ 1352 VFCVectorTCMVFCid46 1;
BA_ "GenSigSendType" SG_ 1352 VFCVectorTCMVFCid47 1;
BA_ "GenSigSendType" SG_ 1352 VFCVectorTCMVFCid48 1;
BA_ "GenSigSendType" SG_ 1352 VFCVectorTCMVFCid49 1;
BA_ "GenSigSendType" SG_ 1352 VFCVectorTCMVFCid5 1;
BA_ "GenSigSendType" SG_ 1352 VFCVectorTCMVFCid50 1;
BA_ "GenSigSendType" SG_ 1352 VFCVectorTCMVFCid51 1;
BA_ "GenSigSendType" SG_ 1352 VFCVectorTCMVFCid52 1;
BA_ "GenSigSendType" SG_ 1352 VFCVectorTCMVFCid53 1;
BA_ "GenSigSendType" SG_ 1352 VFCVectorTCMVFCid54 1;
BA_ "GenSigSendType" SG_ 1352 VFCVectorTCMVFCid55 1;
BA_ "GenSigSendType" SG_ 1352 VFCVectorTCMVFCid56 1;
BA_ "GenSigSendType" SG_ 1352 VFCVectorTCMVFCid57 1;
BA_ "GenSigSendType" SG_ 1352 VFCVectorTCMVFCid58 1;
BA_ "GenSigSendType" SG_ 1352 VFCVectorTCMVFCid59 1;
BA_ "GenSigSendType" SG_ 1352 VFCVectorTCMVFCid6 1;
BA_ "GenSigSendType" SG_ 1352 VFCVectorTCMVFCid60 1;
BA_ "GenSigSendType" SG_ 1352 VFCVectorTCMVFCid61 1;
BA_ "GenSigSendType" SG_ 1352 VFCVectorTCMVFCid7 1;
BA_ "GenSigSendType" SG_ 1352 VFCVectorTCMVFCid8 1;
BA_ "GenSigSendType" SG_ 1352 VFCVectorTCMVFCid9 1;
// Frame: TcmToEtcXcpFr01
BA_ "GenMsgSendType" BO_ 1408 1;
BA_ "GenMsgDelayTime" BO_ 1408 5.000;
// Frame: TcmToEtcXcpFr02
BA_ "GenMsgSendType" BO_ 1413 1;
BA_ "GenMsgDelayTime" BO_ 1413 5.000;
// Frame: VddmBcmtoETCXCPFr01
BA_ "GenMsgSendType" BO_ 1422 1;
BA_ "GenMsgDelayTime" BO_ 1422 10.000;
// Frame: VddmChas1DevFr01
BA_ "GenMsgSendType" BO_ 1434 1;
BA_ "GenMsgDelayTime" BO_ 1434 95.000;
BA_ "GenSigSendType" SG_ 1434 VDDMdevelpsignalgroupresp1Functiondevpsignalgroup1 1;
BA_ "GenSigSendType" SG_ 1434 VDDMdevelpsignalgroupresp1Functiondevpsignalgroup2 1;
BA_ "GenSigSendType" SG_ 1434 VDDMdevelpsignalgroupresp1Functiondevpsignalgroup3 1;
BA_ "GenSigSendType" SG_ 1434 VDDMdevelpsignalgroupresp1Functiondevpsignalgroup4 1;
BA_ "GenSigSendType" SG_ 1434 VDDMdevelpsignalgroupresp1Functiondevpsignalgroup5 1;
BA_ "GenSigSendType" SG_ 1434 VDDMdevelpsignalgroupresp1Functiondevpsignalgroup6 1;
BA_ "GenSigSendType" SG_ 1434 VDDMdevelpsignalgroupresp1Functiondevpsignalgroup7 1;
BA_ "GenSigSendType" SG_ 1434 VDDMdevelpsignalgroupresp1Functiondevpsignalgroup8 1;
// Frame: VddmChas1DevFr02
BA_ "GenMsgSendType" BO_ 1435 1;
BA_ "GenMsgDelayTime" BO_ 1435 95.000;
BA_ "GenSigSendType" SG_ 1435 VDDMdevelpsignalgroupresp2Functiondevpsignalgroup1 1;
BA_ "GenSigSendType" SG_ 1435 VDDMdevelpsignalgroupresp2Functiondevpsignalgroup2 1;
BA_ "GenSigSendType" SG_ 1435 VDDMdevelpsignalgroupresp2Functiondevpsignalgroup3 1;
BA_ "GenSigSendType" SG_ 1435 VDDMdevelpsignalgroupresp2Functiondevpsignalgroup4 1;
BA_ "GenSigSendType" SG_ 1435 VDDMdevelpsignalgroupresp2Functiondevpsignalgroup5 1;
BA_ "GenSigSendType" SG_ 1435 VDDMdevelpsignalgroupresp2Functiondevpsignalgroup6 1;
BA_ "GenSigSendType" SG_ 1435 VDDMdevelpsignalgroupresp2Functiondevpsignalgroup7 1;
BA_ "GenSigSendType" SG_ 1435 VDDMdevelpsignalgroupresp2Functiondevpsignalgroup8 1;
// Frame: VddmChas1Fr01
BA_ "GenMsgSendType" BO_ 81 0;
BA_ "GenMsgCycleTime" BO_ 81 10.000;
BA_ "GenSigStartValue" SG_ 81 AsyDataWithCmpSafeALat1Qf 1;
BA_ "GenSigSendType" SG_ 81 AsyDataWithCmpSafeALat1Qf 0;
BA_ "GenSigSendType" SG_ 81 AsyDataWithCmpSafeALatWithCmp 0;
BA_ "GenSigStartValue" SG_ 81 AsyDataWithCmpSafeALgt1Qf 1;
BA_ "GenSigSendType" SG_ 81 AsyDataWithCmpSafeALgt1Qf 0;
BA_ "GenSigStartValue" SG_ 81 AsyDataWithCmpSafeChks 255;
BA_ "GenSigSendType" SG_ 81 AsyDataWithCmpSafeChks 0;
BA_ "GenSigFuncType" SG_ 81 AsyDataWithCmpSafeChks 15;
BA_ "GenSigDataID" SG_ 81 AsyDataWithCmpSafeChks "0x24";
BA_ "GenSigSendType" SG_ 81 AsyDataWithCmpSafeCntr 0;
BA_ "GenSigFuncType" SG_ 81 AsyDataWithCmpSafeCntr 16;
BA_ "GenSigSendType" SG_ 81 AsyDataWithCmpSafeGrdtOfALgt 0;
BA_ "GenSigStartValue" SG_ 81 AsyDataWithCmpSafeYawRateQf 1;
BA_ "GenSigSendType" SG_ 81 AsyDataWithCmpSafeYawRateQf 0;
BA_ "GenSigSendType" SG_ 81 AsyDataWithCmpSafeYawRateWithCmp 0;
// Frame: VddmChas1Fr03
BA_ "GenMsgSendType" BO_ 160 0;
BA_ "GenMsgCycleTime" BO_ 160 15.000;
BA_ "GenSigSendType" SG_ 160 ADataRawSafeALat 0;
BA_ "GenSigStartValue" SG_ 160 ADataRawSafeALat1Qf 1;
BA_ "GenSigSendType" SG_ 160 ADataRawSafeALat1Qf 0;
BA_ "GenSigSendType" SG_ 160 ADataRawSafeALgt 0;
BA_ "GenSigStartValue" SG_ 160 ADataRawSafeALgt1Qf 1;
BA_ "GenSigSendType" SG_ 160 ADataRawSafeALgt1Qf 0;
BA_ "GenSigStartValue" SG_ 160 ADataRawSafeAVert 1155.059;
BA_ "GenSigSendType" SG_ 160 ADataRawSafeAVert 0;
BA_ "GenSigStartValue" SG_ 160 ADataRawSafeAVertQf 1;
BA_ "GenSigSendType" SG_ 160 ADataRawSafeAVertQf 0;
BA_ "GenSigStartValue" SG_ 160 ADataRawSafeChks 255;
BA_ "GenSigSendType" SG_ 160 ADataRawSafeChks 0;
BA_ "GenSigFuncType" SG_ 160 ADataRawSafeChks 15;
BA_ "GenSigDataID" SG_ 160 ADataRawSafeChks "0x22";
BA_ "GenSigSendType" SG_ 160 ADataRawSafeCntr 0;
BA_ "GenSigFuncType" SG_ 160 ADataRawSafeCntr 16;
// Frame: VddmChas1Fr04
BA_ "GenMsgSendType" BO_ 400 0;
BA_ "GenMsgCycleTime" BO_ 400 20.000;
BA_ "GenSigSendType" SG_ 400 AbsCtrlActvChks 0;
BA_ "GenSigFuncType" SG_ 400 AbsCtrlActvChks 15;
BA_ "GenSigDataID" SG_ 400 AbsCtrlActvChks "0xD06";
BA_ "GenSigSendType" SG_ 400 AbsCtrlActvCntr 0;
BA_ "GenSigFuncType" SG_ 400 AbsCtrlActvCntr 16;
BA_ "GenSigSendType" SG_ 400 AbsCtrlActvCtrlSts1 0;
BA_ "GenSigStartValue" SG_ 400 AmbTRawAmbTVal 700;
BA_ "GenSigSendType" SG_ 400 AmbTRawAmbTVal 0;
BA_ "GenSigSendType" SG_ 400 AmbTRawQly 0;
BA_ "GenSigSendType" SG_ 400 LatCtrlReqSafeChks 0;
BA_ "GenSigFuncType" SG_ 400 LatCtrlReqSafeChks 15;
BA_ "GenSigDataID" SG_ 400 LatCtrlReqSafeChks "0x30";
BA_ "GenSigSendType" SG_ 400 LatCtrlReqSafeCntr 0;
BA_ "GenSigFuncType" SG_ 400 LatCtrlReqSafeCntr 16;
BA_ "GenSigSendType" SG_ 400 LatCtrlReqSafeLatCtrlModReq 0;
BA_ "GenSigSendType" SG_ 400 LatCtrlReqSafeSteerTqReq 0;
BA_ "GenSigSendType" SG_ 400 LatCtrlReqSafeSteerWhlHptcWarnReq 0;
// Frame: VddmChas1Fr05
BA_ "GenMsgSendType" BO_ 224 0;
BA_ "GenMsgCycleTime" BO_ 224 20.000;
BA_ "GenSigSendType" SG_ 224 CnvnReq 0;
BA_ "GenSigSendType" SG_ 224 DrvrCrsCtrlFctSeld 0;
BA_ "GenSigSendType" SG_ 224 EngRunngReqByParkAssi1 0;
BA_ "GenSigSendType" SG_ 224 EngRunngReqByParkAssiChks 0;
BA_ "GenSigFuncType" SG_ 224 EngRunngReqByParkAssiChks 15;
BA_ "GenSigDataID" SG_ 224 EngRunngReqByParkAssiChks "0x0F";
BA_ "GenSigSendType" SG_ 224 EngRunngReqByParkAssiCntr 0;
BA_ "GenSigFuncType" SG_ 224 EngRunngReqByParkAssiCntr 16;
BA_ "GenSigSendType" SG_ 224 VehSpdLgtA 0;
BA_ "GenSigSendType" SG_ 224 VehSpdLgtChks 0;
BA_ "GenSigFuncType" SG_ 224 VehSpdLgtChks 15;
BA_ "GenSigDataID" SG_ 224 VehSpdLgtChks "0x37";
BA_ "GenSigSendType" SG_ 224 VehSpdLgtCntr 0;
BA_ "GenSigFuncType" SG_ 224 VehSpdLgtCntr 16;
BA_ "GenSigStartValue" SG_ 224 VehSpdLgtQf 1;
BA_ "GenSigSendType" SG_ 224 VehSpdLgtQf 0;
// Frame: VddmChas1Fr08
BA_ "GenMsgSendType" BO_ 928 0;
BA_ "GenMsgCycleTime" BO_ 928 320.000;
BA_ "GenSigStartValue" SG_ 928 AmbTIndcdWithUnitAmbTIndcd 1000;
BA_ "GenSigSendType" SG_ 928 AmbTIndcdWithUnitAmbTIndcd 0;
BA_ "GenSigSendType" SG_ 928 AmbTIndcdWithUnitAmbTIndcdUnit 0;
BA_ "GenSigSendType" SG_ 928 AmbTIndcdWithUnitQF 0;
BA_ "GenSigStartValue" SG_ 928 CmptmtTReCmptmtTFrnt 600;
BA_ "GenSigSendType" SG_ 928 CmptmtTReCmptmtTFrnt 0;
BA_ "GenSigStartValue" SG_ 928 CmptmtTReCmptmtTFrntQf 1;
BA_ "GenSigSendType" SG_ 928 CmptmtTReCmptmtTFrntQf 0;
BA_ "GenSigSendType" SG_ 928 CmptmtTReFanForCmptmtTRunng 0;
BA_ "GenSigSendType" SG_ 928 ReHvacBlowerSts 0;
// Frame: VddmChas1Fr10
BA_ "GenMsgSendType" BO_ 433 0;
BA_ "GenMsgCycleTime" BO_ 433 30.000;
BA_ "GenSigSendType" SG_ 433 BrkPedlPsdBrkPedlNotPsdSafe 0;
BA_ "GenSigSendType" SG_ 433 BrkPedlPsdBrkPedlPsd 0;
BA_ "GenSigSendType" SG_ 433 BrkPedlPsdChks 0;
BA_ "GenSigFuncType" SG_ 433 BrkPedlPsdChks 15;
BA_ "GenSigDataID" SG_ 433 BrkPedlPsdChks "0x38";
BA_ "GenSigSendType" SG_ 433 BrkPedlPsdCntr 0;
BA_ "GenSigFuncType" SG_ 433 BrkPedlPsdCntr 16;
BA_ "GenSigSendType" SG_ 433 BrkPedlPsdQf 0;
BA_ "GenSigSendType" SG_ 433 WhlSpdCircumlFrntChks 0;
BA_ "GenSigFuncType" SG_ 433 WhlSpdCircumlFrntChks 15;
BA_ "GenSigDataID" SG_ 433 WhlSpdCircumlFrntChks "0x6F";
BA_ "GenSigSendType" SG_ 433 WhlSpdCircumlFrntCntr 0;
BA_ "GenSigFuncType" SG_ 433 WhlSpdCircumlFrntCntr 16;
BA_ "GenSigSendType" SG_ 433 WhlSpdCircumlFrntLe 0;
BA_ "GenSigStartValue" SG_ 433 WhlSpdCircumlFrntLeQf 1;
BA_ "GenSigSendType" SG_ 433 WhlSpdCircumlFrntLeQf 0;
BA_ "GenSigStartValue" SG_ 433 WhlSpdCircumlFrntRiQf 1;
BA_ "GenSigSendType" SG_ 433 WhlSpdCircumlFrntRiQf 0;
BA_ "GenSigSendType" SG_ 433 WhlSpdCircumlFrntWhlSpdCircumlFrntRi 0;
// Frame: VddmChas1Fr12
BA_ "GenMsgSendType" BO_ 1087 0;
BA_ "GenMsgCycleTime" BO_ 1087 350.000;
BA_ "GenSigSendType" SG_ 1087 ReEvapVlvSts 0;
BA_ "GenSigSendType" SG_ 1087 ResrvdSigForECM1 0;
BA_ "GenSigSendType" SG_ 1087 ResrvdSigForECM2 0;
BA_ "GenSigSendType" SG_ 1087 ResrvdSigForECM3 0;
BA_ "GenSigSendType" SG_ 1087 ResrvdSigForECM4 0;
// Frame: VddmChas1Fr14
BA_ "GenMsgSendType" BO_ 432 0;
BA_ "GenMsgCycleTime" BO_ 432 30.000;
BA_ "GenSigStartValue" SG_ 432 AgDataRawSafeChks 255;
BA_ "GenSigSendType" SG_ 432 AgDataRawSafeChks 0;
BA_ "GenSigFuncType" SG_ 432 AgDataRawSafeChks 15;
BA_ "GenSigDataID" SG_ 432 AgDataRawSafeChks "0x23";
BA_ "GenSigSendType" SG_ 432 AgDataRawSafeCntr 0;
BA_ "GenSigFuncType" SG_ 432 AgDataRawSafeCntr 16;
BA_ "GenSigSendType" SG_ 432 AgDataRawSafeRollRate 0;
BA_ "GenSigStartValue" SG_ 432 AgDataRawSafeRollRateQf 1;
BA_ "GenSigSendType" SG_ 432 AgDataRawSafeRollRateQf 0;
BA_ "GenSigSendType" SG_ 432 AgDataRawSafeYawRate 0;
BA_ "GenSigStartValue" SG_ 432 AgDataRawSafeYawRateQf 1;
BA_ "GenSigSendType" SG_ 432 AgDataRawSafeYawRateQf 0;
// Frame: VddmChas1Fr16
BA_ "GenMsgSendType" BO_ 367 0;
BA_ "GenMsgCycleTime" BO_ 367 20.000;
BA_ "GenSigSendType" SG_ 367 TrsmLockMgrReqCmd 0;
BA_ "GenSigSendType" SG_ 367 TrsmLockMgrReqData0 0;
BA_ "GenSigSendType" SG_ 367 TrsmLockMgrReqData1 0;
BA_ "GenSigSendType" SG_ 367 TrsmLockMgrReqData2 0;
BA_ "GenSigSendType" SG_ 367 TrsmLockMgrReqData3 0;
BA_ "GenSigSendType" SG_ 367 TrsmLockMgrReqData4 0;
BA_ "GenSigSendType" SG_ 367 TrsmLockMgrReqData5 0;
BA_ "GenSigSendType" SG_ 367 TrsmLockMgrReqData6 0;
// Frame: VddmChas1Fr19
BA_ "GenMsgSendType" BO_ 736 0;
BA_ "GenMsgCycleTime" BO_ 736 70.000;
BA_ "GenSigSendType" SG_ 736 VehModMngtGlbSafe1CarModSts1 0;
BA_ "GenSigSendType" SG_ 736 VehModMngtGlbSafe1CarModSubtypWdCarModSubtyp 0;
BA_ "GenSigSendType" SG_ 736 VehModMngtGlbSafe1Chks 0;
BA_ "GenSigFuncType" SG_ 736 VehModMngtGlbSafe1Chks 15;
BA_ "GenSigDataID" SG_ 736 VehModMngtGlbSafe1Chks "0x74";
BA_ "GenSigSendType" SG_ 736 VehModMngtGlbSafe1Cntr 0;
BA_ "GenSigFuncType" SG_ 736 VehModMngtGlbSafe1Cntr 16;
BA_ "GenSigSendType" SG_ 736 VehModMngtGlbSafe1EgyLvlElecMai 0;
BA_ "GenSigSendType" SG_ 736 VehModMngtGlbSafe1EgyLvlElecSubtyp 0;
BA_ "GenSigSendType" SG_ 736 VehModMngtGlbSafe1FltEgyCnsWdSts 0;
BA_ "GenSigSendType" SG_ 736 VehModMngtGlbSafe1PwrLvlElecMai 0;
BA_ "GenSigSendType" SG_ 736 VehModMngtGlbSafe1PwrLvlElecSubtyp 0;
BA_ "GenSigStartValue" SG_ 736 VehModMngtGlbSafe1UsgModSts 1;
BA_ "GenSigSendType" SG_ 736 VehModMngtGlbSafe1UsgModSts 0;
// Frame: VddmChas1Fr21
BA_ "GenMsgSendType" BO_ 38 1;
BA_ "GenMsgDelayTime" BO_ 38 300.000;
BA_ "GenSigSendType" SG_ 38 ChrgSoftSwCtrlSt 1;
BA_ "GenSigStartValue" SG_ 38 IntelliClimaHvacEvaprTSp 50;
BA_ "GenSigSendType" SG_ 38 IntelliClimaHvacEvaprTSp 1;
BA_ "GenSigSendType" SG_ 38 IntelliClimaHvBattInCooltFlowReq 1;
BA_ "GenSigStartValue" SG_ 38 IntelliClimaHvBattInCooltTReq 50;
BA_ "GenSigSendType" SG_ 38 IntelliClimaHvBattInCooltTReq 1;
BA_ "GenSigStartValue" SG_ 38 IntelliClimaHvCooltHeatrTReq 40;
BA_ "GenSigSendType" SG_ 38 IntelliClimaHvCooltHeatrTReq 1;
BA_ "GenSigSendType" SG_ 38 IntelliClimaReq 1;
BA_ "GenSigStartValue" SG_ 38 PrpsnHvBattUsgOfChrgTarSOC 1000;
BA_ "GenSigSendType" SG_ 38 PrpsnHvBattUsgOfChrgTarSOC 1;
BA_ "GenSigSendType" SG_ 38 VFCInfoEna 1;
// Frame: VddmChas1Fr22
BA_ "GenMsgSendType" BO_ 1123 0;
BA_ "GenMsgCycleTime" BO_ 1123 170.000;
BA_ "GenSigSendType" SG_ 1123 EvaprTReEvaprTFrnt 0;
BA_ "GenSigStartValue" SG_ 1123 EvaprTReEvaprTQf 1;
BA_ "GenSigSendType" SG_ 1123 EvaprTReEvaprTQf 0;
BA_ "GenSigStartValue" SG_ 1123 HvacEvaprTSpRe 50;
BA_ "GenSigSendType" SG_ 1123 HvacEvaprTSpRe 0;
BA_ "GenSigSendType" SG_ 1123 SteerSetgPen 0;
BA_ "GenSigSendType" SG_ 1123 SteerSetgSteerAsscLvl 0;
BA_ "GenSigSendType" SG_ 1123 SteerSetgSteerMod 0;
// Frame: VddmChas1Fr23
BA_ "GenMsgSendType" BO_ 784 0;
BA_ "GenMsgCycleTime" BO_ 784 170.000;
BA_ "GenSigStartValue" SG_ 784 CmptmtTFrntCmptmtTFrnt 600;
BA_ "GenSigSendType" SG_ 784 CmptmtTFrntCmptmtTFrnt 0;
BA_ "GenSigSendType" SG_ 784 CmptmtTFrntFanForCmptmtTRunng 0;
BA_ "GenSigStartValue" SG_ 784 CmptmtTFrntQf 1;
BA_ "GenSigSendType" SG_ 784 CmptmtTFrntQf 0;
// Frame: VddmChas1Fr24
BA_ "GenMsgSendType" BO_ 137 0;
BA_ "GenMsgCycleTime" BO_ 137 20.000;
BA_ "GenSigStartValue" SG_ 137 HsaSt 1;
BA_ "GenSigSendType" SG_ 137 HsaSt 0;
BA_ "GenSigSendType" SG_ 137 LVPwrSplyErrSts 0;
BA_ "GenSigSendType" SG_ 137 WhlFastSpdSafeA 0;
BA_ "GenSigSendType" SG_ 137 WhlFastSpdSafeChks 0;
BA_ "GenSigFuncType" SG_ 137 WhlFastSpdSafeChks 15;
BA_ "GenSigDataID" SG_ 137 WhlFastSpdSafeChks "0x1972";
BA_ "GenSigSendType" SG_ 137 WhlFastSpdSafeCntr 0;
BA_ "GenSigFuncType" SG_ 137 WhlFastSpdSafeCntr 16;
BA_ "GenSigStartValue" SG_ 137 WhlFastSpdSafeQF 1;
BA_ "GenSigSendType" SG_ 137 WhlFastSpdSafeQF 0;
// Frame: VddmChas1Fr30
BA_ "GenMsgSendType" BO_ 592 1;
BA_ "GenMsgDelayTime" BO_ 592 120.000;
BA_ "GenSigSendType" SG_ 592 VehCfgPrmBlkIDBytePosn1 1;
BA_ "GenSigSendType" SG_ 592 VehCfgPrmCCPBytePosn2 1;
BA_ "GenSigSendType" SG_ 592 VehCfgPrmCCPBytePosn3 1;
BA_ "GenSigSendType" SG_ 592 VehCfgPrmCCPBytePosn4 1;
BA_ "GenSigSendType" SG_ 592 VehCfgPrmCCPBytePosn5 1;
BA_ "GenSigSendType" SG_ 592 VehCfgPrmCCPBytePosn6 1;
BA_ "GenSigSendType" SG_ 592 VehCfgPrmCCPBytePosn7 1;
BA_ "GenSigSendType" SG_ 592 VehCfgPrmCCPBytePosn8 1;
// Frame: VddmChas1Fr33
BA_ "GenMsgSendType" BO_ 1015 1;
BA_ "GenMsgDelayTime" BO_ 1015 120.000;
BA_ "GenSigSendType" SG_ 1015 VehCfgPrmExtBlkIDBytePosn1 1;
BA_ "GenSigSendType" SG_ 1015 VehCfgPrmExtCCPBytePosn2 1;
BA_ "GenSigSendType" SG_ 1015 VehCfgPrmExtCCPBytePosn3 1;
BA_ "GenSigSendType" SG_ 1015 VehCfgPrmExtCCPBytePosn4 1;
BA_ "GenSigSendType" SG_ 1015 VehCfgPrmExtCCPBytePosn5 1;
BA_ "GenSigSendType" SG_ 1015 VehCfgPrmExtCCPBytePosn6 1;
BA_ "GenSigSendType" SG_ 1015 VehCfgPrmExtCCPBytePosn7 1;
BA_ "GenSigSendType" SG_ 1015 VehCfgPrmExtCCPBytePosn8 1;
// Frame: VddmChas1Fr34
BA_ "GenMsgSendType" BO_ 775 1;
BA_ "GenMsgDelayTime" BO_ 775 150.000;
BA_ "GenSigSendType" SG_ 775 BookChrgnActvdReq 1;
BA_ "GenSigSendType" SG_ 775 BookChrgSetReq 1;
BA_ "GenSigSendType" SG_ 775 BookStopTiAchieved 1;
BA_ "GenSigSendType" SG_ 775 LocalBookChrgnTarVal 1;
BA_ "GenSigSendType" SG_ 775 RemBookChrgnTarVal 1;
// Frame: VddmChas1Fr37
BA_ "GenMsgSendType" BO_ 823 0;
BA_ "GenMsgCycleTime" BO_ 823 165.000;
BA_ "GenSigSendType" SG_ 823 CarTiIntForClima 0;
BA_ "GenSigSendType" SG_ 823 ClimaCmptSts 0;
BA_ "GenSigSendType" SG_ 823 ClimaDefrstSts 0;
BA_ "GenSigSendType" SG_ 823 FrntHvacBlowerSts 0;
BA_ "GenSigStartValue" SG_ 823 HeatrAirTReq 120;
BA_ "GenSigSendType" SG_ 823 HeatrAirTReq 0;
// Frame: VddmChas1Fr41
BA_ "GenMsgSendType" BO_ 686 0;
BA_ "GenMsgCycleTime" BO_ 686 120.000;
BA_ "GenSigSendType" SG_ 686 AbsSts 0;
BA_ "GenSigSendType" SG_ 686 DrvModReq 0;
BA_ "GenSigSendType" SG_ 686 HvacHexAirTHvacAirTForHeatrFrnt 0;
BA_ "GenSigStartValue" SG_ 686 HvacHexAirTHvacAirTForHeatrFrntQf 1;
BA_ "GenSigSendType" SG_ 686 HvacHexAirTHvacAirTForHeatrFrntQf 0;
BA_ "GenSigSendType" SG_ 686 ULoWarnChks 0;
BA_ "GenSigFuncType" SG_ 686 ULoWarnChks 15;
BA_ "GenSigDataID" SG_ 686 ULoWarnChks "0x43";
BA_ "GenSigSendType" SG_ 686 ULoWarnCntr 0;
BA_ "GenSigFuncType" SG_ 686 ULoWarnCntr 16;
BA_ "GenSigSendType" SG_ 686 ULoWarnULoWarn 0;
// Frame: VddmChas1Fr42
BA_ "GenMsgSendType" BO_ 1243 0;
BA_ "GenMsgCycleTime" BO_ 1243 170.000;
BA_ "GenSigSendType" SG_ 1243 HvacAirTForRowFirstAtFlrLeEvaprTFrnt 0;
BA_ "GenSigStartValue" SG_ 1243 HvacAirTForRowFirstAtFlrLeEvaprTQf 1;
BA_ "GenSigSendType" SG_ 1243 HvacAirTForRowFirstAtFlrLeEvaprTQf 0;
BA_ "GenSigSendType" SG_ 1243 HvacAirTForRowFirstAtFlrRiEvaprTFrnt 0;
BA_ "GenSigStartValue" SG_ 1243 HvacAirTForRowFirstAtFlrRiEvaprTQf 1;
BA_ "GenSigSendType" SG_ 1243 HvacAirTForRowFirstAtFlrRiEvaprTQf 0;
BA_ "GenSigSendType" SG_ 1243 HvacAirTForRowFirstAtVentLeEvaprTFrnt 0;
BA_ "GenSigStartValue" SG_ 1243 HvacAirTForRowFirstAtVentLeEvaprTQf 1;
BA_ "GenSigSendType" SG_ 1243 HvacAirTForRowFirstAtVentLeEvaprTQf 0;
BA_ "GenSigSendType" SG_ 1243 HvacAirTForRowFirstAtVentRiEvaprTFrnt 0;
BA_ "GenSigStartValue" SG_ 1243 HvacAirTForRowFirstAtVentRiEvaprTQf 1;
BA_ "GenSigSendType" SG_ 1243 HvacAirTForRowFirstAtVentRiEvaprTQf 0;
// Frame: VddmChas1Fr43
BA_ "GenMsgSendType" BO_ 1255 0;
BA_ "GenMsgCycleTime" BO_ 1255 170.000;
BA_ "GenSigSendType" SG_ 1255 HvacAirTForRowSecAtFlrLeEvaprTFrnt 0;
BA_ "GenSigStartValue" SG_ 1255 HvacAirTForRowSecAtFlrLeEvaprTQf 1;
BA_ "GenSigSendType" SG_ 1255 HvacAirTForRowSecAtFlrLeEvaprTQf 0;
BA_ "GenSigSendType" SG_ 1255 HvacAirTForRowSecAtFlrRiEvaprTFrnt 0;
BA_ "GenSigStartValue" SG_ 1255 HvacAirTForRowSecAtFlrRiEvaprTQf 1;
BA_ "GenSigSendType" SG_ 1255 HvacAirTForRowSecAtFlrRiEvaprTQf 0;
BA_ "GenSigSendType" SG_ 1255 HvacAirTForRowSecAtVentLeEvaprTFrnt 0;
BA_ "GenSigStartValue" SG_ 1255 HvacAirTForRowSecAtVentLeEvaprTQf 1;
BA_ "GenSigSendType" SG_ 1255 HvacAirTForRowSecAtVentLeEvaprTQf 0;
BA_ "GenSigSendType" SG_ 1255 HvacAirTForRowSecAtVentRiEvaprTFrnt 0;
BA_ "GenSigStartValue" SG_ 1255 HvacAirTForRowSecAtVentRiEvaprTQf 1;
BA_ "GenSigSendType" SG_ 1255 HvacAirTForRowSecAtVentRiEvaprTQf 0;
// Frame: VddmChas1Fr44
BA_ "GenMsgSendType" BO_ 1267 0;
BA_ "GenMsgCycleTime" BO_ 1267 170.000;
BA_ "GenSigSendType" SG_ 1267 EscStChks 0;
BA_ "GenSigFuncType" SG_ 1267 EscStChks 15;
BA_ "GenSigDataID" SG_ 1267 EscStChks "0x7F";
BA_ "GenSigSendType" SG_ 1267 EscStCntr 0;
BA_ "GenSigFuncType" SG_ 1267 EscStCntr 16;
BA_ "GenSigStartValue" SG_ 1267 EscStEscSt 1;
BA_ "GenSigSendType" SG_ 1267 EscStEscSt 0;
BA_ "GenSigSendType" SG_ 1267 HvacCondsorTEvaprTFrnt 0;
BA_ "GenSigStartValue" SG_ 1267 HvacCondsorTEvaprTQf 1;
BA_ "GenSigSendType" SG_ 1267 HvacCondsorTEvaprTQf 0;
BA_ "GenSigSendType" SG_ 1267 HvacCondsorTspEvaprTFrnt 0;
BA_ "GenSigStartValue" SG_ 1267 HvacCondsorTspEvaprTQf 1;
BA_ "GenSigSendType" SG_ 1267 HvacCondsorTspEvaprTQf 0;
BA_ "GenSigSendType" SG_ 1267 HvacOsaAndRecActrQfForHp 0;
// Frame: VddmChas1Fr46
BA_ "GenMsgSendType" BO_ 1099 0;
BA_ "GenMsgCycleTime" BO_ 1099 170.000;
BA_ "GenSigStartValue" SG_ 1099 AmbTEstimdAmbTEstimd 700;
BA_ "GenSigSendType" SG_ 1099 AmbTEstimdAmbTEstimd 0;
BA_ "GenSigSendType" SG_ 1099 AmbTEstimdQf 0;
BA_ "GenSigSendType" SG_ 1099 BrkTracCtrlActv 0;
BA_ "GenSigSendType" SG_ 1099 HvacHeatgReq 0;
BA_ "GenSigSendType" SG_ 1099 WhlRotToothCntrChks 0;
BA_ "GenSigFuncType" SG_ 1099 WhlRotToothCntrChks 15;
BA_ "GenSigDataID" SG_ 1099 WhlRotToothCntrChks "0x19C8";
BA_ "GenSigSendType" SG_ 1099 WhlRotToothCntrCntr 0;
BA_ "GenSigFuncType" SG_ 1099 WhlRotToothCntrCntr 16;
BA_ "GenSigSendType" SG_ 1099 WhlRotToothCntrFrntLe 0;
BA_ "GenSigSendType" SG_ 1099 WhlRotToothCntrFrntRi 0;
BA_ "GenSigSendType" SG_ 1099 WhlRotToothCntrReLe 0;
BA_ "GenSigSendType" SG_ 1099 WhlRotToothCntrReRi 0;
// Frame: VddmChas1Fr47
BA_ "GenMsgSendType" BO_ 26 0;
BA_ "GenMsgCycleTime" BO_ 26 100.000;
BA_ "GenSigSendType" SG_ 26 AgDataCmpQualityPitchRateCmpQuality 0;
BA_ "GenSigSendType" SG_ 26 AgDataCmpQualityRollRateCmpQuality 0;
BA_ "GenSigSendType" SG_ 26 AgDataCmpQualityYawRateCmpQuality 0;
BA_ "GenSigSendType" SG_ 26 BattURaw 0;
BA_ "GenSigSendType" SG_ 26 EgyRgnLvlSet 0;
// Frame: VddmChas1Fr48
BA_ "GenMsgSendType" BO_ 1159 0;
BA_ "GenMsgCycleTime" BO_ 1159 700.000;
BA_ "GenSigSendType" SG_ 1159 VehMtnStChks 0;
BA_ "GenSigFuncType" SG_ 1159 VehMtnStChks 15;
BA_ "GenSigDataID" SG_ 1159 VehMtnStChks "0x36";
BA_ "GenSigSendType" SG_ 1159 VehMtnStCntr 0;
BA_ "GenSigFuncType" SG_ 1159 VehMtnStCntr 16;
BA_ "GenSigSendType" SG_ 1159 VehMtnStVehMtnSt 0;
// Frame: VddmChas1Fr49
BA_ "GenMsgSendType" BO_ 864 0;
BA_ "GenMsgCycleTime" BO_ 864 80.000;
BA_ "GenSigSendType" SG_ 864 CarTiGlb 0;
BA_ "GenSigSendType" SG_ 864 HvacHeatrInletTempReqEvaprTFrnt 0;
BA_ "GenSigSendType" SG_ 864 HvacHeatrInletTempReqEvaprTQf 0;
BA_ "GenSigSendType" SG_ 864 ProfPenSts1 0;
BA_ "GenSigSendType" SG_ 864 SaveSetgToMemPrmnt 0;
// Frame: VddmChas1Fr50
BA_ "GenMsgSendType" BO_ 896 0;
BA_ "GenMsgCycleTime" BO_ 896 700.000;
BA_ "GenSigSendType" SG_ 896 VehBattUSysU 0;
BA_ "GenSigStartValue" SG_ 896 VehBattUSysUQf 1;
BA_ "GenSigSendType" SG_ 896 VehBattUSysUQf 0;
// Frame: VddmChas1Fr51
BA_ "GenMsgSendType" BO_ 513 0;
BA_ "GenMsgCycleTime" BO_ 513 80.000;
BA_ "GenSigSendType" SG_ 513 ImobEngMgrReq3ImobEngDataMgrReq0 0;
BA_ "GenSigSendType" SG_ 513 ImobEngMgrReq3ImobEngDataMgrReq1 0;
BA_ "GenSigSendType" SG_ 513 ImobEngMgrReq3ImobEngDataMgrReq2 0;
BA_ "GenSigSendType" SG_ 513 ImobEngMgrReq3ImobEngDataMgrReq3 0;
BA_ "GenSigSendType" SG_ 513 ImobEngMgrReq3ImobEngDataMgrReq4 0;
BA_ "GenSigSendType" SG_ 513 ImobEngMgrReq3ImobEngDataMgrReq5 0;
BA_ "GenSigSendType" SG_ 513 ImobEngMgrReq3ImobEngDataMgrReq6 0;
BA_ "GenSigSendType" SG_ 513 ImobEngMgrReq3ImobEngMgrCmdTar1 0;
// Frame: VddmChas1Fr52
BA_ "GenMsgSendType" BO_ 17 0;
BA_ "GenMsgCycleTime" BO_ 17 10.000;
BA_ "GenSigSendType" SG_ 17 GearPrkgAssiReqGroupChks 0;
BA_ "GenSigFuncType" SG_ 17 GearPrkgAssiReqGroupChks 15;
BA_ "GenSigDataID" SG_ 17 GearPrkgAssiReqGroupChks "0x02";
BA_ "GenSigSendType" SG_ 17 GearPrkgAssiReqGroupCntr 0;
BA_ "GenSigFuncType" SG_ 17 GearPrkgAssiReqGroupCntr 16;
BA_ "GenSigSendType" SG_ 17 GearPrkgAssiReqGroupGearPrkgAssiReq1 0;
BA_ "GenSigSendType" SG_ 17 LgtCtrlModReqSafeChks 0;
BA_ "GenSigFuncType" SG_ 17 LgtCtrlModReqSafeChks 15;
BA_ "GenSigDataID" SG_ 17 LgtCtrlModReqSafeChks "0x422";
BA_ "GenSigSendType" SG_ 17 LgtCtrlModReqSafeCntr 0;
BA_ "GenSigFuncType" SG_ 17 LgtCtrlModReqSafeCntr 16;
BA_ "GenSigSendType" SG_ 17 LgtCtrlModReqSafeLgtCtrlModReqSafe 0;
BA_ "GenSigSendType" SG_ 17 LgtCtrlModReqSafeLgtFctFailr 0;
BA_ "GenSigSendType" SG_ 17 MvBattRlyStsChks 0;
BA_ "GenSigFuncType" SG_ 17 MvBattRlyStsChks 15;
BA_ "GenSigDataID" SG_ 17 MvBattRlyStsChks "0x412";
BA_ "GenSigSendType" SG_ 17 MvBattRlyStsCntr 0;
BA_ "GenSigFuncType" SG_ 17 MvBattRlyStsCntr 16;
BA_ "GenSigSendType" SG_ 17 MvBattRlyStsMvBattRlySts 0;
BA_ "GenSigSendType" SG_ 17 PrpsnHvBattUsgModReq 0;
// Frame: VddmChas1Fr53
BA_ "GenMsgSendType" BO_ 496 0;
BA_ "GenMsgCycleTime" BO_ 496 30.000;
BA_ "GenSigSendType" SG_ 496 BkpOfDstTrvld 0;
BA_ "GenSigSendType" SG_ 496 StandStillMgrStsForHld1 0;
BA_ "GenSigSendType" SG_ 496 StandStillMgrStsForHldChks 0;
BA_ "GenSigFuncType" SG_ 496 StandStillMgrStsForHldChks 15;
BA_ "GenSigDataID" SG_ 496 StandStillMgrStsForHldChks "0x448";
BA_ "GenSigSendType" SG_ 496 StandStillMgrStsForHldCntr 0;
BA_ "GenSigFuncType" SG_ 496 StandStillMgrStsForHldCntr 16;
// Frame: VddmChas1Fr54
BA_ "GenMsgSendType" BO_ 580 0;
BA_ "GenMsgCycleTime" BO_ 580 200.000;
BA_ "GenSigSendType" SG_ 580 IDcDcActLoSideChks 0;
BA_ "GenSigFuncType" SG_ 580 IDcDcActLoSideChks 15;
BA_ "GenSigDataID" SG_ 580 IDcDcActLoSideChks "0x14";
BA_ "GenSigSendType" SG_ 580 IDcDcActLoSideCntr 0;
BA_ "GenSigFuncType" SG_ 580 IDcDcActLoSideCntr 16;
BA_ "GenSigSendType" SG_ 580 IDcDcActLoSideIDcDcActLoSide 0;
BA_ "GenSigSendType" SG_ 580 MvDcDcActLoSideChks 0;
BA_ "GenSigFuncType" SG_ 580 MvDcDcActLoSideChks 15;
BA_ "GenSigDataID" SG_ 580 MvDcDcActLoSideChks "0x04";
BA_ "GenSigSendType" SG_ 580 MvDcDcActLoSideCntr 0;
BA_ "GenSigFuncType" SG_ 580 MvDcDcActLoSideCntr 16;
BA_ "GenSigStartValue" SG_ 580 MvDcDcActLoSideI 4096;
BA_ "GenSigSendType" SG_ 580 MvDcDcActLoSideI 0;
BA_ "GenSigSendType" SG_ 580 MvDcDcActLoSideU 0;
// Frame: VddmChas1Fr55
BA_ "GenMsgSendType" BO_ 439 0;
BA_ "GenMsgCycleTime" BO_ 439 30.000;
BA_ "GenSigSendType" SG_ 439 WhlSpdCircumlReChks 0;
BA_ "GenSigFuncType" SG_ 439 WhlSpdCircumlReChks 15;
BA_ "GenSigDataID" SG_ 439 WhlSpdCircumlReChks "0x7C";
BA_ "GenSigSendType" SG_ 439 WhlSpdCircumlReCntr 0;
BA_ "GenSigFuncType" SG_ 439 WhlSpdCircumlReCntr 16;
BA_ "GenSigSendType" SG_ 439 WhlSpdCircumlReLe 0;
BA_ "GenSigStartValue" SG_ 439 WhlSpdCircumlReLeQf 1;
BA_ "GenSigSendType" SG_ 439 WhlSpdCircumlReLeQf 0;
BA_ "GenSigSendType" SG_ 439 WhlSpdCircumlReRi 0;
BA_ "GenSigStartValue" SG_ 439 WhlSpdCircumlReRiQf 1;
BA_ "GenSigSendType" SG_ 439 WhlSpdCircumlReRiQf 0;
// Frame: VddmChas1Fr56
BA_ "GenMsgSendType" BO_ 52 5;
BA_ "GenMsgCycleTime" BO_ 52 200.000;
BA_ "GenMsgDelayTime" BO_ 52 20.000;
BA_ "GenSigStartValue" SG_ 52 CrashStsSafeChks 255;
BA_ "GenSigSendType" SG_ 52 CrashStsSafeChks 1;
BA_ "GenSigFuncType" SG_ 52 CrashStsSafeChks 15;
BA_ "GenSigDataID" SG_ 52 CrashStsSafeChks "0x40B";
BA_ "GenSigSendType" SG_ 52 CrashStsSafeCntr 1;
BA_ "GenSigFuncType" SG_ 52 CrashStsSafeCntr 16;
BA_ "GenSigSendType" SG_ 52 CrashStsSafeSts 1;
// Frame: VddmChas1NMFr
BA_ "GenMsgSendType" BO_ 1313 1;
BA_ "GenMsgDelayTime" BO_ 1313 20.000;
BA_ "GenMsgILSupport" BO_ 1313 0;
BA_ "NmAsrMessage" BO_ 1313 1;
// Frame: VddmToAllFuncChas1DiagReqFrame
BA_ "GenMsgSendType" BO_ 2047 1;
BA_ "GenMsgDelayTime" BO_ 2047 5.000;
// Frame: VddmToPscm100FITbChas1DiagReqFrame
BA_ "GenMsgSendType" BO_ 1908 1;
BA_ "GenMsgDelayTime" BO_ 1908 5.000;
// Frame: VddmToPscmChas1DiagReqFrame
BA_ "GenMsgSendType" BO_ 1904 1;
BA_ "GenMsgDelayTime" BO_ 1904 5.000;
// Frame: VddmToRasmChas1DiagReqFrame
BA_ "GenMsgSendType" BO_ 1905 1;
BA_ "GenMsgDelayTime" BO_ 1905 5.000;
// Frame: VddmToRbcmChas1DiagReqFrame
BA_ "GenMsgSendType" BO_ 1909 1;
BA_ "GenMsgDelayTime" BO_ 1909 5.000;
// Frame: VddmToSasChas1DiagReqFrame
BA_ "GenMsgSendType" BO_ 1906 1;
BA_ "GenMsgDelayTime" BO_ 1906 5.000;
VAL_ 293 TrsmCluOpen1 0 "TrsmCluOpen_NotOpen" 1 "TrsmCluOpen_Open";
VAL_ 293 TrsmCluOpen2 0 "TrsmCluOpen_NotOpen" 1 "TrsmCluOpen_Open";
VAL_ 293 TrsmEcuTLvl 0 "TrsmEcuTLvl_NormOper" 1 "TrsmEcuTLvl_TLvl1" 2 "TrsmEcuTLvl_TLvl2" 3 "TrsmEcuTLvl_TLvl3";
VAL_ 293 TrsmGearSafeAct1 0 "TrsmGear_Neut" 1 "TrsmGear_Gear1" 2 "TrsmGear_Gear2" 3 "TrsmGear_Gear3" 4 "TrsmGear_Gear4" 5 "TrsmGear_Gear5" 6 "TrsmGear_Gear6" 7 "TrsmGear_Gear7" 8 "TrsmGear_Gear8" 9 "TrsmGear_Gear9" 10 "TrsmGear_Gear10" 11 "TrsmGear_Gear11" 12 "TrsmGear_Gear12" 13 "TrsmGear_Gear13" 14 "TrsmGear_Rvs" 15 "TrsmGear_Park";
VAL_ 293 TrsmGearSafeAct2 0 "TrsmGear_Neut" 1 "TrsmGear_Gear1" 2 "TrsmGear_Gear2" 3 "TrsmGear_Gear3" 4 "TrsmGear_Gear4" 5 "TrsmGear_Gear5" 6 "TrsmGear_Gear6" 7 "TrsmGear_Gear7" 8 "TrsmGear_Gear8" 9 "TrsmGear_Gear9" 10 "TrsmGear_Gear10" 11 "TrsmGear_Gear11" 12 "TrsmGear_Gear12" 13 "TrsmGear_Gear13" 14 "TrsmGear_Rvs" 15 "TrsmGear_Park";
VAL_ 293 TrsmGearSafeSts1 0 "TrsmGearSafeSts_StsNotOk" 1 "TrsmGearSafeSts_StsOk";
VAL_ 293 TrsmGearSafeSts2 0 "TrsmGearSafeSts_StsNotOk" 1 "TrsmGearSafeSts_StsOk";
VAL_ 293 TrsmSailStsTrsmSailAllwd 0 "OnOff1_Off" 1 "OnOff1_On";
VAL_ 293 TrsmSailStsTrsmShiftMapForIsg 0 "TrsmShiftMapForIsg_Normal" 1 "TrsmShiftMapForIsg_7DCTRecuperation" 2 "TrsmShiftMapForIsg_7DCTGeneartion" 3 "TrsmShiftMapForIsg_Eco" 4 "TrsmShiftMapForIsg_Sport" 5 "TrsmShiftMapForIsg_Reserved1" 6 "TrsmShiftMapForIsg_Reserved2" 7 "TrsmShiftMapForIsg_Reserved3";
VAL_ 293 TrsmSailStsTrsmSts 0 "TrsmSts_Sleep" 1 "TrsmSts_Initialization" 2 "TrsmSts_ReadyRun" 3 "TrsmSts_Reserved" 4 "TrsmSts_ShutDown" 5 "TrsmSts_LimpHome" 6 "TrsmSts_Invalid" 7 "TrsmSts_Failure";
VAL_ 389 TrsmCluSlipLongDetd1 0 "Boolean_FALSE" 1 "Boolean_TRUE";
VAL_ 389 TrsmCluSlipLongDetd2 0 "Boolean_FALSE" 1 "Boolean_TRUE";
VAL_ 389 TrsmGearActAux 0 "PtGearAct1_Neut" 1 "PtGearAct1_Gear1" 2 "PtGearAct1_Gear2" 3 "PtGearAct1_Gear3" 4 "PtGearAct1_Gear4" 5 "PtGearAct1_Gear5" 6 "PtGearAct1_Gear6" 7 "PtGearAct1_Gear7" 8 "PtGearAct1_Gear8" 9 "PtGearAct1_Gear9" 10 "PtGearAct1_Gear10" 11 "PtGearAct1_Gear11" 12 "PtGearAct1_Gear12" 13 "PtGearAct1_Drv" 14 "PtGearAct1_Ukwn" 15 "PtGearAct1_Rvs";
VAL_ 128 TrsmActrPosn2TrsmActrPosn 0 "TrsmActrPosn1_Park" 1 "TrsmActrPosn1_ParkRvs" 2 "TrsmActrPosn1_Rvs" 3 "TrsmActrPosn1_RvsNeut" 4 "TrsmActrPosn1_Neut" 5 "TrsmActrPosn1_NeutDrv" 6 "TrsmActrPosn1_Drv" 7 "TrsmActrPosn1_Undefd";
VAL_ 128 UBoostReqByTrsm 0 "OnOff1_Off" 1 "OnOff1_On";
VAL_ 512 TrsmClrRdyReq 0 "OnOff1_Off" 1 "OnOff1_On";
VAL_ 512 TrsmEngmtLimd3TrsmEngmtLimd 0 "YesNo1_Yes" 1 "YesNo1_No";
VAL_ 512 TrsmErrIndcnReq2 0 "OnOff1_Off" 1 "OnOff1_On";
VAL_ 512 TrsmOilT2Sts 0 "TrsmOilTSts_StsNotOk" 1 "TrsmOilTSts_StsOk";
VAL_ 74 TrsmLockChkChk 0 "AvlSts2_NotAvl" 1 "AvlSts2_Avl";
VAL_ 74 TrsmLockSts 0 "TrsmLockSts_Undefd" 1 "TrsmLockSts_Unlocked" 2 "TrsmLockSts_Lockd" 3 "TrsmLockSts_Resd";
VAL_ 257 TrsmModAct 0 "PtTrsmModReq_EngdWithPMax" 1 "PtTrsmModReq_Engd" 2 "PtTrsmModReq_EngdEco" 3 "PtTrsmModReq_Resd1" 4 "PtTrsmModReq_Neut" 5 "PtTrsmModReq_NeutEco" 6 "PtTrsmModReq_Tran" 7 "PtTrsmModReq_TranWithTqCpChg";
VAL_ 257 TrsmToPrpsnCluTqRecTrsmCluTqMaxFastFlag 0 "Boolean_FALSE" 1 "Boolean_TRUE";
VAL_ 257 TrsmToPrpsnCluTqRecTrsmCluTqMaxForProtnFlag 0 "Boolean_FALSE" 1 "Boolean_TRUE";
VAL_ 257 TrsmToPrpsnCluTqRecTrsmCluTqMaxSlowFlag 0 "Boolean_FALSE" 1 "Boolean_TRUE";
VAL_ 257 TrsmToPrpsnCluTqRecTrsmCluTqMinFlag 0 "Boolean_FALSE" 1 "Boolean_TRUE";
VAL_ 261 TrsmGearChgProgs 0 "TrsmGearChgProgs1_GearShiftChgNotActv" 1 "TrsmGearChgProgs1_StrtPha" 2 "TrsmGearChgProgs1_TqPha" 3 "TrsmGearChgProgs1_JPha" 4 "TrsmGearChgProgs1_EndPha";
VAL_ 261 TrsmLockUpStTar 0 "PtLockUpType_OpenLockUp" 1 "PtLockUpType_SlipLockUp" 2 "PtLockUpType_MicroSlipLockUp" 3 "PtLockUpType_LockUpLockd";
VAL_ 261 TrsmToPrpsnNReqRecTrsmNReqCtrl 0 "OnOff1_Off" 1 "OnOff1_On";
VAL_ 629 TrsmEngmtLimdTrsmEngmtLimd 0 "YesNo1_Yes" 1 "YesNo1_No";
VAL_ 629 TrsmErrIndcnReq 0 "OnOff1_Off" 1 "OnOff1_On";
VAL_ 629 TrsmHotSt 0 "TrsmHotSt1_HotStNotActv" 1 "TrsmHotSt1_LvlHotSt1" 2 "TrsmHotSt1_LvlHotSt2";
VAL_ 629 TrsmReqForPfmncRedn 0 "Boolean_FALSE" 1 "Boolean_TRUE";
VAL_ 263 TrsmFltIndcn 0 "TrsmFltIndcn1_TrsmFltIndcnNoReq" 1 "TrsmFltIndcn1_TrsmFltIndcn1" 2 "TrsmFltIndcn1_TrsmFltIndcn2" 3 "TrsmFltIndcn1_TrsmFltIndcn3" 4 "TrsmFltIndcn1_TrsmFltIndcn4" 5 "TrsmFltIndcn1_TrsmFltIndcn5" 6 "TrsmFltIndcn1_TrsmFltIndcn6" 7 "TrsmFltIndcn1_TrsmFltIndcn7" 8 "TrsmFltIndcn1_TrsmFltIndcn8" 9 "TrsmFltIndcn1_TrsmFltIndcn9" 10 "TrsmFltIndcn1_TrsmFltIndcn10" 11 "TrsmFltIndcn1_TrsmFltIndcn11" 12 "TrsmFltIndcn1_TrsmFltIndcn12" 13 "TrsmFltIndcn1_TrsmFltIndcn13" 14 "TrsmFltIndcn1_TrsmFltIndcn14" 15 "TrsmFltIndcn1_TrsmFltIndcn15" 16 "TrsmFltIndcn1_TrsmFltIndcn16" 17 "TrsmFltIndcn1_TrsmFltIndcn17" 18 "TrsmFltIndcn1_TrsmFltIndcn18" 19 "TrsmFltIndcn1_TrsmFltIndcn19" 20 "TrsmFltIndcn1_TrsmFltIndcn20" 21 "TrsmFltIndcn1_TrsmFltIndcn21" 22 "TrsmFltIndcn1_TrsmFltIndcn22" 23 "TrsmFltIndcn1_TrsmFltIndcn23" 24 "TrsmFltIndcn1_TrsmFltIndcn24" 25 "TrsmFltIndcn1_TrsmFltIndcn25" 26 "TrsmFltIndcn1_TrsmFltIndcn26" 27 "TrsmFltIndcn1_TrsmFltIndcn27" 28 "TrsmFltIndcn1_TrsmFltIndcn28" 29 "TrsmFltIndcn1_TrsmFltIndcn29" 30 "TrsmFltIndcn1_TrsmFltIndcn30" 31 "TrsmFltIndcn1_TrsmFltIndcn31";
VAL_ 763 VFCVectorTCMAWVFCid0 0 "VFCOnOff_Off" 1 "VFCOnOff_On";
VAL_ 763 VFCVectorTCMAWVFCid1 0 "VFCOnOff_Off" 1 "VFCOnOff_On";
VAL_ 763 VFCVectorTCMAWVFCid10 0 "VFCOnOff_Off" 1 "VFCOnOff_On";
VAL_ 763 VFCVectorTCMAWVFCid11 0 "VFCOnOff_Off" 1 "VFCOnOff_On";
VAL_ 763 VFCVectorTCMAWVFCid12 0 "VFCOnOff_Off" 1 "VFCOnOff_On";
VAL_ 763 VFCVectorTCMAWVFCid13 0 "VFCOnOff_Off" 1 "VFCOnOff_On";
VAL_ 763 VFCVectorTCMAWVFCid14 0 "VFCOnOff_Off" 1 "VFCOnOff_On";
VAL_ 763 VFCVectorTCMAWVFCid15 0 "VFCOnOff_Off" 1 "VFCOnOff_On";
VAL_ 763 VFCVectorTCMAWVFCid16 0 "VFCOnOff_Off" 1 "VFCOnOff_On";
VAL_ 763 VFCVectorTCMAWVFCid17 0 "VFCOnOff_Off" 1 "VFCOnOff_On";
VAL_ 763 VFCVectorTCMAWVFCid18 0 "VFCOnOff_Off" 1 "VFCOnOff_On";
VAL_ 763 VFCVectorTCMAWVFCid19 0 "VFCOnOff_Off" 1 "VFCOnOff_On";
VAL_ 763 VFCVectorTCMAWVFCid2 0 "VFCOnOff_Off" 1 "VFCOnOff_On";
VAL_ 763 VFCVectorTCMAWVFCid20 0 "VFCOnOff_Off" 1 "VFCOnOff_On";
VAL_ 763 VFCVectorTCMAWVFCid21 0 "VFCOnOff_Off" 1 "VFCOnOff_On";
VAL_ 763 VFCVectorTCMAWVFCid22 0 "VFCOnOff_Off" 1 "VFCOnOff_On";
VAL_ 763 VFCVectorTCMAWVFCid23 0 "VFCOnOff_Off" 1 "VFCOnOff_On";
VAL_ 763 VFCVectorTCMAWVFCid24 0 "VFCOnOff_Off" 1 "VFCOnOff_On";
VAL_ 763 VFCVectorTCMAWVFCid25 0 "VFCOnOff_Off" 1 "VFCOnOff_On";
VAL_ 763 VFCVectorTCMAWVFCid26 0 "VFCOnOff_Off" 1 "VFCOnOff_On";
VAL_ 763 VFCVectorTCMAWVFCid27 0 "VFCOnOff_Off" 1 "VFCOnOff_On";
VAL_ 763 VFCVectorTCMAWVFCid28 0 "VFCOnOff_Off" 1 "VFCOnOff_On";
VAL_ 763 VFCVectorTCMAWVFCid29 0 "VFCOnOff_Off" 1 "VFCOnOff_On";
VAL_ 763 VFCVectorTCMAWVFCid3 0 "VFCOnOff_Off" 1 "VFCOnOff_On";
VAL_ 763 VFCVectorTCMAWVFCid30 0 "VFCOnOff_Off" 1 "VFCOnOff_On";
VAL_ 763 VFCVectorTCMAWVFCid31 0 "VFCOnOff_Off" 1 "VFCOnOff_On";
VAL_ 763 VFCVectorTCMAWVFCid32 0 "VFCOnOff_Off" 1 "VFCOnOff_On";
VAL_ 763 VFCVectorTCMAWVFCid33 0 "VFCOnOff_Off" 1 "VFCOnOff_On";
VAL_ 763 VFCVectorTCMAWVFCid34 0 "VFCOnOff_Off" 1 "VFCOnOff_On";
VAL_ 763 VFCVectorTCMAWVFCid35 0 "VFCOnOff_Off" 1 "VFCOnOff_On";
VAL_ 763 VFCVectorTCMAWVFCid36 0 "VFCOnOff_Off" 1 "VFCOnOff_On";
VAL_ 763 VFCVectorTCMAWVFCid37 0 "VFCOnOff_Off" 1 "VFCOnOff_On";
VAL_ 763 VFCVectorTCMAWVFCid38 0 "VFCOnOff_Off" 1 "VFCOnOff_On";
VAL_ 763 VFCVectorTCMAWVFCid39 0 "VFCOnOff_Off" 1 "VFCOnOff_On";
VAL_ 763 VFCVectorTCMAWVFCid4 0 "VFCOnOff_Off" 1 "VFCOnOff_On";
VAL_ 763 VFCVectorTCMAWVFCid40 0 "VFCOnOff_Off" 1 "VFCOnOff_On";
VAL_ 763 VFCVectorTCMAWVFCid41 0 "VFCOnOff_Off" 1 "VFCOnOff_On";
VAL_ 763 VFCVectorTCMAWVFCid42 0 "VFCOnOff_Off" 1 "VFCOnOff_On";
VAL_ 763 VFCVectorTCMAWVFCid43 0 "VFCOnOff_Off" 1 "VFCOnOff_On";
VAL_ 763 VFCVectorTCMAWVFCid44 0 "VFCOnOff_Off" 1 "VFCOnOff_On";
VAL_ 763 VFCVectorTCMAWVFCid45 0 "VFCOnOff_Off" 1 "VFCOnOff_On";
VAL_ 763 VFCVectorTCMAWVFCid46 0 "VFCOnOff_Off" 1 "VFCOnOff_On";
VAL_ 763 VFCVectorTCMAWVFCid47 0 "VFCOnOff_Off" 1 "VFCOnOff_On";
VAL_ 763 VFCVectorTCMAWVFCid48 0 "VFCOnOff_Off" 1 "VFCOnOff_On";
VAL_ 763 VFCVectorTCMAWVFCid49 0 "VFCOnOff_Off" 1 "VFCOnOff_On";
VAL_ 763 VFCVectorTCMAWVFCid5 0 "VFCOnOff_Off" 1 "VFCOnOff_On";
VAL_ 763 VFCVectorTCMAWVFCid50 0 "VFCOnOff_Off" 1 "VFCOnOff_On";
VAL_ 763 VFCVectorTCMAWVFCid51 0 "VFCOnOff_Off" 1 "VFCOnOff_On";
VAL_ 763 VFCVectorTCMAWVFCid52 0 "VFCOnOff_Off" 1 "VFCOnOff_On";
VAL_ 763 VFCVectorTCMAWVFCid53 0 "VFCOnOff_Off" 1 "VFCOnOff_On";
VAL_ 763 VFCVectorTCMAWVFCid54 0 "VFCOnOff_Off" 1 "VFCOnOff_On";
VAL_ 763 VFCVectorTCMAWVFCid55 0 "VFCOnOff_Off" 1 "VFCOnOff_On";
VAL_ 763 VFCVectorTCMAWVFCid56 0 "VFCOnOff_Off" 1 "VFCOnOff_On";
VAL_ 763 VFCVectorTCMAWVFCid57 0 "VFCOnOff_Off" 1 "VFCOnOff_On";
VAL_ 763 VFCVectorTCMAWVFCid58 0 "VFCOnOff_Off" 1 "VFCOnOff_On";
VAL_ 763 VFCVectorTCMAWVFCid59 0 "VFCOnOff_Off" 1 "VFCOnOff_On";
VAL_ 763 VFCVectorTCMAWVFCid6 0 "VFCOnOff_Off" 1 "VFCOnOff_On";
VAL_ 763 VFCVectorTCMAWVFCid60 0 "VFCOnOff_Off" 1 "VFCOnOff_On";
VAL_ 763 VFCVectorTCMAWVFCid61 0 "VFCOnOff_Off" 1 "VFCOnOff_On";
VAL_ 763 VFCVectorTCMAWVFCid7 0 "VFCOnOff_Off" 1 "VFCOnOff_On";
VAL_ 763 VFCVectorTCMAWVFCid8 0 "VFCOnOff_Off" 1 "VFCOnOff_On";
VAL_ 763 VFCVectorTCMAWVFCid9 0 "VFCOnOff_Off" 1 "VFCOnOff_On";
VAL_ 1352 VFCVectorTCMVFCid0 0 "VFCOnOff_Off" 1 "VFCOnOff_On";
VAL_ 1352 VFCVectorTCMVFCid1 0 "VFCOnOff_Off" 1 "VFCOnOff_On";
VAL_ 1352 VFCVectorTCMVFCid10 0 "VFCOnOff_Off" 1 "VFCOnOff_On";
VAL_ 1352 VFCVectorTCMVFCid11 0 "VFCOnOff_Off" 1 "VFCOnOff_On";
VAL_ 1352 VFCVectorTCMVFCid12 0 "VFCOnOff_Off" 1 "VFCOnOff_On";
VAL_ 1352 VFCVectorTCMVFCid13 0 "VFCOnOff_Off" 1 "VFCOnOff_On";
VAL_ 1352 VFCVectorTCMVFCid14 0 "VFCOnOff_Off" 1 "VFCOnOff_On";
VAL_ 1352 VFCVectorTCMVFCid15 0 "VFCOnOff_Off" 1 "VFCOnOff_On";
VAL_ 1352 VFCVectorTCMVFCid16 0 "VFCOnOff_Off" 1 "VFCOnOff_On";
VAL_ 1352 VFCVectorTCMVFCid17 0 "VFCOnOff_Off" 1 "VFCOnOff_On";
VAL_ 1352 VFCVectorTCMVFCid18 0 "VFCOnOff_Off" 1 "VFCOnOff_On";
VAL_ 1352 VFCVectorTCMVFCid19 0 "VFCOnOff_Off" 1 "VFCOnOff_On";
VAL_ 1352 VFCVectorTCMVFCid2 0 "VFCOnOff_Off" 1 "VFCOnOff_On";
VAL_ 1352 VFCVectorTCMVFCid20 0 "VFCOnOff_Off" 1 "VFCOnOff_On";
VAL_ 1352 VFCVectorTCMVFCid21 0 "VFCOnOff_Off" 1 "VFCOnOff_On";
VAL_ 1352 VFCVectorTCMVFCid22 0 "VFCOnOff_Off" 1 "VFCOnOff_On";
VAL_ 1352 VFCVectorTCMVFCid23 0 "VFCOnOff_Off" 1 "VFCOnOff_On";
VAL_ 1352 VFCVectorTCMVFCid24 0 "VFCOnOff_Off" 1 "VFCOnOff_On";
VAL_ 1352 VFCVectorTCMVFCid25 0 "VFCOnOff_Off" 1 "VFCOnOff_On";
VAL_ 1352 VFCVectorTCMVFCid26 0 "VFCOnOff_Off" 1 "VFCOnOff_On";
VAL_ 1352 VFCVectorTCMVFCid27 0 "VFCOnOff_Off" 1 "VFCOnOff_On";
VAL_ 1352 VFCVectorTCMVFCid28 0 "VFCOnOff_Off" 1 "VFCOnOff_On";
VAL_ 1352 VFCVectorTCMVFCid29 0 "VFCOnOff_Off" 1 "VFCOnOff_On";
VAL_ 1352 VFCVectorTCMVFCid3 0 "VFCOnOff_Off" 1 "VFCOnOff_On";
VAL_ 1352 VFCVectorTCMVFCid30 0 "VFCOnOff_Off" 1 "VFCOnOff_On";
VAL_ 1352 VFCVectorTCMVFCid31 0 "VFCOnOff_Off" 1 "VFCOnOff_On";
VAL_ 1352 VFCVectorTCMVFCid32 0 "VFCOnOff_Off" 1 "VFCOnOff_On";
VAL_ 1352 VFCVectorTCMVFCid33 0 "VFCOnOff_Off" 1 "VFCOnOff_On";
VAL_ 1352 VFCVectorTCMVFCid34 0 "VFCOnOff_Off" 1 "VFCOnOff_On";
VAL_ 1352 VFCVectorTCMVFCid35 0 "VFCOnOff_Off" 1 "VFCOnOff_On";
VAL_ 1352 VFCVectorTCMVFCid36 0 "VFCOnOff_Off" 1 "VFCOnOff_On";
VAL_ 1352 VFCVectorTCMVFCid37 0 "VFCOnOff_Off" 1 "VFCOnOff_On";
VAL_ 1352 VFCVectorTCMVFCid38 0 "VFCOnOff_Off" 1 "VFCOnOff_On";
VAL_ 1352 VFCVectorTCMVFCid39 0 "VFCOnOff_Off" 1 "VFCOnOff_On";
VAL_ 1352 VFCVectorTCMVFCid4 0 "VFCOnOff_Off" 1 "VFCOnOff_On";
VAL_ 1352 VFCVectorTCMVFCid40 0 "VFCOnOff_Off" 1 "VFCOnOff_On";
VAL_ 1352 VFCVectorTCMVFCid41 0 "VFCOnOff_Off" 1 "VFCOnOff_On";
VAL_ 1352 VFCVectorTCMVFCid42 0 "VFCOnOff_Off" 1 "VFCOnOff_On";
VAL_ 1352 VFCVectorTCMVFCid43 0 "VFCOnOff_Off" 1 "VFCOnOff_On";
VAL_ 1352 VFCVectorTCMVFCid44 0 "VFCOnOff_Off" 1 "VFCOnOff_On";
VAL_ 1352 VFCVectorTCMVFCid45 0 "VFCOnOff_Off" 1 "VFCOnOff_On";
VAL_ 1352 VFCVectorTCMVFCid46 0 "VFCOnOff_Off" 1 "VFCOnOff_On";
VAL_ 1352 VFCVectorTCMVFCid47 0 "VFCOnOff_Off" 1 "VFCOnOff_On";
VAL_ 1352 VFCVectorTCMVFCid48 0 "VFCOnOff_Off" 1 "VFCOnOff_On";
VAL_ 1352 VFCVectorTCMVFCid49 0 "VFCOnOff_Off" 1 "VFCOnOff_On";
VAL_ 1352 VFCVectorTCMVFCid5 0 "VFCOnOff_Off" 1 "VFCOnOff_On";
VAL_ 1352 VFCVectorTCMVFCid50 0 "VFCOnOff_Off" 1 "VFCOnOff_On";
VAL_ 1352 VFCVectorTCMVFCid51 0 "VFCOnOff_Off" 1 "VFCOnOff_On";
VAL_ 1352 VFCVectorTCMVFCid52 0 "VFCOnOff_Off" 1 "VFCOnOff_On";
VAL_ 1352 VFCVectorTCMVFCid53 0 "VFCOnOff_Off" 1 "VFCOnOff_On";
VAL_ 1352 VFCVectorTCMVFCid54 0 "VFCOnOff_Off" 1 "VFCOnOff_On";
VAL_ 1352 VFCVectorTCMVFCid55 0 "VFCOnOff_Off" 1 "VFCOnOff_On";
VAL_ 1352 VFCVectorTCMVFCid56 0 "VFCOnOff_Off" 1 "VFCOnOff_On";
VAL_ 1352 VFCVectorTCMVFCid57 0 "VFCOnOff_Off" 1 "VFCOnOff_On";
VAL_ 1352 VFCVectorTCMVFCid58 0 "VFCOnOff_Off" 1 "VFCOnOff_On";
VAL_ 1352 VFCVectorTCMVFCid59 0 "VFCOnOff_Off" 1 "VFCOnOff_On";
VAL_ 1352 VFCVectorTCMVFCid6 0 "VFCOnOff_Off" 1 "VFCOnOff_On";
VAL_ 1352 VFCVectorTCMVFCid60 0 "VFCOnOff_Off" 1 "VFCOnOff_On";
VAL_ 1352 VFCVectorTCMVFCid61 0 "VFCOnOff_Off" 1 "VFCOnOff_On";
VAL_ 1352 VFCVectorTCMVFCid7 0 "VFCOnOff_Off" 1 "VFCOnOff_On";
VAL_ 1352 VFCVectorTCMVFCid8 0 "VFCOnOff_Off" 1 "VFCOnOff_On";
VAL_ 1352 VFCVectorTCMVFCid9 0 "VFCOnOff_Off" 1 "VFCOnOff_On";
VAL_ 81 AsyDataWithCmpSafeALat1Qf 0 "Qf1_DevOfDataUndefd" 1 "Qf1_DataTmpUndefdAndEvlnInProgs" 2 "Qf1_DevOfDataNotWithinRngAllwd" 3 "Qf1_DataCalcdWithDevDefd";
VAL_ 81 AsyDataWithCmpSafeALgt1Qf 0 "Qf1_DevOfDataUndefd" 1 "Qf1_DataTmpUndefdAndEvlnInProgs" 2 "Qf1_DevOfDataNotWithinRngAllwd" 3 "Qf1_DataCalcdWithDevDefd";
VAL_ 81 AsyDataWithCmpSafeYawRateQf 0 "Qf1_DevOfDataUndefd" 1 "Qf1_DataTmpUndefdAndEvlnInProgs" 2 "Qf1_DevOfDataNotWithinRngAllwd" 3 "Qf1_DataCalcdWithDevDefd";
VAL_ 160 ADataRawSafeALat1Qf 0 "Qf1_DevOfDataUndefd" 1 "Qf1_DataTmpUndefdAndEvlnInProgs" 2 "Qf1_DevOfDataNotWithinRngAllwd" 3 "Qf1_DataCalcdWithDevDefd";
VAL_ 160 ADataRawSafeALgt1Qf 0 "Qf1_DevOfDataUndefd" 1 "Qf1_DataTmpUndefdAndEvlnInProgs" 2 "Qf1_DevOfDataNotWithinRngAllwd" 3 "Qf1_DataCalcdWithDevDefd";
VAL_ 160 ADataRawSafeAVertQf 0 "Qf1_DevOfDataUndefd" 1 "Qf1_DataTmpUndefdAndEvlnInProgs" 2 "Qf1_DevOfDataNotWithinRngAllwd" 3 "Qf1_DataCalcdWithDevDefd";
VAL_ 400 AbsCtrlActvCtrlSts1 0 "CtrlSts1_NoCtrl" 1 "CtrlSts1_InCtrl";
VAL_ 400 AmbTRawQly 0 "GenQf1_UndefindDataAccur" 1 "GenQf1_TmpUndefdData" 2 "GenQf1_DataAccurNotWithinSpcn" 3 "GenQf1_AccurData";
VAL_ 400 LatCtrlReqSafeLatCtrlModReq 0 "LatCtrlMod1_NoReq" 1 "LatCtrlMod1_HighWayAssist" 2 "LatCtrlMod1_EmgyLaneKeepAidForObjRe" 3 "LatCtrlMod1_EmgyLaneKeepAidForStat" 4 "LatCtrlMod1_SftyLaneKeepAid" 5 "LatCtrlMod1_SteerAssc" 6 "LatCtrlMod1_DsrOversteer" 7 "LatCtrlMod1_DsrMueSplit" 8 "LatCtrlMod1_DsrTrlrStaby" 9 "LatCtrlMod1_EmgyManvAssi" 10 "LatCtrlMod1_Reserved1" 11 "LatCtrlMod1_Reserved2" 12 "LatCtrlMod1_SHWA" 13 "LatCtrlMod1_APA" 14 "LatCtrlMod1_RPA" 15 "LatCtrlMod1_HPA";
VAL_ 400 LatCtrlReqSafeSteerWhlHptcWarnReq 0 "OnOff1_Off" 1 "OnOff1_On";
VAL_ 224 CnvnReq 0 "CnvnReq_NotReqd" 1 "CnvnReq_Chrgn" 2 "CnvnReq_Resd1" 3 "CnvnReq_Resd2" 4 "CnvnReq_Resd3" 5 "CnvnReq_Resd4" 6 "CnvnReq_Resd5" 7 "CnvnReq_Resd6";
VAL_ 224 DrvrCrsCtrlFctSeld 0 "DrvrCrsCtrlFctSeldTyp_Off" 1 "DrvrCrsCtrlFctSeldTyp_SpdLimFct_Main_Swt" 2 "DrvrCrsCtrlFctSeldTyp_SpdLimFct_Resu" 3 "DrvrCrsCtrlFctSeldTyp_CrsCtrlFct_Main_Swt" 4 "DrvrCrsCtrlFctSeldTyp_CrsCtrlFct_Resu" 5 "DrvrCrsCtrlFctSeldTyp_AccFct_Main_Swt" 6 "DrvrCrsCtrlFctSeldTyp_AccFct_Resu" 7 "DrvrCrsCtrlFctSeldTyp_Reserved";
VAL_ 224 EngRunngReqByParkAssi1 0 "EngRunngReqByParkAssi1_Default" 1 "EngRunngReqByParkAssi1_StopInhibited" 2 "EngRunngReqByParkAssi1_RequestToKeepTheEngineRunning" 3 "EngRunngReqByParkAssi1_Reserved";
VAL_ 224 VehSpdLgtQf 0 "GenQf1_UndefindDataAccur" 1 "GenQf1_TmpUndefdData" 2 "GenQf1_DataAccurNotWithinSpcn" 3 "GenQf1_AccurData";
VAL_ 928 AmbTIndcdWithUnitAmbTIndcdUnit 0 "AmbTIndcdUnit_Celsius" 1 "AmbTIndcdUnit_Fahrenheit" 2 "AmbTIndcdUnit_UkwnUnit";
VAL_ 928 AmbTIndcdWithUnitQF 0 "GenQf1_UndefindDataAccur" 1 "GenQf1_TmpUndefdData" 2 "GenQf1_DataAccurNotWithinSpcn" 3 "GenQf1_AccurData";
VAL_ 928 CmptmtTReCmptmtTFrntQf 0 "CmptmtTFrntQf_SnsrDataUndefd" 1 "CmptmtTFrntQf_FanNotRunning" 2 "CmptmtTFrntQf_SnsrDataNotOk" 3 "CmptmtTFrntQf_SnsrDataOk";
VAL_ 928 CmptmtTReFanForCmptmtTRunng 0 "Flg1_Rst" 1 "Flg1_Set";
VAL_ 928 ReHvacBlowerSts 0 "HvacFanSts_Off" 1 "HvacFanSts_On" 2 "HvacFanSts_Warning" 3 "HvacFanSts_Error";
VAL_ 433 BrkPedlPsdBrkPedlNotPsdSafe 0 "NoYes1_No" 1 "NoYes1_Yes";
VAL_ 433 BrkPedlPsdBrkPedlPsd 0 "NoYes1_No" 1 "NoYes1_Yes";
VAL_ 433 BrkPedlPsdQf 0 "GenQf1_UndefindDataAccur" 1 "GenQf1_TmpUndefdData" 2 "GenQf1_DataAccurNotWithinSpcn" 3 "GenQf1_AccurData";
VAL_ 433 WhlSpdCircumlFrntLeQf 0 "GenQf1_UndefindDataAccur" 1 "GenQf1_TmpUndefdData" 2 "GenQf1_DataAccurNotWithinSpcn" 3 "GenQf1_AccurData";
VAL_ 433 WhlSpdCircumlFrntRiQf 0 "GenQf1_UndefindDataAccur" 1 "GenQf1_TmpUndefdData" 2 "GenQf1_DataAccurNotWithinSpcn" 3 "GenQf1_AccurData";
VAL_ 1087 ReEvapVlvSts 0 "EvaprVlvSts_VlvReqdToClsd" 1 "EvaprVlvSts_VlvReqdToOpen" 2 "EvaprVlvSts_ElecErrByCircOpen" 3 "EvaprVlvSts_ElecErrShoToGnd" 4 "EvaprVlvSts_ElecErrShoToPwrSply" 5 "EvaprVlvSts_Resd";
VAL_ 432 AgDataRawSafeRollRateQf 0 "Qf1_DevOfDataUndefd" 1 "Qf1_DataTmpUndefdAndEvlnInProgs" 2 "Qf1_DevOfDataNotWithinRngAllwd" 3 "Qf1_DataCalcdWithDevDefd";
VAL_ 432 AgDataRawSafeYawRateQf 0 "Qf1_DevOfDataUndefd" 1 "Qf1_DataTmpUndefdAndEvlnInProgs" 2 "Qf1_DevOfDataNotWithinRngAllwd" 3 "Qf1_DataCalcdWithDevDefd";
VAL_ 367 TrsmLockMgrReqCmd 0 "TrsmLockMgrCmd_Undefd" 1 "TrsmLockMgrCmd_Unlck" 2 "TrsmLockMgrCmd_Lock" 3 "TrsmLockMgrCmd_Resd";
VAL_ 736 VehModMngtGlbSafe1CarModSts1 0 "CarModSts1_CarModNorm" 1 "CarModSts1_CarModTrnsp" 2 "CarModSts1_CarModFcy" 3 "CarModSts1_CarModCrash" 5 "CarModSts1_CarModDyno";
VAL_ 736 VehModMngtGlbSafe1FltEgyCnsWdSts 0 "FltEgyCns1_NoFlt" 1 "FltEgyCns1_Flt";
VAL_ 736 VehModMngtGlbSafe1UsgModSts 0 "UsgModSts1_UsgModAbdnd" 1 "UsgModSts1_UsgModInActv" 2 "UsgModSts1_UsgModCnvinc" 11 "UsgModSts1_UsgModActv" 13 "UsgModSts1_UsgModDrvg";
VAL_ 38 ChrgSoftSwCtrlSt 0 "OnOffNoReq_NoReq" 1 "OnOffNoReq_On" 2 "OnOffNoReq_Off";
VAL_ 38 IntelliClimaReq 0 "CmptSts_NoRequest" 1 "CmptSts_CoolingRequest" 2 "CmptSts_HeatingRequest" 3 "CmptSts_CoolingAndHeatingRequest" 4 "CmptSts_Reserved";
VAL_ 38 VFCInfoEna 0 "EnableDisableCoding_Disabled" 1 "EnableDisableCoding_Enabled";
VAL_ 1123 EvaprTReEvaprTQf 0 "HvacTIfQf_SnsrDataNotOk" 1 "HvacTIfQf_SnsrDataOk";
VAL_ 1123 SteerSetgPen 0 "IdPen_ProfUkwn" 1 "IdPen_Prof1" 2 "IdPen_Prof2" 3 "IdPen_Prof3" 4 "IdPen_Prof4" 5 "IdPen_Prof5" 6 "IdPen_Prof6" 7 "IdPen_Prof7" 8 "IdPen_Prof8" 9 "IdPen_Prof9" 10 "IdPen_Prof10" 11 "IdPen_Prof11" 12 "IdPen_Prof12" 13 "IdPen_Prof13" 14 "IdPen_Resd14" 15 "IdPen_ProfAll";
VAL_ 1123 SteerSetgSteerAsscLvl 0 "SteerAsscLvl_Ukwn" 1 "SteerAsscLvl_Lvl1" 2 "SteerAsscLvl_Lvl2" 3 "SteerAsscLvl_Lvl3" 4 "SteerAsscLvl_Lvl4" 5 "SteerAsscLvl_Resd5" 6 "SteerAsscLvl_Resd6" 7 "SteerAsscLvl_Resd7";
VAL_ 1123 SteerSetgSteerMod 0 "SteerMod_Ukwn" 1 "SteerMod_Mod1" 2 "SteerMod_Mod2" 3 "SteerMod_Mod3" 4 "SteerMod_Mod4" 5 "SteerMod_Resd5" 6 "SteerMod_Resd6" 7 "SteerMod_Resd7";
VAL_ 784 CmptmtTFrntFanForCmptmtTRunng 0 "Flg1_Rst" 1 "Flg1_Set";
VAL_ 784 CmptmtTFrntQf 0 "CmptmtTFrntQf_SnsrDataUndefd" 1 "CmptmtTFrntQf_FanNotRunning" 2 "CmptmtTFrntQf_SnsrDataNotOk" 3 "CmptmtTFrntQf_SnsrDataOk";
VAL_ 137 HsaSt 0 "YesNo2_No" 1 "YesNo2_Yes";
VAL_ 137 LVPwrSplyErrSts 0 "PwrSplyErrSts_SysOk" 1 "PwrSplyErrSts_UhiDurgDrvg" 2 "PwrSplyErrSts_UloDurgdrvg" 3 "PwrSplyErrSts_BattRlyFlt" 4 "PwrSplyErrSts_BattSnsrComFlt" 5 "PwrSplyErrSts_BattSnsrHwFlt" 6 "PwrSplyErrSts_FltComDcDc" 7 "PwrSplyErrSts_FltElecDcDc" 8 "PwrSplyErrSts_FltDcDc" 9 "PwrSplyErrSts_SupCptrHwFlt" 10 "PwrSplyErrSts_AltFltMecl" 11 "PwrSplyErrSts_AltFltElec" 12 "PwrSplyErrSts_AltFltT" 13 "PwrSplyErrSts_AltFltCom" 14 "PwrSplyErrSts_SpprtBattFltChrgn" 15 "PwrSplyErrSts_Spare6";
VAL_ 137 WhlFastSpdSafeQF 0 "GenQf1_UndefindDataAccur" 1 "GenQf1_TmpUndefdData" 2 "GenQf1_DataAccurNotWithinSpcn" 3 "GenQf1_AccurData";
VAL_ 775 BookChrgnActvdReq 0 "Boolean_FALSE" 1 "Boolean_TRUE";
VAL_ 775 BookChrgSetReq 0 "Boolean_FALSE" 1 "Boolean_TRUE";
VAL_ 775 BookStopTiAchieved 0 "Boolean_FALSE" 1 "Boolean_TRUE";
VAL_ 823 ClimaCmptSts 0 "CmptSts_NoRequest" 1 "CmptSts_CoolingRequest" 2 "CmptSts_HeatingRequest" 3 "CmptSts_CoolingAndHeatingRequest" 4 "CmptSts_Reserved";
VAL_ 823 ClimaDefrstSts 0 "OnOff1_Off" 1 "OnOff1_On";
VAL_ 823 FrntHvacBlowerSts 0 "HvacFanSts_Off" 1 "HvacFanSts_On" 2 "HvacFanSts_Warning" 3 "HvacFanSts_Error";
VAL_ 686 AbsSts 0 "DevErrSts2_NoFlt" 1 "DevErrSts2_Flt";
VAL_ 686 DrvModReq 0 "DrvModReqType1_Undefd" 1 "DrvModReqType1_ECO" 2 "DrvModReqType1_Comfort_Normal" 3 "DrvModReqType1_Dynamic_Sport" 4 "DrvModReqType1_Individual" 5 "DrvModReqType1_Offroad_CrossTerrain" 6 "DrvModReqType1_AWD" 7 "DrvModReqType1_Race" 8 "DrvModReqType1_Pure_EV" 9 "DrvModReqType1_Hybrid" 10 "DrvModReqType1_Power" 11 "DrvModReqType1_Snow" 12 "DrvModReqType1_Sand" 13 "DrvModReqType1_Mud" 14 "DrvModReqType1_Rock" 15 "DrvModReqType1_Err";
VAL_ 686 HvacHexAirTHvacAirTForHeatrFrntQf 0 "OkNotOk_NotOk" 1 "OkNotOk_Ok";
VAL_ 686 ULoWarnULoWarn 0 "ULoWarn_UOk" 1 "ULoWarn_ULoTmp" 2 "ULoWarn_ULoPrmnt";
VAL_ 1243 HvacAirTForRowFirstAtFlrLeEvaprTQf 0 "HvacTIfQf_SnsrDataNotOk" 1 "HvacTIfQf_SnsrDataOk";
VAL_ 1243 HvacAirTForRowFirstAtFlrRiEvaprTQf 0 "HvacTIfQf_SnsrDataNotOk" 1 "HvacTIfQf_SnsrDataOk";
VAL_ 1243 HvacAirTForRowFirstAtVentLeEvaprTQf 0 "HvacTIfQf_SnsrDataNotOk" 1 "HvacTIfQf_SnsrDataOk";
VAL_ 1243 HvacAirTForRowFirstAtVentRiEvaprTQf 0 "HvacTIfQf_SnsrDataNotOk" 1 "HvacTIfQf_SnsrDataOk";
VAL_ 1255 HvacAirTForRowSecAtFlrLeEvaprTQf 0 "HvacTIfQf_SnsrDataNotOk" 1 "HvacTIfQf_SnsrDataOk";
VAL_ 1255 HvacAirTForRowSecAtFlrRiEvaprTQf 0 "HvacTIfQf_SnsrDataNotOk" 1 "HvacTIfQf_SnsrDataOk";
VAL_ 1255 HvacAirTForRowSecAtVentLeEvaprTQf 0 "HvacTIfQf_SnsrDataNotOk" 1 "HvacTIfQf_SnsrDataOk";
VAL_ 1255 HvacAirTForRowSecAtVentRiEvaprTQf 0 "HvacTIfQf_SnsrDataNotOk" 1 "HvacTIfQf_SnsrDataOk";
VAL_ 1267 EscStEscSt 0 "EscSt1_Inin" 1 "EscSt1_Ok" 2 "EscSt1_TmpErr" 3 "EscSt1_PrmntErr" 4 "EscSt1_UsrOff";
VAL_ 1267 HvacCondsorTEvaprTQf 0 "HvacTIfQf_SnsrDataNotOk" 1 "HvacTIfQf_SnsrDataOk";
VAL_ 1267 HvacCondsorTspEvaprTQf 0 "HvacTIfQf_SnsrDataNotOk" 1 "HvacTIfQf_SnsrDataOk";
VAL_ 1267 HvacOsaAndRecActrQfForHp 0 "Err1_NoErr" 1 "Err1_Err";
VAL_ 1099 AmbTEstimdQf 0 "HvacTIfQf_SnsrDataNotOk" 1 "HvacTIfQf_SnsrDataOk";
VAL_ 1099 BrkTracCtrlActv 0 "CtrlSts1_NoCtrl" 1 "CtrlSts1_InCtrl";
VAL_ 1099 HvacHeatgReq 0 "OnOff1_Off" 1 "OnOff1_On";
VAL_ 26 EgyRgnLvlSet 0 "EgyRgnLvlSet_Level1" 1 "EgyRgnLvlSet_Level2" 2 "EgyRgnLvlSet_Level3" 3 "EgyRgnLvlSet_Level4";
VAL_ 1159 VehMtnStVehMtnSt 0 "VehMtnSt2_Ukwn" 1 "VehMtnSt2_StandStillVal1" 2 "VehMtnSt2_StandStillVal2" 3 "VehMtnSt2_StandStillVal3" 4 "VehMtnSt2_RollgFwdVal1" 5 "VehMtnSt2_RollgFwdVal2" 6 "VehMtnSt2_RollgBackwVal1" 7 "VehMtnSt2_RollgBackwVal2";
VAL_ 864 HvacHeatrInletTempReqEvaprTQf 0 "HvacTIfQf_SnsrDataNotOk" 1 "HvacTIfQf_SnsrDataOk";
VAL_ 864 ProfPenSts1 0 "IdPen_ProfUkwn" 1 "IdPen_Prof1" 2 "IdPen_Prof2" 3 "IdPen_Prof3" 4 "IdPen_Prof4" 5 "IdPen_Prof5" 6 "IdPen_Prof6" 7 "IdPen_Prof7" 8 "IdPen_Prof8" 9 "IdPen_Prof9" 10 "IdPen_Prof10" 11 "IdPen_Prof11" 12 "IdPen_Prof12" 13 "IdPen_Prof13" 14 "IdPen_Resd14" 15 "IdPen_ProfAll";
VAL_ 864 SaveSetgToMemPrmnt 0 "OffOnAut1_Off" 1 "OffOnAut1_On" 2 "OffOnAut1_Aut";
VAL_ 896 VehBattUSysUQf 0 "GenQf1_UndefindDataAccur" 1 "GenQf1_TmpUndefdData" 2 "GenQf1_DataAccurNotWithinSpcn" 3 "GenQf1_AccurData";
VAL_ 513 ImobEngMgrReq3ImobEngMgrCmdTar1 0 "ImobEngMgrReqCmd_ImobEngCmdTarIdle" 1 "ImobEngMgrReqCmd_ImobEngMtnStrtReqCmd" 2 "ImobEngMgrReqCmd_ImobEngNoMtnStrtReqCmd" 3 "ImobEngMgrReqCmd_ImobEngTurnOffCmd";
VAL_ 17 GearPrkgAssiReqGroupGearPrkgAssiReq1 0 "GearPrkgAssiReq1_NoRequest" 1 "GearPrkgAssiReq1_TargetgearP" 2 "GearPrkgAssiReq1_TargetgearR" 3 "GearPrkgAssiReq1_TargetgearD";
VAL_ 17 LgtCtrlModReqSafeLgtCtrlModReqSafe 0 "ModCfmd_NoReq" 1 "ModCfmd_Reserved1" 2 "ModCfmd_Reserved2" 3 "ModCfmd_Reserved3" 4 "ModCfmd_Reserved4" 5 "ModCfmd_Reserved5" 6 "ModCfmd_Reserved6" 7 "ModCfmd_Reserved7" 8 "ModCfmd_Reserved8" 9 "ModCfmd_ACC_HWA" 10 "ModCfmd_PEB" 11 "ModCfmd_APA" 12 "ModCfmd_RPA" 13 "ModCfmd_HPA" 14 "ModCfmd_TJP" 15 "ModCfmd_SHWA";
VAL_ 17 LgtCtrlModReqSafeLgtFctFailr 0 "LgtFctFail_NoFailure" 1 "LgtFctFail_TJPFailure" 2 "LgtFctFail_APAFailure" 3 "LgtFctFail_RPAFailure" 4 "LgtFctFail_HPAFailure" 5 "LgtFctFail_HWAFailure" 6 "LgtFctFail_SHWAFailure" 7 "LgtFctFail_Reserved3";
VAL_ 17 MvBattRlyStsMvBattRlySts 0 "BattRlySts_Open" 1 "BattRlySts_Clsd" 2 "BattRlySts_StuckOpen" 3 "BattRlySts_StuckClose";
VAL_ 17 PrpsnHvBattUsgModReq 0 "HvBattUsgType_NoReq" 1 "HvBattUsgType_Norm" 2 "HvBattUsgType_Hld" 3 "HvBattUsgType_HldSmt" 4 "HvBattUsgType_Chrg" 5 "HvBattUsgType_NotOfUse1" 6 "HvBattUsgType_NotOfUse2" 7 "HvBattUsgType_NotOfUse3";
VAL_ 496 StandStillMgrStsForHld1 0 "StandStillMgrStsForHld1_StandStillMgrStsForHldVal0" 1 "StandStillMgrStsForHld1_StandStillMgrStsForHldVal1" 2 "StandStillMgrStsForHld1_StandStillMgrStsForHldVal2" 3 "StandStillMgrStsForHld1_StandStillMgrStsForHldVal3" 4 "StandStillMgrStsForHld1_StandStillMgrStsForHldVal4" 5 "StandStillMgrStsForHld1_StandStillMgrStsForHldVal5" 6 "StandStillMgrStsForHld1_StandStillMgrStsForHldVal6" 7 "StandStillMgrStsForHld1_StandStillMgrStsForHldVal7";
VAL_ 439 WhlSpdCircumlReLeQf 0 "GenQf1_UndefindDataAccur" 1 "GenQf1_TmpUndefdData" 2 "GenQf1_DataAccurNotWithinSpcn" 3 "GenQf1_AccurData";
VAL_ 439 WhlSpdCircumlReRiQf 0 "GenQf1_UndefindDataAccur" 1 "GenQf1_TmpUndefdData" 2 "GenQf1_DataAccurNotWithinSpcn" 3 "GenQf1_AccurData";
VAL_ 52 CrashStsSafeSts 0 "CrashSts2_NoCrash" 1 "CrashSts2_Crash";
SIG_GROUP_ 400 AbsCtrlActv 1 : AbsCtrlActvChks AbsCtrlActvCntr AbsCtrlActvCtrlSts1;
SIG_GROUP_ 160 ADataRawSafe 1 : ADataRawSafeALat ADataRawSafeALat1Qf ADataRawSafeALgt ADataRawSafeALgt1Qf ADataRawSafeAVert ADataRawSafeAVertQf ADataRawSafeChks ADataRawSafeCntr;
SIG_GROUP_ 26 AgDataCmpQuality 1 : AgDataCmpQualityPitchRateCmpQuality AgDataCmpQualityRollRateCmpQuality AgDataCmpQualityYawRateCmpQuality;
SIG_GROUP_ 432 AgDataRawSafe 1 : AgDataRawSafeChks AgDataRawSafeCntr AgDataRawSafeRollRate AgDataRawSafeRollRateQf AgDataRawSafeYawRate AgDataRawSafeYawRateQf;
SIG_GROUP_ 1099 AmbTEstimd 1 : AmbTEstimdAmbTEstimd AmbTEstimdQf;
SIG_GROUP_ 928 AmbTIndcdWithUnit 1 : AmbTIndcdWithUnitAmbTIndcd AmbTIndcdWithUnitAmbTIndcdUnit AmbTIndcdWithUnitQF;
SIG_GROUP_ 400 AmbTRaw 1 : AmbTRawAmbTVal AmbTRawQly;
SIG_GROUP_ 81 AsyDataWithCmpSafe 1 : AsyDataWithCmpSafeALat1Qf AsyDataWithCmpSafeALatWithCmp AsyDataWithCmpSafeALgt1Qf AsyDataWithCmpSafeChks AsyDataWithCmpSafeCntr AsyDataWithCmpSafeGrdtOfALgt AsyDataWithCmpSafeYawRateQf AsyDataWithCmpSafeYawRateWithCmp;
SIG_GROUP_ 433 BrkPedlPsd 1 : BrkPedlPsdBrkPedlNotPsdSafe BrkPedlPsdBrkPedlPsd BrkPedlPsdChks BrkPedlPsdCntr BrkPedlPsdQf;
SIG_GROUP_ 784 CmptmtTFrnt 1 : CmptmtTFrntCmptmtTFrnt CmptmtTFrntFanForCmptmtTRunng CmptmtTFrntQf;
SIG_GROUP_ 928 CmptmtTRe 1 : CmptmtTReCmptmtTFrnt CmptmtTReCmptmtTFrntQf CmptmtTReFanForCmptmtTRunng;
SIG_GROUP_ 52 CrashStsSafe 1 : CrashStsSafeChks CrashStsSafeCntr CrashStsSafeSts;
SIG_GROUP_ 224 EngRunngReqByParkAssi 1 : EngRunngReqByParkAssi1 EngRunngReqByParkAssiChks EngRunngReqByParkAssiCntr;
SIG_GROUP_ 1267 EscSt 1 : EscStChks EscStCntr EscStEscSt;
SIG_GROUP_ 1123 EvaprTRe 1 : EvaprTReEvaprTFrnt EvaprTReEvaprTQf;
SIG_GROUP_ 17 GearPrkgAssiReqGroup 1 : GearPrkgAssiReqGroupChks GearPrkgAssiReqGroupCntr GearPrkgAssiReqGroupGearPrkgAssiReq1;
SIG_GROUP_ 1243 HvacAirTForRowFirstAtFlrLe 1 : HvacAirTForRowFirstAtFlrLeEvaprTFrnt HvacAirTForRowFirstAtFlrLeEvaprTQf;
SIG_GROUP_ 1243 HvacAirTForRowFirstAtFlrRi 1 : HvacAirTForRowFirstAtFlrRiEvaprTFrnt HvacAirTForRowFirstAtFlrRiEvaprTQf;
SIG_GROUP_ 1243 HvacAirTForRowFirstAtVentLe 1 : HvacAirTForRowFirstAtVentLeEvaprTFrnt HvacAirTForRowFirstAtVentLeEvaprTQf;
SIG_GROUP_ 1243 HvacAirTForRowFirstAtVentRi 1 : HvacAirTForRowFirstAtVentRiEvaprTFrnt HvacAirTForRowFirstAtVentRiEvaprTQf;
SIG_GROUP_ 1255 HvacAirTForRowSecAtFlrLe 1 : HvacAirTForRowSecAtFlrLeEvaprTFrnt HvacAirTForRowSecAtFlrLeEvaprTQf;
SIG_GROUP_ 1255 HvacAirTForRowSecAtFlrRi 1 : HvacAirTForRowSecAtFlrRiEvaprTFrnt HvacAirTForRowSecAtFlrRiEvaprTQf;
SIG_GROUP_ 1255 HvacAirTForRowSecAtVentLe 1 : HvacAirTForRowSecAtVentLeEvaprTFrnt HvacAirTForRowSecAtVentLeEvaprTQf;
SIG_GROUP_ 1255 HvacAirTForRowSecAtVentRi 1 : HvacAirTForRowSecAtVentRiEvaprTFrnt HvacAirTForRowSecAtVentRiEvaprTQf;
SIG_GROUP_ 1267 HvacCondsorT 1 : HvacCondsorTEvaprTFrnt HvacCondsorTEvaprTQf;
SIG_GROUP_ 1267 HvacCondsorTsp 1 : HvacCondsorTspEvaprTFrnt HvacCondsorTspEvaprTQf;
SIG_GROUP_ 864 HvacHeatrInletTempReq 1 : HvacHeatrInletTempReqEvaprTFrnt HvacHeatrInletTempReqEvaprTQf;
SIG_GROUP_ 686 HvacHexAirT 1 : HvacHexAirTHvacAirTForHeatrFrnt HvacHexAirTHvacAirTForHeatrFrntQf;
SIG_GROUP_ 580 IDcDcActLoSide 1 : IDcDcActLoSideChks IDcDcActLoSideCntr IDcDcActLoSideIDcDcActLoSide;
SIG_GROUP_ 513 ImobEngMgrReq3 1 : ImobEngMgrReq3ImobEngDataMgrReq0 ImobEngMgrReq3ImobEngDataMgrReq1 ImobEngMgrReq3ImobEngDataMgrReq2 ImobEngMgrReq3ImobEngDataMgrReq3 ImobEngMgrReq3ImobEngDataMgrReq4 ImobEngMgrReq3ImobEngDataMgrReq5 ImobEngMgrReq3ImobEngDataMgrReq6 ImobEngMgrReq3ImobEngMgrCmdTar1;
SIG_GROUP_ 400 LatCtrlReqSafe 1 : LatCtrlReqSafeChks LatCtrlReqSafeCntr LatCtrlReqSafeLatCtrlModReq LatCtrlReqSafeSteerTqReq LatCtrlReqSafeSteerWhlHptcWarnReq;
SIG_GROUP_ 17 LgtCtrlModReqSafe 1 : LgtCtrlModReqSafeChks LgtCtrlModReqSafeCntr LgtCtrlModReqSafeLgtCtrlModReqSafe LgtCtrlModReqSafeLgtFctFailr;
SIG_GROUP_ 17 MvBattRlySts 1 : MvBattRlyStsChks MvBattRlyStsCntr MvBattRlyStsMvBattRlySts;
SIG_GROUP_ 580 MvDcDcActLoSide 1 : MvDcDcActLoSideChks MvDcDcActLoSideCntr MvDcDcActLoSideI MvDcDcActLoSideU;
SIG_GROUP_ 496 StandStillMgrStsForHld 1 : StandStillMgrStsForHld1 StandStillMgrStsForHldChks StandStillMgrStsForHldCntr;
SIG_GROUP_ 1123 SteerSetg 1 : SteerSetgPen SteerSetgSteerAsscLvl SteerSetgSteerMod;
SIG_GROUP_ 128 TrsmActrPosn2 1 : TrsmActrPosn2TrsmActrPosn TrsmActrPosn2TrsmActrPosnChks TrsmActrPosn2TrsmActrPosnCntr;
SIG_GROUP_ 373 TrsmCluTqSafe 1 : TrsmCluTqSafeChks TrsmCluTqSafeCntr TrsmCluTqSafeCp1 TrsmCluTqSafeCp2;
SIG_GROUP_ 629 TrsmEngmtLimd 1 : TrsmEngmtLimdChks TrsmEngmtLimdCntr TrsmEngmtLimdTrsmEngmtLimd;
SIG_GROUP_ 512 TrsmEngmtLimd3 1 : TrsmEngmtLimd3TrsmEngmtLimd TrsmEngmtLimd3TrsmEngmtLimdChks TrsmEngmtLimd3TrsmEngmtLimdCntr;
SIG_GROUP_ 326 TrsmEngNTqMax 1 : TrsmEngNTqMaxChks TrsmEngNTqMaxCntr TrsmEngNTqMaxTrsmEngNTqMax;
SIG_GROUP_ 293 TrsmGearSafe 1 : TrsmGearSafeAct1 TrsmGearSafeAct2 TrsmGearSafeChks TrsmGearSafeCntr TrsmGearSafeSts1 TrsmGearSafeSts2;
SIG_GROUP_ 74 TrsmLockChk 1 : TrsmLockChkChk TrsmLockChkData0 TrsmLockChkData1 TrsmLockChkData2 TrsmLockChkData3 TrsmLockChkData4 TrsmLockChkData5 TrsmLockChkData6;
SIG_GROUP_ 367 TrsmLockMgrReq 1 : TrsmLockMgrReqCmd TrsmLockMgrReqData0 TrsmLockMgrReqData1 TrsmLockMgrReqData2 TrsmLockMgrReqData3 TrsmLockMgrReqData4 TrsmLockMgrReqData5 TrsmLockMgrReqData6;
SIG_GROUP_ 293 TrsmSailSts 1 : TrsmSailStsTrsmEngSyncSpd TrsmSailStsTrsmSailAllwd TrsmSailStsTrsmShiftMapForIsg TrsmSailStsTrsmSts;
SIG_GROUP_ 257 TrsmToPrpsnCluTqRec 1 : TrsmToPrpsnCluTqRecTrsmCluTqMaxFast TrsmToPrpsnCluTqRecTrsmCluTqMaxFastFlag TrsmToPrpsnCluTqRecTrsmCluTqMaxForProtn TrsmToPrpsnCluTqRecTrsmCluTqMaxForProtnFlag TrsmToPrpsnCluTqRecTrsmCluTqMaxSlow TrsmToPrpsnCluTqRecTrsmCluTqMaxSlowFlag TrsmToPrpsnCluTqRecTrsmCluTqMinFast TrsmToPrpsnCluTqRecTrsmCluTqMinFlag TrsmToPrpsnCluTqRecTrsmCluTqMinSlow;
SIG_GROUP_ 261 TrsmToPrpsnNReqRec 1 : TrsmToPrpsnNReqRecTrsmNReqCtrl TrsmToPrpsnNReqRecTrsmNReqMax TrsmToPrpsnNReqRecTrsmNReqMin;
SIG_GROUP_ 629 TrsmTqLoss 1 : TrsmTqLossChks TrsmTqLossCntr TrsmTqLossTrsmTqEff TrsmTqLossTrsmTqLoss;
SIG_GROUP_ 686 ULoWarn 1 : ULoWarnChks ULoWarnCntr ULoWarnULoWarn;
SIG_GROUP_ 1434 VDDMdevelpsignalgroupresp1 1 : VDDMdevelpsignalgroupresp1Functiondevpsignalgroup1 VDDMdevelpsignalgroupresp1Functiondevpsignalgroup2 VDDMdevelpsignalgroupresp1Functiondevpsignalgroup3 VDDMdevelpsignalgroupresp1Functiondevpsignalgroup4 VDDMdevelpsignalgroupresp1Functiondevpsignalgroup5 VDDMdevelpsignalgroupresp1Functiondevpsignalgroup6 VDDMdevelpsignalgroupresp1Functiondevpsignalgroup7 VDDMdevelpsignalgroupresp1Functiondevpsignalgroup8;
SIG_GROUP_ 1435 VDDMdevelpsignalgroupresp2 1 : VDDMdevelpsignalgroupresp2Functiondevpsignalgroup1 VDDMdevelpsignalgroupresp2Functiondevpsignalgroup2 VDDMdevelpsignalgroupresp2Functiondevpsignalgroup3 VDDMdevelpsignalgroupresp2Functiondevpsignalgroup4 VDDMdevelpsignalgroupresp2Functiondevpsignalgroup5 VDDMdevelpsignalgroupresp2Functiondevpsignalgroup6 VDDMdevelpsignalgroupresp2Functiondevpsignalgroup7 VDDMdevelpsignalgroupresp2Functiondevpsignalgroup8;
SIG_GROUP_ 896 VehBattU 1 : VehBattUSysU VehBattUSysUQf;
SIG_GROUP_ 592 VehCfgPrm 1 : VehCfgPrmBlkIDBytePosn1 VehCfgPrmCCPBytePosn2 VehCfgPrmCCPBytePosn3 VehCfgPrmCCPBytePosn4 VehCfgPrmCCPBytePosn5 VehCfgPrmCCPBytePosn6 VehCfgPrmCCPBytePosn7 VehCfgPrmCCPBytePosn8;
SIG_GROUP_ 1015 VehCfgPrmExt 1 : VehCfgPrmExtBlkIDBytePosn1 VehCfgPrmExtCCPBytePosn2 VehCfgPrmExtCCPBytePosn3 VehCfgPrmExtCCPBytePosn4 VehCfgPrmExtCCPBytePosn5 VehCfgPrmExtCCPBytePosn6 VehCfgPrmExtCCPBytePosn7 VehCfgPrmExtCCPBytePosn8;
SIG_GROUP_ 736 VehModMngtGlbSafe1 1 : VehModMngtGlbSafe1CarModSts1 VehModMngtGlbSafe1CarModSubtypWdCarModSubtyp VehModMngtGlbSafe1Chks VehModMngtGlbSafe1Cntr VehModMngtGlbSafe1EgyLvlElecMai VehModMngtGlbSafe1EgyLvlElecSubtyp VehModMngtGlbSafe1FltEgyCnsWdSts VehModMngtGlbSafe1PwrLvlElecMai VehModMngtGlbSafe1PwrLvlElecSubtyp VehModMngtGlbSafe1UsgModSts;
SIG_GROUP_ 1159 VehMtnSt 1 : VehMtnStChks VehMtnStCntr VehMtnStVehMtnSt;
SIG_GROUP_ 224 VehSpdLgt 1 : VehSpdLgtA VehSpdLgtChks VehSpdLgtCntr VehSpdLgtQf;
SIG_GROUP_ 1352 VFCVectorTCM 1 : VFCVectorTCMBlockID VFCVectorTCMVFCid0 VFCVectorTCMVFCid1 VFCVectorTCMVFCid10 VFCVectorTCMVFCid11 VFCVectorTCMVFCid12 VFCVectorTCMVFCid13 VFCVectorTCMVFCid14 VFCVectorTCMVFCid15 VFCVectorTCMVFCid16 VFCVectorTCMVFCid17 VFCVectorTCMVFCid18 VFCVectorTCMVFCid19 VFCVectorTCMVFCid2 VFCVectorTCMVFCid20 VFCVectorTCMVFCid21 VFCVectorTCMVFCid22 VFCVectorTCMVFCid23 VFCVectorTCMVFCid24 VFCVectorTCMVFCid25 VFCVectorTCMVFCid26 VFCVectorTCMVFCid27 VFCVectorTCMVFCid28 VFCVectorTCMVFCid29 VFCVectorTCMVFCid3 VFCVectorTCMVFCid30 VFCVectorTCMVFCid31 VFCVectorTCMVFCid32 VFCVectorTCMVFCid33 VFCVectorTCMVFCid34 VFCVectorTCMVFCid35 VFCVectorTCMVFCid36 VFCVectorTCMVFCid37 VFCVectorTCMVFCid38 VFCVectorTCMVFCid39 VFCVectorTCMVFCid4 VFCVectorTCMVFCid40 VFCVectorTCMVFCid41 VFCVectorTCMVFCid42 VFCVectorTCMVFCid43 VFCVectorTCMVFCid44 VFCVectorTCMVFCid45 VFCVectorTCMVFCid46 VFCVectorTCMVFCid47 VFCVectorTCMVFCid48 VFCVectorTCMVFCid49 VFCVectorTCMVFCid5 VFCVectorTCMVFCid50 VFCVectorTCMVFCid51 VFCVectorTCMVFCid52 VFCVectorTCMVFCid53 VFCVectorTCMVFCid54 VFCVectorTCMVFCid55 VFCVectorTCMVFCid56 VFCVectorTCMVFCid57 VFCVectorTCMVFCid58 VFCVectorTCMVFCid59 VFCVectorTCMVFCid6 VFCVectorTCMVFCid60 VFCVectorTCMVFCid61 VFCVectorTCMVFCid7 VFCVectorTCMVFCid8 VFCVectorTCMVFCid9;
SIG_GROUP_ 763 VFCVectorTCMAW 1 : VFCVectorTCMAWBlockID VFCVectorTCMAWVFCid0 VFCVectorTCMAWVFCid1 VFCVectorTCMAWVFCid10 VFCVectorTCMAWVFCid11 VFCVectorTCMAWVFCid12 VFCVectorTCMAWVFCid13 VFCVectorTCMAWVFCid14 VFCVectorTCMAWVFCid15 VFCVectorTCMAWVFCid16 VFCVectorTCMAWVFCid17 VFCVectorTCMAWVFCid18 VFCVectorTCMAWVFCid19 VFCVectorTCMAWVFCid2 VFCVectorTCMAWVFCid20 VFCVectorTCMAWVFCid21 VFCVectorTCMAWVFCid22 VFCVectorTCMAWVFCid23 VFCVectorTCMAWVFCid24 VFCVectorTCMAWVFCid25 VFCVectorTCMAWVFCid26 VFCVectorTCMAWVFCid27 VFCVectorTCMAWVFCid28 VFCVectorTCMAWVFCid29 VFCVectorTCMAWVFCid3 VFCVectorTCMAWVFCid30 VFCVectorTCMAWVFCid31 VFCVectorTCMAWVFCid32 VFCVectorTCMAWVFCid33 VFCVectorTCMAWVFCid34 VFCVectorTCMAWVFCid35 VFCVectorTCMAWVFCid36 VFCVectorTCMAWVFCid37 VFCVectorTCMAWVFCid38 VFCVectorTCMAWVFCid39 VFCVectorTCMAWVFCid4 VFCVectorTCMAWVFCid40 VFCVectorTCMAWVFCid41 VFCVectorTCMAWVFCid42 VFCVectorTCMAWVFCid43 VFCVectorTCMAWVFCid44 VFCVectorTCMAWVFCid45 VFCVectorTCMAWVFCid46 VFCVectorTCMAWVFCid47 VFCVectorTCMAWVFCid48 VFCVectorTCMAWVFCid49 VFCVectorTCMAWVFCid5 VFCVectorTCMAWVFCid50 VFCVectorTCMAWVFCid51 VFCVectorTCMAWVFCid52 VFCVectorTCMAWVFCid53 VFCVectorTCMAWVFCid54 VFCVectorTCMAWVFCid55 VFCVectorTCMAWVFCid56 VFCVectorTCMAWVFCid57 VFCVectorTCMAWVFCid58 VFCVectorTCMAWVFCid59 VFCVectorTCMAWVFCid6 VFCVectorTCMAWVFCid60 VFCVectorTCMAWVFCid61 VFCVectorTCMAWVFCid7 VFCVectorTCMAWVFCid8 VFCVectorTCMAWVFCid9;
SIG_GROUP_ 137 WhlFastSpdSafe 1 : WhlFastSpdSafeA WhlFastSpdSafeChks WhlFastSpdSafeCntr WhlFastSpdSafeQF;
SIG_GROUP_ 1099 WhlRotToothCntr 1 : WhlRotToothCntrChks WhlRotToothCntrCntr WhlRotToothCntrFrntLe WhlRotToothCntrFrntRi WhlRotToothCntrReLe WhlRotToothCntrReRi;
SIG_GROUP_ 433 WhlSpdCircumlFrnt 1 : WhlSpdCircumlFrntChks WhlSpdCircumlFrntCntr WhlSpdCircumlFrntLe WhlSpdCircumlFrntLeQf WhlSpdCircumlFrntRiQf WhlSpdCircumlFrntWhlSpdCircumlFrntRi;
SIG_GROUP_ 439 WhlSpdCircumlRe 1 : WhlSpdCircumlReChks WhlSpdCircumlReCntr WhlSpdCircumlReLe WhlSpdCircumlReLeQf WhlSpdCircumlReRi WhlSpdCircumlReRiQf;
